VERSION "created by canmatrix"

NS_ :

BS_:

BU_: DiagTool_OBD1 DiwaNXT EBS IRCS MulticII NBM VCM ETS NODE_45 FCCU DICO SGW2 HV_BOX ADCU AEBS DTCO MBMS SGW TPMS ACU CAID2 ELC5_Fr ELC5_Rr PredictiveVirtualNode2 BPU_3 Servo_dir_Turolla PCM NODE_90 NODE_91 NODE_92 RSRRM FCU DSE_VirtualNode2 DSE_VirtualNode40 DSE_VirtualNode38 DSE_VirtualNode49 DSE_VirtualNode48 DSE_VirtualNode39 DSE_VirtualNode37 DSE_VirtualNode36 BSM_B8 BPU_2 DSE_VirtualNode35 DSE_VirtualNode34 RADAR_ACC DSE_VirtualNode33 DSE_VirtualNode41 NODE_BE DSE_VirtualNode32 DSE_VirtualNode4 BSM_C0 BPU_1 DSE_VirtualNode31 DSE_VirtualNode29 DSE_VirtualNode28 MCDS DSE_VirtualNode44 DSE_VirtualNode27 DSE_VirtualNode26 BSM_C8 ALM DSE_VirtualNode25 DSE_VirtualNode50 DSE_VirtualNode47 DSE_VirtualNode46 DSE_VirtualNode23 DSE_VirtualNode51 ScanTool DSE_VirtualNode22 DSE_VirtualNode21 AePTO DC_VirtualNode1 DSE_VirtualNode43 MCSL DSE_VirtualNode1 DSE_VirtualNode42 PredictiveVirtualNode3 DSE_VirtualNode20 DSE_VirtualNode19 DSE_VirtualNode18 DSE_VirtualNode17 DSE_VirtualNode16 DSE_VirtualNode15 NODE_F9 DiagTool DSE_VirtualNode14 DSE_VirtualNode13 DSE_VirtualNode12 DSE_VirtualNode11 DSE_VirtualNode10 DSE_VirtualNode9 DSE_VirtualNode8 DSE_VirtualNode7 DSE_VirtualNode6 Mirror DSE_VirtualNode5 SAS DC_VirtualNode2 PredictiveVirtualNode1 DSE_VirtualNode45 ELFA3 EM_PTO RM CANAIR SWI

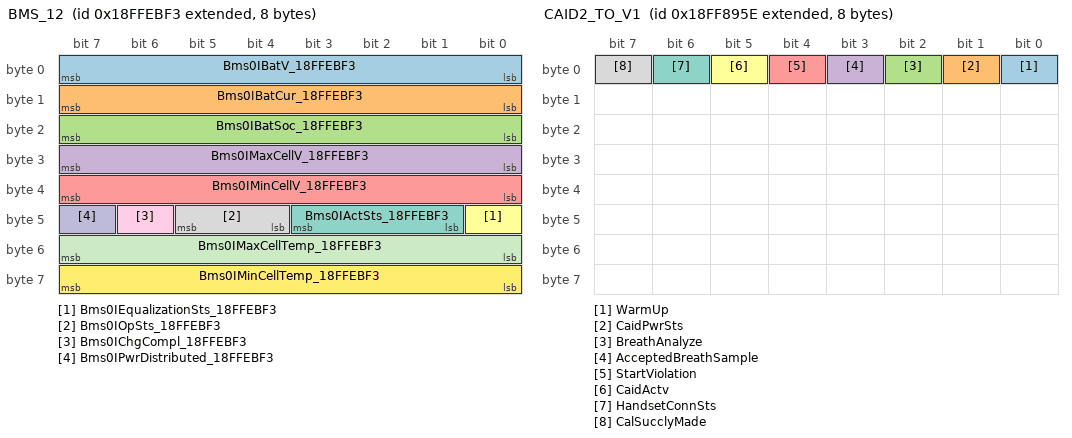
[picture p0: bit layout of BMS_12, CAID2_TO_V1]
BO_ 2566908915 BMS_12: 8 MBMS
 SG_ Bms0IBatV_18FFEBF3 : 0|8@1+ (3.4,0) [0|850] "V"  PCM
 SG_ Bms0IBatCur_18FFEBF3 : 8|8@1+ (4,-500) [-500|500] "A"  PCM
 SG_ Bms0IBatSoc_18FFEBF3 : 16|8@1+ (0.4,0) [0|100] "%"  PCM
 SG_ Bms0IMaxCellV_18FFEBF3 : 24|8@1+ (20,0) [0|5000] "Mv"  PCM
 SG_ Bms0IMinCellV_18FFEBF3 : 32|8@1+ (20,0) [0|5000] "Mv"  PCM
 SG_ Bms0IEqualizationSts_18FFEBF3 : 40|1@1+ (1,0) [0|1] ""  PCM
 SG_ Bms0IActSts_18FFEBF3 : 41|3@1+ (1,0) [0|7] ""  PCM
 SG_ Bms0IOpSts_18FFEBF3 : 44|2@1+ (1,0) [0|3] ""  PCM
 SG_ Bms0IChgCompl_18FFEBF3 : 46|1@1+ (1,0) [0|1] ""  PCM
 SG_ Bms0IPwrDistributed_18FFEBF3 : 47|1@1+ (1,0) [0|1] ""  PCM
 SG_ Bms0IMaxCellTemp_18FFEBF3 : 48|8@1+ (1,-40) [-40|210] " °C"  PCM
 SG_ Bms0IMinCellTemp_18FFEBF3 : 56|8@1+ (1,-40) [-40|210] " °C"  PCM

BO_ 2566883678 CAID2_TO_V1: 8 CAID2
 SG_ WarmUp : 0|1@1+ (1,0) [0|1] ""  PCM
 SG_ CaidPwrSts : 1|1@1+ (1,0) [0|1] ""  PCM
 SG_ BreathAnalyze : 2|1@1+ (1,0) [0|1] ""  PCM
 SG_ AcceptedBreathSample : 3|1@1+ (1,0) [0|1] ""  PCM
 SG_ StartViolation : 4|1@1+ (1,0) [0|1] ""  PCM
 SG_ CaidActv : 5|1@1+ (1,0) [0|1] ""  PCM
 SG_ HandsetConnSts : 6|1@1+ (1,0) [0|1] ""  PCM
 SG_ CalSucclyMade : 7|1@1+ (1,0) [0|1] ""  PCM

BO_ 2566884190 CAID2_TO_V3: 8 CAID2
 SG_ DeferredData : 48|8@1+ (1,0) [0|250] ""  PCM

BO_ 2566843648 CCSS_00: 8 DiagTool_OBD1
 SG_ MaxVsl : 0|8@1+ (1,0) [0|250] "km/h"  PCM
 SG_ DcdcCurSetPnt24VSide : 56|8@1+ (1,0) [0|250] "A"  PCM

BO_ 2566843676 CCSS_1C: 8 PCM
 SG_ MaxVsl_18FEED1C : 0|8@1+ (1,0) [0|250] "km/h" Vector__XXX

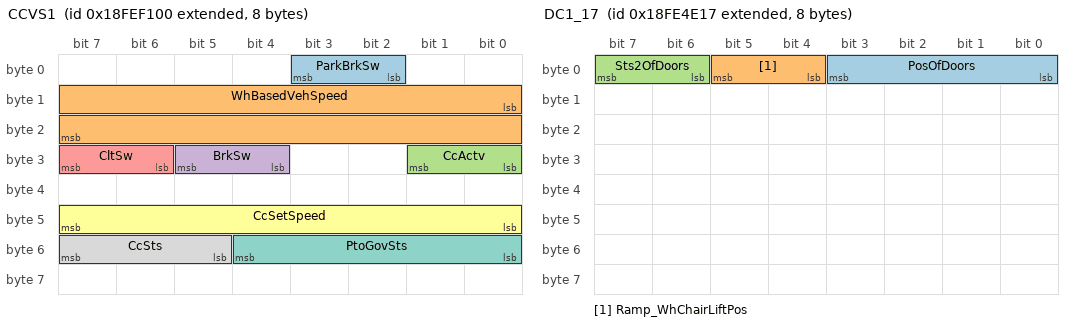
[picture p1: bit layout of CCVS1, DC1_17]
BO_ 2566844672 CCVS1: 8 DiagTool_OBD1
 SG_ ParkBrkSw : 2|2@1+ (1,0) [0|3] ""  PCM
 SG_ WhBasedVehSpeed : 8|16@1+ (0.00390625,0) [0|250] "km/h"  PCM
 SG_ CcActv : 24|2@1+ (1,0) [0|3] ""  PCM
 SG_ BrkSw : 28|2@1+ (1,0) [0|3] ""  PCM
 SG_ CltSw : 30|2@1+ (1,0) [0|3] ""  PCM
 SG_ CcSetSpeed : 40|8@1+ (1,0) [0|250] "km/h"  PCM
 SG_ PtoGovSts : 48|5@1+ (1,0) [0|31] ""  PCM
 SG_ CcSts : 53|3@1+ (1,0) [0|7] ""  PCM

BO_ 2566890313 ChargerFaults: 8 FCCU
 SG_ LastStopCause : 24|8@1+ (1,0) [0|250] ""  PCM
 SG_ BefLastStopCause : 32|8@1+ (1,0) [0|250] ""  PCM

BO_ 2566843164 CI_1C: 609 PCM
 SG_ Make : 0|8@1+ (1,0) [0|255] "ASCII" Vector__XXX
 SG_ Model : 8|8@1+ (1,0) [0|255] "ASCII" Vector__XXX
 SG_ Sn : 16|8@1+ (1,0) [0|255] "ASCII" Vector__XXX
 SG_ UnitNumPwrUnit : 24|8@1+ (1,0) [0|255] "ASCII" Vector__XXX

BO_ 2566843165 CI_1D: 609 SGW
 SG_ Make_18FEEB1D : 0|8@1+ (1,0) [0|255] "ASCII"  PCM
 SG_ Model_18FEEB1D : 8|8@1+ (1,0) [0|255] "ASCII"  PCM
 SG_ Sn_18FEEB1D : 16|8@1+ (1,0) [0|255] "ASCII"  PCM
 SG_ UnitNumPwrUnit_18FEEB1D : 24|8@1+ (1,0) [0|255] "ASCII"  PCM

BO_ 2566843230 CI_5E: 609 CAID2
 SG_ Model_18FEEB5E : 8|8@1+ (1,0) [0|255] "ASCII"  PCM

BO_ 2566865139 Clim_LTO_Sts: 8 MBMS
 SG_ CoolSts : 4|4@1+ (1,0) [0|7] ""  PCM

BO_ 2566811659 CVW_0B: 8 EBS
 SG_ Gcvw : 16|16@1+ (10,0) [0|642550] "kg"  PCM

BO_ 2566811695 CVW_2F: 8 ELC5_Fr
 SG_ Gcvw_18FE702F : 16|16@1+ (10,0) [0|642550] "kg"  PCM

BO_ 2566802967 DC1_17: 8 MulticII
 SG_ PosOfDoors : 0|4@1+ (1,0) [0|15] ""  PCM
 SG_ Ramp_WhChairLiftPos : 4|2@1+ (1,0) [0|3] ""  PCM
 SG_ Sts2OfDoors : 6|2@1+ (1,0) [0|3] ""  PCM

BO_ 2566759703 DC2_17: 8 MulticII
 SG_ LckStsOfDoor1 : 0|2@1+ (1,0) [0|3] ""  PCM
 SG_ OpenStsOfDoor1 : 2|2@1+ (1,0) [0|3] ""  PCM
 SG_ EnaStsOfDoor1 : 4|2@1+ (1,0) [0|3] ""  PCM
 SG_ LckStsOfDoor2 : 6|2@1+ (1,0) [0|3] ""  PCM
 SG_ OpenStsOfDoor2 : 8|2@1+ (1,0) [0|3] ""  PCM
 SG_ EnaStsOfDoor2 : 10|2@1+ (1,0) [0|3] ""  PCM
 SG_ LckStsOfDoor3 : 12|2@1+ (1,0) [0|3] ""  PCM
 SG_ OpenStsOfDoor3 : 14|2@1+ (1,0) [0|3] ""  PCM
 SG_ EnaStsOfDoor3 : 16|2@1+ (1,0) [0|3] ""  PCM
 SG_ LckStsOfDoor4 : 18|2@1+ (1,0) [0|3] ""  PCM
 SG_ OpenStsOfDoor4 : 20|2@1+ (1,0) [0|3] ""  PCM
 SG_ EnaStsOfDoor4 : 22|2@1+ (1,0) [0|3] ""  PCM
 SG_ LckStsOfDoor5 : 24|2@1+ (1,0) [0|3] ""  PCM
 SG_ OpenStsOfDoor5 : 26|2@1+ (1,0) [0|3] ""  PCM
 SG_ EnaStsOfDoor5 : 28|2@1+ (1,0) [0|3] ""  PCM
 SG_ LckStsOfDoor6 : 30|2@1+ (1,0) [0|3] ""  PCM
 SG_ OpenStsOfDoor6 : 32|2@1+ (1,0) [0|3] ""  PCM
 SG_ EnaStsOfDoor6 : 34|2@1+ (1,0) [0|3] ""  PCM
 SG_ LckStsOfDoor7 : 36|2@1+ (1,0) [0|3] ""  PCM
 SG_ OpenStsOfDoor7 : 38|2@1+ (1,0) [0|3] ""  PCM
 SG_ EnaStsOfDoor7 : 40|2@1+ (1,0) [0|3] ""  PCM
 SG_ LckStsOfDoor8 : 42|2@1+ (1,0) [0|3] ""  PCM
 SG_ OpenStsOfDoor8 : 44|2@1+ (1,0) [0|3] ""  PCM
 SG_ EnaStsOfDoor8 : 46|2@1+ (1,0) [0|3] ""  PCM
 SG_ LckStsOfDoor9 : 48|2@1+ (1,0) [0|3] ""  PCM
 SG_ OpenStsOfDoor9 : 50|2@1+ (1,0) [0|3] ""  PCM
 SG_ EnaStsOfDoor9 : 52|2@1+ (1,0) [0|3] ""  PCM
 SG_ LckStsOfDoor10 : 54|2@1+ (1,0) [0|3] ""  PCM
 SG_ OpenStsOfDoor10 : 56|2@1+ (1,0) [0|3] ""  PCM
 SG_ EnaStsOfDoor10 : 58|2@1+ (1,0) [0|3] ""  PCM

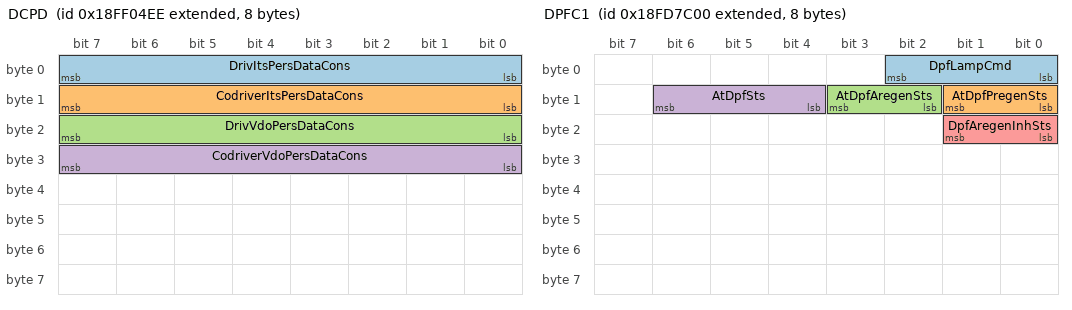
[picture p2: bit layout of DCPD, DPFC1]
BO_ 2566849774 DCPD: 8 DTCO
 SG_ DrivItsPersDataCons : 0|8@1+ (1,0) [0|250] ""  PCM
 SG_ CodriverItsPersDataCons : 8|8@1+ (1,0) [0|250] ""  PCM
 SG_ DrivVdoPersDataCons : 16|8@1+ (1,0) [0|250] ""  PCM
 SG_ CodriverVdoPersDataCons : 24|8@1+ (1,0) [0|250] ""  PCM

BO_ 2566847521 DD1_21: 8 NBM
 SG_ FuelLev1 : 8|8@1+ (0.4,0) [0|100] "%"  PCM

BO_ 2566810606 DI_EE: 40 DTCO
 SG_ Driv1Id : 0|8@1+ (1,0) [0|255] "ASCII"  PCM
 SG_ Driv2Id : 8|8@1+ (1,0) [0|255] "ASCII"  PCM

BO_ 2566834688 DM01_00: 82 DiagTool_OBD1
 SG_ ProtLamp : 0|2@1+ (1,0) [0|3] ""  PCM

BO_ 2566834691 DM01_03: 42 DiwaNXT
 SG_ ProtLamp_18FECA03 : 0|2@1+ (1,0) [0|3] ""  PCM

BO_ 2566834699 DM01_0B: 42 EBS
 SG_ ProtLamp_18FECA0B : 0|2@1+ (1,0) [0|3] ""  PCM

BO_ 2566834704 DM01_10: 66 IRCS
 SG_ ProtLamp_18FECA10 : 0|2@1+ (1,0) [0|3] ""  PCM

BO_ 2566834711 DM01_17: 82 MulticII
 SG_ ProtLamp_18FECA17 : 0|2@1+ (1,0) [0|3] ""  PCM

BO_ 2566834716 DM01_1C: 42 PCM
 SG_ ProtLamp_18FECA1C : 0|2@1+ (1,0) [0|3] "" Vector__XXX

BO_ 2566834717 DM01_1D: 42 SGW
 SG_ ProtLamp_18FECA1D : 0|2@1+ (1,0) [0|3] ""  PCM

BO_ 2566834721 DM01_21: 42 NBM
 SG_ ProtLamp_18FECA21 : 0|2@1+ (1,0) [0|3] ""  PCM

BO_ 2566834727 DM01_27: 42 VCM
 SG_ ProtLamp_18FECA27 : 0|2@1+ (1,0) [0|3] ""  PCM

BO_ 2566834734 DM01_2E: 42 Servo_dir_Turolla
 SG_ ProtLamp_18FECA2E : 0|2@1+ (1,0) [0|3] ""  PCM

BO_ 2566834735 DM01_2F: 42 ELC5_Fr
 SG_ ProtLamp_18FECA2F : 0|2@1+ (1,0) [0|3] ""  PCM

BO_ 2566834739 DM01_33: 42 TPMS
 SG_ ProtLamp_18FECA33 : 0|2@1+ (1,0) [0|3] ""  PCM

BO_ 2566834744 DM01_38: 42 ETS
 SG_ ProtLamp_18FECA38 : 0|2@1+ (1,0) [0|3] ""  PCM

BO_ 2566834752 DM01_40: 42 ELC5_Rr
 SG_ ProtLamp_18FECA40 : 0|2@1+ (1,0) [0|3] ""  PCM

BO_ 2566834761 DM01_49: 42 FCCU
 SG_ ProtLamp_18FECA49 : 0|2@1+ (1,0) [0|3] ""  PCM

BO_ 2566834762 DM01_4A: 42 PCM
 SG_ ProtLamp_18FECA4A : 0|2@1+ (1,0) [0|3] "" Vector__XXX

BO_ 2566834778 DM01_5A: 42 DICO
 SG_ ProtLamp_18FECA5A : 0|2@1+ (1,0) [0|3] ""  PCM

BO_ 2566834782 DM01_5E: 42 CAID2
 SG_ ProtLamp_18FECA5E : 0|2@1+ (1,0) [0|3] ""  PCM

BO_ 2566834814 DM01_7E: 42 SGW2
 SG_ ProtLamp_18FECA7E : 0|2@1+ (1,0) [0|3] ""  PCM

BO_ 2566834832 DM01_90: 42 NODE_90
 SG_ ProtLamp_18FECA90 : 0|2@1+ (1,0) [0|3] ""  PCM

BO_ 2566834833 DM01_91: 42 NODE_91
 SG_ ProtLamp_18FECA91 : 0|2@1+ (1,0) [0|3] ""  PCM

BO_ 2566834834 DM01_92: 42 NODE_92
 SG_ ProtLamp_18FECA92 : 0|2@1+ (1,0) [0|3] ""  PCM

BO_ 2566834844 DM01_9C: 42 RSRRM
 SG_ ProtLamp_18FECA9C : 0|2@1+ (1,0) [0|3] ""  PCM

BO_ 2566834846 DM01_9E: 42 ADCU
 SG_ ProtLamp_18FECA9E : 0|2@1+ (1,0) [0|3] ""  PCM

BO_ 2566834848 DM01_A0: 42 AEBS
 SG_ ProtLamp_18FECAA0 : 0|2@1+ (1,0) [0|3] ""  PCM

BO_ 2566834882 DM01_C2: 18 FCU
 SG_ ProtLamp_18FECAC2 : 0|2@1+ (1,0) [0|3] ""  PCM

BO_ 2566834920 DM01_E8: 42 DSE_VirtualNode2
 SG_ ProtLamp_18FECAE8 : 0|2@1+ (1,0) [0|3] ""  PCM

BO_ 2566834926 DM01_EE: 42 DTCO
 SG_ ProtLamp_18FECAEE : 0|2@1+ (1,0) [0|3] ""  PCM

BO_ 2566834931 DM01_F3: 42 MBMS
 SG_ ProtLamp_18FECAF3 : 0|2@1+ (1,0) [0|3] ""  PCM

BO_ 2566834972 DM02_1C: 42 PCM
 SG_ ProtLamp_18FECB1C : 0|2@1+ (1,0) [0|3] "" Vector__XXX

BO_ 2566834973 DM02_1D: 42 SGW
 SG_ ProtLamp_18FECB1D : 0|2@1+ (1,0) [0|3] ""  PCM

BO_ 2566835102 DM02_9E: 42 ADCU
 SG_ ProtLamp_18FECB9E : 0|2@1+ (1,0) [0|3] ""  PCM

BO_ 2566835485 DM04_1D: 250 SGW
 SG_ FfLen1 : 0|8@1+ (1,0) [0|255] "count"  PCM

BO_ 2566835614 DM04_9E: 250 ADCU
 SG_ FfLen1_18FECD9E : 0|8@1+ (1,0) [0|255] "count"  PCM

BO_ 2633943642 DM1_5A_P7: 42 DICO
 SG_ ProtLamp_1CFECA5A : 0|2@1+ (1,0) [0|3] ""  PCM

BO_ 2633943680 DM1_80_P7: 42 HV_BOX
 SG_ ProtLamp_1CFECA80 : 0|2@1+ (1,0) [0|3] ""  PCM

BO_ 2566856773 DoorsStat: 8 NODE_45
 SG_ DoorId M : 0|8@1+ (1,0) [0|7] ""  PCM
 SG_ DoorCnt0 m0 : 8|24@1+ (1,0) [0|6291455] "Cy"  PCM
 SG_ DoorCnt1 m1 : 8|24@1+ (1,0) [0|6291455] "Cy"  PCM
 SG_ DoorCnt2 m2 : 8|24@1+ (1,0) [0|6291455] "Cy"  PCM
 SG_ DoorCnt3 m3 : 8|24@1+ (1,0) [0|6291455] "Cy"  PCM
 SG_ DoorCnt4 m4 : 8|24@1+ (1,0) [0|6291455] "Cy"  PCM
 SG_ DoorClosTime0 m0 : 32|8@1+ (100,0) [0|20000] "ms"  PCM
 SG_ DoorClosTime1 m1 : 32|8@1+ (100,0) [0|20000] "ms"  PCM
 SG_ DoorClosTime2 m2 : 32|8@1+ (100,0) [0|20000] "ms"  PCM
 SG_ DoorClosTime3 m3 : 32|8@1+ (100,0) [0|20000] "ms"  PCM
 SG_ DoorClosTime4 m4 : 32|8@1+ (100,0) [0|20000] "ms"  PCM

BO_ 2566749184 DPFC1: 8 DiagTool_OBD1
 SG_ DpfLampCmd : 0|3@1+ (1,0) [0|7] ""  PCM
 SG_ AtDpfPregenSts : 8|2@1+ (1,0) [0|3] ""  PCM
 SG_ AtDpfAregenSts : 10|2@1+ (1,0) [0|3] ""  PCM
 SG_ AtDpfSts : 12|3@1+ (1,0) [0|7] ""  PCM
 SG_ DpfAregenInhSts : 16|2@1+ (1,0) [0|3] ""  PCM

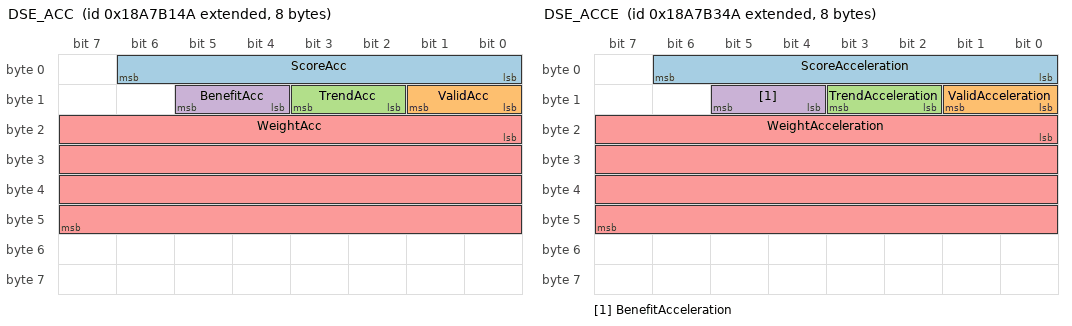
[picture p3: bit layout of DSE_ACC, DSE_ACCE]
BO_ 2561126730 DSE_ACC: 8 PCM
 SG_ ScoreAcc : 0|7@1+ (1,-1) [-1|126] ""  DSE_VirtualNode40
 SG_ ValidAcc : 8|2@1+ (1,0) [0|3] ""  DSE_VirtualNode40
 SG_ TrendAcc : 10|2@1+ (1,-1) [-1|2] ""  DSE_VirtualNode40
 SG_ BenefitAcc : 12|2@1+ (1,0) [0|3] ""  DSE_VirtualNode40
 SG_ WeightAcc : 16|32@1+ (1,-1) [-1|4294967294] ""  DSE_VirtualNode40

BO_ 2561126986 DSE_ACC_DBG: 8 PCM
 SG_ EvaluatedSamplesAcc : 0|16@1+ (1,-1) [-1|65534] ""  DSE_VirtualNode38
 SG_ EventAcc : 16|2@1+ (1,0) [0|3] ""  DSE_VirtualNode38

BO_ 2561127242 DSE_ACCE: 8 PCM
 SG_ ScoreAcceleration : 0|7@1+ (1,-1) [-1|126] ""  DSE_VirtualNode49
 SG_ ValidAcceleration : 8|2@1+ (1,0) [0|3] ""  DSE_VirtualNode49
 SG_ TrendAcceleration : 10|2@1+ (1,-1) [-1|2] ""  DSE_VirtualNode49
 SG_ BenefitAcceleration : 12|2@1+ (1,0) [0|3] ""  DSE_VirtualNode49
 SG_ WeightAcceleration : 16|32@1+ (1,-1) [-1|4294967294] ""  DSE_VirtualNode49

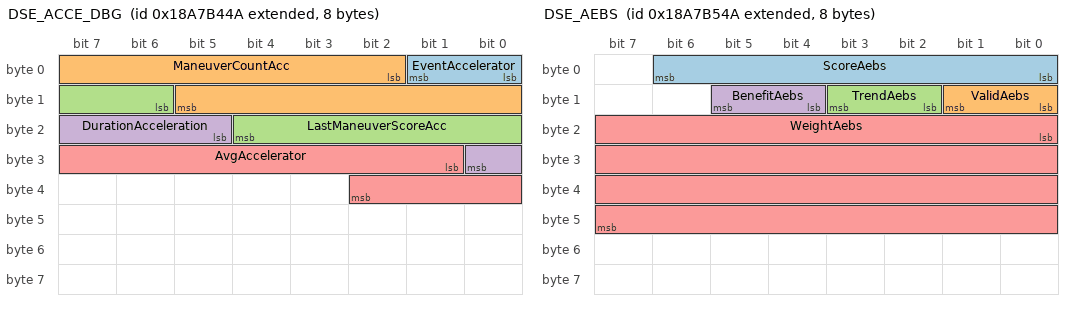
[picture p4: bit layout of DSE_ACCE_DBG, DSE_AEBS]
BO_ 2561127498 DSE_ACCE_DBG: 8 PCM
 SG_ EventAccelerator : 0|2@1+ (1,0) [0|3] ""  DSE_VirtualNode48
 SG_ ManeuverCountAcc : 2|12@1+ (1,-1) [-1|4094] "Count"  DSE_VirtualNode48
 SG_ LastManeuverScoreAcc : 14|7@1+ (1,-1) [-1|126] "Index"  DSE_VirtualNode48
 SG_ DurationAcceleration : 21|4@1+ (1,-1) [-1|14] "s"  DSE_VirtualNode48
 SG_ AvgAccelerator : 25|10@1+ (0.1,-1) [-1|101] "%"  DSE_VirtualNode48

BO_ 2561127754 DSE_AEBS: 8 PCM
 SG_ ScoreAebs : 0|7@1+ (1,-1) [-1|126] ""  DSE_VirtualNode39
 SG_ ValidAebs : 8|2@1+ (1,0) [0|3] ""  DSE_VirtualNode39
 SG_ TrendAebs : 10|2@1+ (1,-1) [-1|2] ""  DSE_VirtualNode39
 SG_ BenefitAebs : 12|2@1+ (1,0) [0|3] ""  DSE_VirtualNode39
 SG_ WeightAebs : 16|32@1+ (1,-1) [-1|4294967294] ""  DSE_VirtualNode39

BO_ 2561128010 DSE_AEBS_DBG: 8 PCM
 SG_ EvaluatedSamplesAebs : 0|16@1+ (1,-1) [-1|65534] ""  DSE_VirtualNode37
 SG_ EventAebs : 16|2@1+ (1,0) [0|3] ""  DSE_VirtualNode37

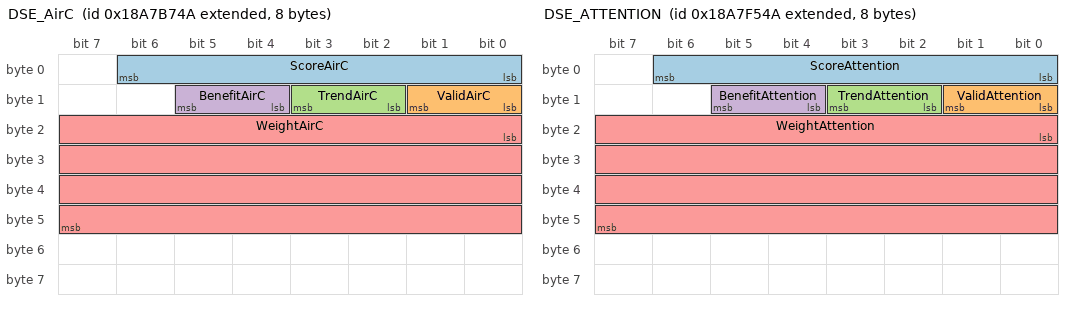
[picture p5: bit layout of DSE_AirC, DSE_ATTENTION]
BO_ 2561128266 DSE_AirC: 8 PCM
 SG_ ScoreAirC : 0|7@1+ (1,-1) [-1|126] ""  DSE_VirtualNode36
 SG_ ValidAirC : 8|2@1+ (1,0) [0|3] ""  DSE_VirtualNode36
 SG_ TrendAirC : 10|2@1+ (1,-1) [-1|2] ""  DSE_VirtualNode36
 SG_ BenefitAirC : 12|2@1+ (1,0) [0|3] ""  DSE_VirtualNode36
 SG_ WeightAirC : 16|32@1+ (1,-1) [-1|4294967294] ""  DSE_VirtualNode36

BO_ 2561128522 DSE_AirC_DBG: 8 PCM
 SG_ EvaluatedSamplesAirC : 0|16@1+ (1,-1) [-1|65534] ""  BSM_B8

BO_ 2561144138 DSE_ATTENTION: 8 PCM
 SG_ ScoreAttention : 0|7@1+ (1,-1) [-1|126] ""  BPU_2
 SG_ ValidAttention : 8|2@1+ (1,0) [0|3] ""  BPU_2
 SG_ TrendAttention : 10|2@1+ (1,-1) [-1|2] ""  BPU_2
 SG_ BenefitAttention : 12|2@1+ (1,0) [0|3] ""  BPU_2
 SG_ WeightAttention : 16|32@1+ (1,-1) [-1|4294967294] ""  BPU_2

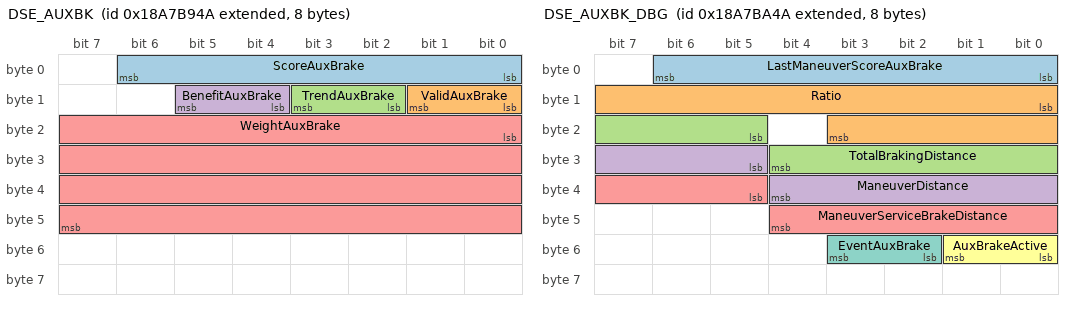
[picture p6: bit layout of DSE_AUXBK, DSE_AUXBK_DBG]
BO_ 2561128778 DSE_AUXBK: 8 PCM
 SG_ ScoreAuxBrake : 0|7@1+ (1,-1) [-1|126] ""  DSE_VirtualNode35
 SG_ ValidAuxBrake : 8|2@1+ (1,0) [0|3] ""  DSE_VirtualNode35
 SG_ TrendAuxBrake : 10|2@1+ (1,-1) [-1|2] ""  DSE_VirtualNode35
 SG_ BenefitAuxBrake : 12|2@1+ (1,0) [0|3] ""  DSE_VirtualNode35
 SG_ WeightAuxBrake : 16|32@1+ (1,-1) [-1|4294967294] ""  DSE_VirtualNode35

BO_ 2561129034 DSE_AUXBK_DBG: 8 PCM
 SG_ LastManeuverScoreAuxBrake : 0|7@1+ (1,-1) [-1|126] "Index"  DSE_VirtualNode34
 SG_ Ratio : 8|12@1+ (0.1,-1) [-1|408] ""  DSE_VirtualNode34
 SG_ TotalBrakingDistance : 21|8@1+ (1,-1) [-1|254] "m"  DSE_VirtualNode34
 SG_ ManeuverDistance : 29|8@1+ (1,-1) [-1|254] "m"  DSE_VirtualNode34
 SG_ ManeuverServiceBrakeDistance : 37|8@1+ (1,0) [0|254] "m"  DSE_VirtualNode34
 SG_ AuxBrakeActive : 48|2@1+ (1,0) [0|3] ""  DSE_VirtualNode34
 SG_ EventAuxBrake : 50|2@1+ (1,0) [0|3] ""  DSE_VirtualNode34

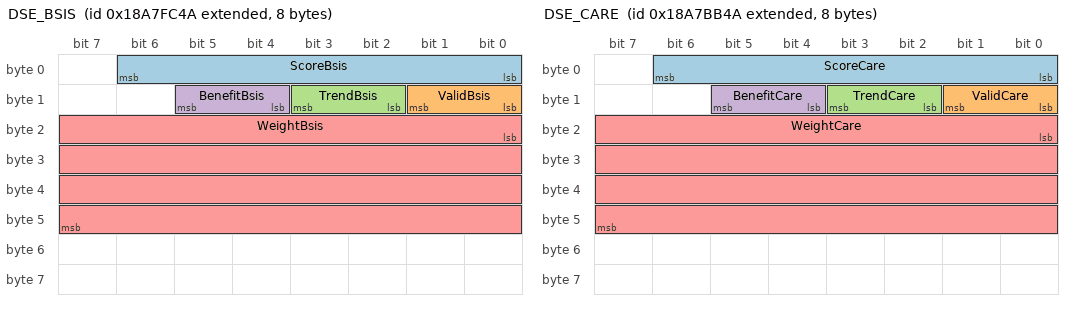
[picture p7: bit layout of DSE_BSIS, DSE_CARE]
BO_ 2561145930 DSE_BSIS: 8 PCM
 SG_ ScoreBsis : 0|7@1+ (1,-1) [-1|126] ""  RADAR_ACC
 SG_ ValidBsis : 8|2@1+ (1,0) [0|3] ""  RADAR_ACC
 SG_ TrendBsis : 10|2@1+ (1,-1) [-1|2] ""  RADAR_ACC
 SG_ BenefitBsis : 12|2@1+ (1,0) [0|3] ""  RADAR_ACC
 SG_ WeightBsis : 16|32@1+ (1,-1) [-1|4294967294] ""  RADAR_ACC

BO_ 2561129290 DSE_CARE: 8 PCM
 SG_ ScoreCare : 0|7@1+ (1,-1) [-1|126] "Index"  DSE_VirtualNode33
 SG_ ValidCare : 8|2@1+ (1,0) [0|3] ""  DSE_VirtualNode33
 SG_ TrendCare : 10|2@1+ (1,-1) [-1|2] ""  DSE_VirtualNode33
 SG_ BenefitCare : 12|2@1+ (1,0) [0|3] ""  DSE_VirtualNode33
 SG_ WeightCare : 16|32@1+ (1,-1) [-1|4294967294] ""  DSE_VirtualNode33

BO_ 2561129546 DSE_CMD: 8 PCM
 SG_ ResetEcoA : 0|2@1+ (1,0) [0|3] ""  DSE_VirtualNode41
 SG_ ResetEcoB : 2|2@1+ (1,0) [0|3] ""  DSE_VirtualNode41

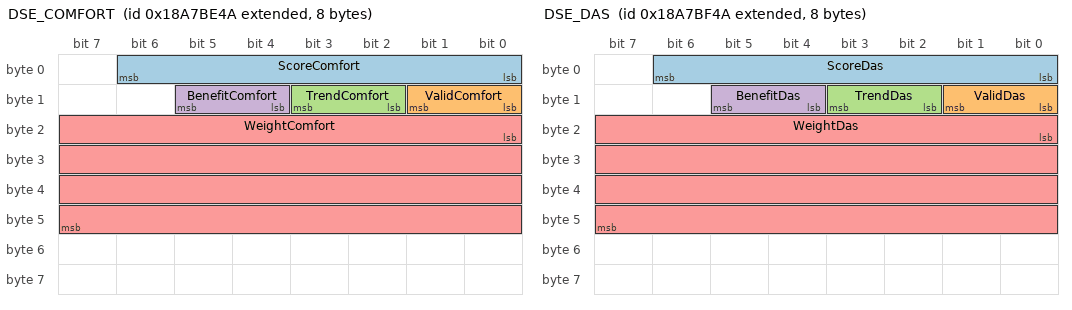
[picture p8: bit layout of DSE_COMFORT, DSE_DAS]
BO_ 2561130058 DSE_COMFORT: 8 PCM
 SG_ ScoreComfort : 0|7@1+ (1,0) [0|100] "%"  NODE_BE
 SG_ ValidComfort : 8|2@1+ (1,0) [0|3] ""  NODE_BE
 SG_ TrendComfort : 10|2@1+ (1,-1) [-1|2] ""  NODE_BE
 SG_ BenefitComfort : 12|2@1+ (1,0) [0|3] ""  NODE_BE
 SG_ WeightComfort : 16|32@1+ (1,-1) [-1|4294967294] ""  NODE_BE

BO_ 2561129802 DSE_CURNT: 8 PCM
 SG_ OdometerTripCurrent : 0|32@1+ (5,-1) [-1|21474836474] "m"  DSE_VirtualNode32
 SG_ TimeStampCurrent : 32|32@1+ (1,946684800) [946684800|5241652095] "Date"  DSE_VirtualNode32

BO_ 2561130314 DSE_DAS: 8 PCM
 SG_ ScoreDas : 0|7@1+ (1,-1) [-1|126] "Index"  DSE_VirtualNode4
 SG_ ValidDas : 8|2@1+ (1,0) [0|3] ""  DSE_VirtualNode4
 SG_ TrendDas : 10|2@1+ (1,-1) [-1|2] ""  DSE_VirtualNode4
 SG_ BenefitDas : 12|2@1+ (1,0) [0|3] ""  DSE_VirtualNode4
 SG_ WeightDas : 16|32@1+ (1,-1) [-1|4294967294] ""  DSE_VirtualNode4

BO_ 2561140554 DSE_DAS_DBG: 8 PCM
 SG_ EvaluatedSamplesDas : 0|16@1+ (1,-1) [-1|65534] ""  ACU
 SG_ EventDas : 16|2@1+ (1,0) [0|3] ""  ACU

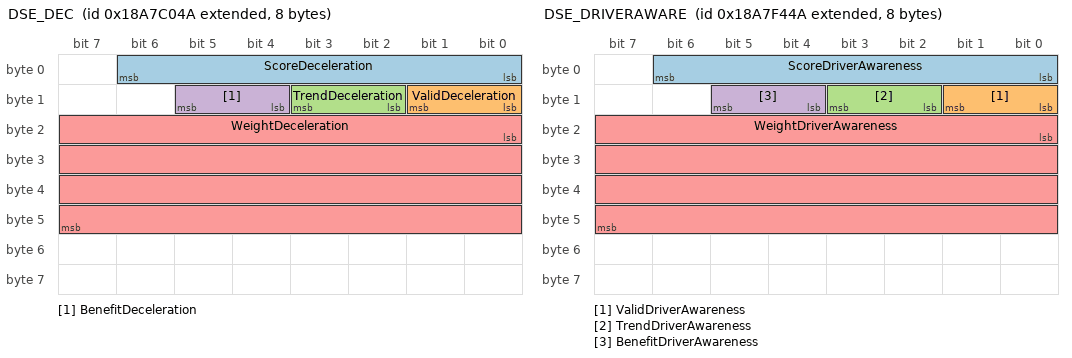
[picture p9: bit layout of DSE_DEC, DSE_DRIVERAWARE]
BO_ 2561130570 DSE_DEC: 8 PCM
 SG_ ScoreDeceleration : 0|7@1+ (1,-1) [-1|126] "Index"  BSM_C0
 SG_ ValidDeceleration : 8|2@1+ (1,0) [0|3] ""  BSM_C0
 SG_ TrendDeceleration : 10|2@1+ (1,-1) [-1|2] ""  BSM_C0
 SG_ BenefitDeceleration : 12|2@1+ (1,0) [0|3] ""  BSM_C0
 SG_ WeightDeceleration : 16|32@1+ (1,-1) [-1|4294967294] ""  BSM_C0

BO_ 2561143882 DSE_DRIVERAWARE: 8 PCM
 SG_ ScoreDriverAwareness : 0|7@1+ (1,-1) [-1|126] "Index"  BPU_1
 SG_ ValidDriverAwareness : 8|2@1+ (1,0) [0|3] ""  BPU_1
 SG_ TrendDriverAwareness : 10|2@1+ (1,-1) [-1|2] ""  BPU_1
 SG_ BenefitDriverAwareness : 12|2@1+ (1,0) [0|3] ""  BPU_1
 SG_ WeightDriverAwareness : 16|32@1+ (1,-1) [-1|4294967294] ""  BPU_1

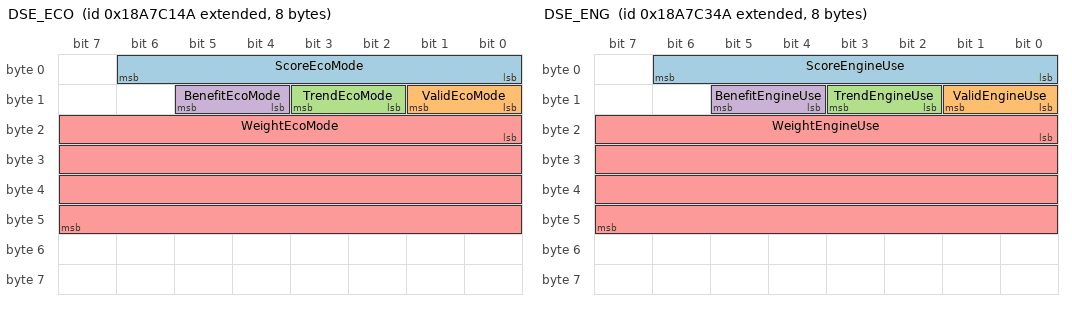
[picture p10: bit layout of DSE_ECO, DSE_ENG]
BO_ 2561130826 DSE_ECO: 8 PCM
 SG_ ScoreEcoMode : 0|7@1+ (1,-1) [-1|126] "Index"  DSE_VirtualNode31
 SG_ ValidEcoMode : 8|2@1+ (1,0) [0|3] ""  DSE_VirtualNode31
 SG_ TrendEcoMode : 10|2@1+ (1,-1) [-1|2] ""  DSE_VirtualNode31
 SG_ BenefitEcoMode : 12|2@1+ (1,0) [0|3] ""  DSE_VirtualNode31
 SG_ WeightEcoMode : 16|32@1+ (1,-1) [-1|4294967294] ""  DSE_VirtualNode31

BO_ 2561131082 DSE_ECO_DBG: 8 PCM
 SG_ EvaluatedSamplesEcoMode : 0|16@1+ (1,-1) [-1|65534] ""  FCU

BO_ 2561131338 DSE_ENG: 8 PCM
 SG_ ScoreEngineUse : 0|7@1+ (1,-1) [-1|126] "Index"  DSE_VirtualNode29
 SG_ ValidEngineUse : 8|2@1+ (1,0) [0|3] ""  DSE_VirtualNode29
 SG_ TrendEngineUse : 10|2@1+ (1,-1) [-1|2] ""  DSE_VirtualNode29
 SG_ BenefitEngineUse : 12|2@1+ (1,0) [0|3] ""  DSE_VirtualNode29
 SG_ WeightEngineUse : 16|32@1+ (1,-1) [-1|4294967294] ""  DSE_VirtualNode29

BO_ 2561140810 DSE_EVAL: 8 PCM
 SG_ EvaluatedMetersTrip : 0|32@1+ (1,-1) [-1|4294967294] "m"  DSE_VirtualNode2
 SG_ EvaluatedSamplesTrip : 32|32@1+ (1,-1) [-1|4294967294] ""  DSE_VirtualNode2

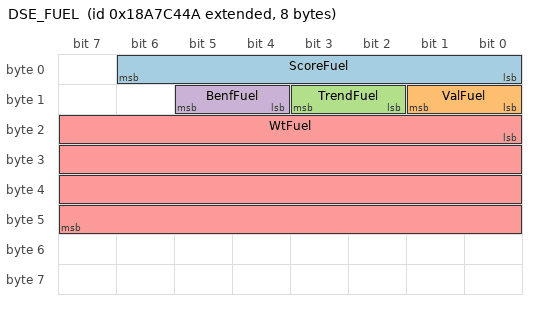
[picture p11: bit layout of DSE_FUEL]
BO_ 2561131594 DSE_FUEL: 8 PCM
 SG_ ScoreFuel : 0|7@1+ (1,-1) [-1|100] "%"  DSE_VirtualNode28
 SG_ ValFuel : 8|2@1+ (1,0) [0|3] ""  DSE_VirtualNode28
 SG_ TrendFuel : 10|2@1+ (1,-1) [-1|2] ""  DSE_VirtualNode28
 SG_ BenfFuel : 12|2@1+ (1,0) [0|3] ""  DSE_VirtualNode28
 SG_ WtFuel : 16|32@1+ (1,-1) [-1|4294967294] ""  DSE_VirtualNode28

CM_ BO_ 2566908915 "- Specific to Siemens Full Elec vehicles";
CM_ BO_ 2566843648 "- Not sent by MD1 for CNG";
CM_ SG_ 2566843648 MaxVsl "- 20 km/h in case of Creep Mode active, otherwise FFh";
CM_ SG_ 2566843648 DcdcCurSetPnt24VSide "- Used for Mild Hybrid function";
CM_ SG_ 2566843676 MaxVsl_18FEED1C "- Road Speed Limit from GPS maps
-  Type of included limits shall be defined";
CM_ BO_ 2566844672 "- ECU Sender (Tx) on VCM4 if Thermal_ VCU on Siemens electric vehicle.
-  Only on ELFA2 250K, ELFA3 250K, ELFA2 500K.
-  Only on ELFA3 500K: copy of the message read with SA=0x21 on CAN vehicle.. SA=0x00 maintained for PCM and IPM.
-  Sent on VDB for bus (TBC with ADCU requirement).
- VS2.B.SGW2..23..VDB: Used in freeze frames parameters.";
CM_ SG_ 2566844672 PtoGovSts "- CUC.C.PCM..3..TELEM: Not Available
- OVG.Mtx.FMS.4.24.Generic.FMSi: Only on Diesel/Gaz";
CM_ BO_ 2566890313 "- Specific to Siemens Full Elec vehicles. Tx by FCCU, or by VCU in case VC-VCCU. 3 bytes if sent by the FCCU, 8 bytes if sent by the supervisor in case VC-VCCU.";
CM_ SG_ 2566890313 LastStopCause "- Diag info end of charge cause (n). (case VC-VCCU only)";
CM_ SG_ 2566890313 BefLastStopCause "- Diag info end of charge cause (n-1). (case VC-VCCU only)";
CM_ BO_ 2566843164 "- Delimiter (“*”) required after each parameter, even if not used
-  Multipacket message handled by SAE Transport Protocol (J1939/21, par 5.10, Multipacket Broadcast with TP.CM/BAM, TP.DT)
-  Transport Protocol with Control Flow  (RTS, CTS, EndOfMsgAck, Conn_Abort) shall be also supported by the receiver if the multipacket message has been solicited by a Destination Specific Request
-  Variable Message Length, maximum value used for dbc generation";
CM_ SG_ 2566843164 Make "- Variable signal length, 8 bits used for dbc generation only";
CM_ SG_ 2566843164 Model "- 15+1 characters maximum_ Manufacturer assigned Component/ECU Model or P/N(CNHI Std. 18-2253)
-  Variable signal length, 8 bits used for dbc generation only";
CM_ SG_ 2566843164 Sn "- 10+1 characters maximum_ Manufacturer assigned (CNHI Std. 18-2253)
-  Optional (CNHI Std. 18-2253), delimiter only if not supported
-  Variable signal length, 8 bits used for dbc generation only";
CM_ SG_ 2566843164 UnitNumPwrUnit "- 15+1 characters maximum
-  Optional, delimiter only if not supported
-  Variable signal length, 8 bits used for dbc generation only";
CM_ BO_ 2566843165 "- Delimiter (“*”) required after each parameter, even if not used
-  Multipacket message handled by SAE Transport Protocol (J1939/21, par 5.10, Multipacket Broadcast with TP.CM/BAM, TP.DT)
-  Transport Protocol with Control Flow  (RTS, CTS, EndOfMsgAck, Conn_Abort) shall be also supported by the receiver if the multipacket message has been solicited by a Destination Specific Request
-  Variable Message Length, maximum value used for dbc generation";
CM_ SG_ 2566843165 Make_18FEEB1D "- Variable signal length, 8 bits used for dbc generation only";
CM_ SG_ 2566843165 Model_18FEEB1D "- 15+1 characters maximum_ Manufacturer assigned Component/ECU Model or P/N(CNHI Std. 18-2253)
-  Variable signal length, 8 bits used for dbc generation only";
CM_ SG_ 2566843165 Sn_18FEEB1D "- 10+1 characters maximum_ Manufacturer assigned (CNHI Std. 18-2253)
-  Optional (CNHI Std. 18-2253), delimiter only if not supported
-  Variable signal length, 8 bits used for dbc generation only";
CM_ SG_ 2566843165 UnitNumPwrUnit_18FEEB1D "- 15+1 characters maximum
-  Optional, delimiter only if not supported
-  Variable signal length, 8 bits used for dbc generation only";
CM_ BO_ 2566865139 "- Sent by the MBMS in case of batteries FORSEE (only PULSE battery).
-  Sent by the supervisor (VCU) in case of batteries Microvast. Sent by VCU if chiller Technotrans present.";
CM_ BO_ 2566811659 "- Message activated only for vehicles with Automatic Gearbox ZF Ecolife 2
-  SAE Trans.Rate=OnRequest";
CM_ SG_ 2566811659 Gcvw "- FF00 to FFFF = not available";
CM_ BO_ 2566811695 "- Message requested for DiagnosticLogger (on PCM3)";
CM_ SG_ 2566811695 Gcvw_18FE702F "- FF00 to FFFF = not available";
CM_ BO_ 2566802967 "- OVG.Mtx.FMS.4.24.Generic.FMSi: FMS Optional. Update: filled in blue (differed in according with CW/UW VDB CAN files).";
CM_ BO_ 2566759703 "- OVG.Mtx.FMS.4.24.Generic.FMSi: FMS Optional. Update: filled in blue (differed in according with CW/UW VDB CAN files).";
CM_ SG_ 2566759703 LckStsOfDoor9 "- CUC.C.PCM..3..TELEM: Not used on bus application.";
CM_ SG_ 2566759703 OpenStsOfDoor9 "- CUC.C.PCM..3..TELEM: Not used on bus application.";
CM_ SG_ 2566759703 EnaStsOfDoor9 "- CUC.C.PCM..3..TELEM: Not used on bus application.";
CM_ SG_ 2566759703 LckStsOfDoor10 "- CUC.C.PCM..3..TELEM: Not used on bus application.";
CM_ SG_ 2566759703 OpenStsOfDoor10 "- CUC.C.PCM..3..TELEM: Not used on bus application.";
CM_ SG_ 2566759703 EnaStsOfDoor10 "- CUC.C.PCM..3..TELEM: Not used on bus application.";
CM_ BO_ 2566849774 "- Update filled in acc with DTCO4.1 (New file). To be confirmed.";
CM_ BO_ 2566810606 "- * Only if the vehicle is equiped with a tachograph.
-  Multipacket message handled by SAE Transport Protocol (J1939/21, par 5.10, Multipacket Broadcast with TP.CM/BAM, TP.DT)
-  Single packet version_ in response of FMS requests every 10s (RQST_25_EE).
-  Variable Message Length, maximum value used for dbc generation";
CM_ SG_ 2566810606 Driv1Id "- Only if no driver card is present, only the two delimiters  *  have to be sent. Then, fill with FF. ASCII Example: DI = 2A 2A FF FF FF FF FF FF, 2A [hex] =  *  [ASCII]";
CM_ BO_ 2566834688 "- Multipacket message handled by SAE Transport Protocol (J1939/21, par 5.10, Multipacket Broadcast with TP.CM/BAM, TP.DT)
-  Variable Message Length, maximum value used for dbc generation";
CM_ BO_ 2566834691 "- Multipacket message handled by SAE Transport Protocol (J1939/21, par 5.10, Multipacket Broadcast with TP.CM/BAM, TP.DT)
-  Variable Message Length, maximum value used for dbc generation";
CM_ SG_ 2566834691 ProtLamp_18FECA03 "- Always 00b";
CM_ BO_ 2566834699 "- Multipacket message handled by SAE Transport Protocol (J1939/21, par 5.10, Multipacket Broadcast with TP.CM/BAM, TP.DT)
-  Variable Message Length, maximum value used for dbc generation";
CM_ BO_ 2566834711 "- Multipacket message handled by SAE Transport Protocol (J1939/21, par 5.10, Multipacket Broadcast with TP.CM/BAM, TP.DT)
-  Variable Message Length, maximum value used for dbc generation";
CM_ SG_ 2566834711 ProtLamp_18FECA17 "- Always 00b";
CM_ BO_ 2566834716 "- Multipacket message handled by SAE Transport Protocol (J1939/21, par 5.10, Multipacket Broadcast with TP.CM/BAM, TP.DT)
-  Transport Protocol Packets (TP.CM, TP.DT) Priority=7
-  Variable Message Length, maximum value used for dbc generation";
CM_ SG_ 2566834716 ProtLamp_18FECA1C "- Always 00b";
CM_ BO_ 2566834717 "- Multipacket message handled by SAE Transport Protocol (J1939/21, par 5.10, Multipacket Broadcast with TP.CM/BAM, TP.DT)
-  Variable Message Length, maximum value used for dbc generation";
CM_ SG_ 2566834717 ProtLamp_18FECA1D "- Always 00b";
CM_ BO_ 2566834721 "- Multipacket message handled by SAE Transport Protocol (J1939/21, par 5.10, Multipacket Broadcast with TP.CM/BAM, TP.DT)
-  Variable Message Length, maximum value used for dbc generation";
CM_ BO_ 2566834727 "- DM1_BMS. Multipacket message handled by SAE Transport Protocol (J1939/21, par 5.10, Multipacket Broadcast with TP.CM/BAM, TP.DT)
-  Variable Message Length, maximum value used for dbc generation.";
CM_ SG_ 2566834727 ProtLamp_18FECA27 "- Always 00b";
CM_ BO_ 2566834734 "- Full elec only.
-  Multipacket message handled by SAE Transport Protocol (J1939/21, par 5.10, Multipacket Broadcast with TP.CM/BAM, TP.DT)
-  Variable Message Length, maximum value used for dbc generation.";
CM_ BO_ 2566834735 "- Multipacket message handled by SAE Transport Protocol (J1939/21, par 5.10, Multipacket Broadcast with TP.CM/BAM, TP.DT)
-  Variable Message Length, maximum value used for dbc generation";
CM_ BO_ 2566834739 "- Multipacket message handled by SAE Transport Protocol (J1939/21, par 5.10, Multipacket Broadcast with TP.CM/BAM, TP.DT)
-  Variable Message Length, maximum value used for dbc generation";
CM_ BO_ 2566834744 "- Multipacket message handled by SAE Transport Protocol (J1939/21, par 5.10, Multipacket Broadcast with TP.CM/BAM, TP.DT)
-  Only CW Diesel.
-  Transmission Rate can be 1000 [ms].
-  Variable Message Length, maximum value used for dbc generation.";
CM_ BO_ 2566834752 "- Multipacket message handled by SAE Transport Protocol (J1939/21, par 5.10, Multipacket Broadcast with TP.CM/BAM, TP.DT)
-  Variable Message Length, maximum value used for dbc generation
- SSC2.KB.ASM..24.Rr.VDB: For Rear ELC.";
CM_ BO_ 2566834761 "- Full elec only.
-  Multipacket message handled by SAE Transport Protocol (J1939/21, par 5.10, Multipacket Broadcast with TP.CM/BAM, TP.DT)
-  Variable Message Length, maximum value used for dbc generation";
CM_ SG_ 2566834762 ProtLamp_18FECA4A "- Always 00b";
CM_ BO_ 2566834778 "- Reading of the DM1 of the DICO, and copying on the VCB (for display of traction chain fault and fleet management system or predictive maintenance).
-  Specific to Siemens Full Elec vehicles.
-  Timeout (ms): 3000 ms";
CM_ BO_ 2566834814 "- Multipacket message handled by SAE Transport Protocol (J1939/21, par 5.10, Multipacket Broadcast with TP.CM/BAM, TP.DT)
-  Variable Message Length, maximum value used for dbc generation";
CM_ BO_ 2566834832 "- SA=0x90_ ECU Sender is SRR Left Master (CAN RADAR)";
CM_ SG_ 2566834832 ProtLamp_18FECA90 "- Always 00b";
CM_ BO_ 2566834833 "- SA=0x91_ ECU Sender is SRR Right Slave (CAN RADAR)";
CM_ SG_ 2566834833 ProtLamp_18FECA91 "- Always 00b";
CM_ BO_ 2566834834 "- SA=0x92_ ECU Sender is SRR Right Master (CAN RADAR)";
CM_ SG_ 2566834834 ProtLamp_18FECA92 "- Always 00b";
CM_ BO_ 2566834844 "- SA=0x9C_ ECU Sender is SRR Front Master (CAN RADAR)";
CM_ SG_ 2566834844 ProtLamp_18FECA9C "- Always 00b";
CM_ SG_ 2566834846 ProtLamp_18FECA9E "- Always 00b";
CM_ BO_ 2566834848 "- Multipacket message handled by SAE Transport Protocol (J1939/21, par 5.10, Multipacket Broadcast with TP.CM/BAM, TP.DT)
-  SA=0xA0_ ECU Sender is MRGen21 (CAN RADAR).
-  Variable Message Length, maximum value used for dbc generation";
CM_ SG_ 2566834848 ProtLamp_18FECAA0 "- Always 00b";
CM_ BO_ 2566834920 "- SA=0xE8_ ECU Sender is SRR Left Slave (CAN RADAR)";
CM_ SG_ 2566834920 ProtLamp_18FECAE8 "- Always 00b";
CM_ BO_ 2566834931 "- Multipacket message
- BPM.Fo.MBMS....VDB: MBMS Transmission rate: 1000ms for DM1.
- BPM.M.MBMS....VDB: MBMS Transmission rate: 1000ms for DM1.";
CM_ BO_ 2566834972 "- Multipacket message handled by SAE Transport Protocol (J1939/21, par 5.10, Multipacket Broadcast with TP.CM/BAM, TP.DT)
-  Transport Protocol Packets (TP.CM, TP.DT) Priority=7
-  Transport Protocol with Control Flow  (RTS, CTS, EndOfMsgAck, Conn_Abort) shall be also supported by the receiver if the multipacket message has been solicited by a Destination Specific Request
-  Variable Message Length, maximum value used for dbc generation";
CM_ BO_ 2566834973 "- Multipacket message handled by SAE Transport Protocol (J1939/21, par 5.10, Multipacket Broadcast with TP.CM/BAM, TP.DT)
-  Transport Protocol with Control Flow  (RTS, CTS, EndOfMsgAck, Conn_Abort) shall be also supported by the receiver if the multipacket message has been solicited by a Destination Specific Request
-  Variable Message Length, maximum value used for dbc generation";
CM_ BO_ 2566835102 "- Multipacket message handled by SAE Transport Protocol (J1939/21, par 5.10, Multipacket Broadcast with TP.CM/BAM, TP.DT)
-  Transport Protocol with Control Flow  (RTS, CTS, EndOfMsgAck, Conn_Abort) shall be also supported by the receiver if the multipacket message has been solicited by a Destination Specific Request
-  Variable Message Length, maximum value used for dbc generation";
CM_ SG_ 2566835102 ProtLamp_18FECB9E "- Always 00b";
CM_ BO_ 2566835485 "- Freeze Parameters taken at last fault occurrence
-  Multipacket message handled by SAE Transport Protocol (J1939/21, par 5.10, Multipacket Broadcast with TP.CM/BAM, TP.DT)
-  Variable Message Length, maximum value used for dbc generation";
CM_ SG_ 2566835485 FfLen1 "- 24 bytes";
CM_ BO_ 2566835614 "- Freeze Parameters taken at last fault occurrence
-  Multipacket message handled by SAE Transport Protocol (J1939/21, par 5.10, Multipacket Broadcast with TP.CM/BAM, TP.DT)
-  Variable Message Length, maximum value used for dbc generation";
CM_ BO_ 2633943642 "- Multipacket message handled by SAE Transport Protocol (J1939/21, par 5.10, Multipacket Broadcast with TP.CM/BAM, TP.DT)
-  Variable Message Length, maximum value used for dbc generation.
- CUC.C.PCM..3..TELEM: Used in according with VCU file (DICO).";
CM_ SG_ 2633943642 ProtLamp_1CFECA5A "- Always 00b";
CM_ BO_ 2633943680 "- Multipacket message handled by SAE Transport Protocol (J1939/21, par 5.10, Multipacket Broadcast with TP.CM/BAM, TP.DT)
-  Siemens Full Elec only.
-  Variable Message Length, maximum value used for dbc generation";
CM_ SG_ 2633943680 ProtLamp_1CFECA80 "- Always 00b";
CM_ BO_ 2566856773 "- DoorsInfo=DoorsStat
-  Predisposal";
CM_ BO_ 2566749184 "- Engine Diesel only.";
CM_ BO_ 2561126730 "- DSE Functionnality. Message sent for debugging on the CAN Telem";
CM_ BO_ 2561126986 "- DSE Functionnality. Message sent for debugging on the CAN Telem";
CM_ BO_ 2561127242 "- DSE Functionnality. Message sent for debugging on the CAN Telem";
CM_ BO_ 2561127498 "- DSE Functionnality. Message sent for debugging on the CAN Telem";
CM_ BO_ 2561127754 "- DSE Functionnality. Message sent for debugging on the CAN Telem";
CM_ BO_ 2561128010 "- DSE Functionnality. Message sent for debugging on the CAN Telem";
CM_ BO_ 2561128266 "- DSE Functionnality. Message sent for debugging on the CAN Telem";
CM_ BO_ 2561128522 "- DSE Functionnality. Message sent for debugging on the CAN Telem";
CM_ BO_ 2561144138 "- DSE Functionnality. Message sent for debugging on the CAN Telem";
CM_ BO_ 2561128778 "- DSE Functionnality. Message sent for debugging on the CAN Telem";
CM_ BO_ 2561129034 "- DSE Functionnality. Message sent for debugging on the CAN Telem";
CM_ BO_ 2561145930 "- DSE Functionnality. Message sent for debugging on the CAN Telem";
CM_ BO_ 2561129290 "- DSE Functionnality. Message sent for debugging on the CAN Telem";
CM_ BO_ 2561129546 "- DSE Functionnality. Message sent for debugging on the CAN Telem";
CM_ BO_ 2561130058 "- DSE Functionnality. Message sent for debugging on the CAN Telem";
CM_ BO_ 2561129802 "- DSE Functionnality. Message sent for debugging on the CAN Telem";
CM_ BO_ 2561130314 "- DSE Functionnality. Message sent for debugging on the CAN Telem";
CM_ BO_ 2561140554 "- DSE Functionnality. Message sent for debugging on the CAN Telem";
CM_ BO_ 2561130570 "- DSE Functionnality. Message sent for debugging on the CAN Telem";
CM_ BO_ 2561143882 "- DSE Functionnality. Message sent for debugging on the CAN Telem";
CM_ BO_ 2561130826 "- DSE Functionnality. Message sent for debugging on the CAN Telem";
CM_ BO_ 2561131082 "- DSE Functionnality. Message sent for debugging on the CAN Telem";
CM_ BO_ 2561131338 "- DSE Functionnality. Message sent for debugging on the CAN Telem";
CM_ BO_ 2561140810 "- DSE Functionnality. Message sent for debugging on the CAN Telem";
CM_ BO_ 2561131594 "- Fuel score is the value interpreated by the cluster's econometer.";
CM_ SG_ 2561131594 ScoreFuel "- Predisposal. Used for Econometer value provided by PCM on IC.
-  Values outside the slot are considered out of range.";
BA_DEF_ BO_  "CI_MsgDefinition" STRING ;
BA_DEF_ BO_  "CI_MsgId" INT 0 2147483647;
BA_DEF_ BO_  "CI_MsgName" STRING ;
BA_DEF_ BO_  "GenMsgCycleTime" INT 0 3600000;
BA_DEF_ BO_  "GenMsgCycleTimeFast" INT 0 3600000;
BA_DEF_ BO_  "GenMsgDelayTime" INT 0 3600000;
BA_DEF_ BO_  "GenMsgILSupport" ENUM  "No","Yes";
BA_DEF_ BO_  "GenMsgNrOfRepetition" INT 0 1000000;
BA_DEF_ BO_  "GenMsgRequestable" INT 0 1;
BA_DEF_ BO_  "GenMsgSendType" ENUM  "cyclic","NotUsed","NotUsed","NotUsed","NotUsed","NotUsed","NotUsed","IfActive","noMsgSendType";
BA_DEF_ BO_  "GenMsgStartDelayTime" INT 0 100000;
BA_DEF_ BO_  "J1939PgAppearanceOnBus" ENUM  "Default","CAN_Extended","CANFD_Extended";
BA_DEF_ BO_  "TpJ1939VarDlc" ENUM  "No","Yes";
BA_DEF_ BO_  "VFrameFormat" ENUM  "StandardCAN","ExtendedCAN","reserved","J1939PG";
BA_DEF_ SG_  "CI_ParId" STRING ;
BA_DEF_ SG_  "CI_SigId" INT 0 2147483647;
BA_DEF_ SG_  "CI_SigName" STRING ;
BA_DEF_ SG_  "GenSigEVName" STRING ;
BA_DEF_ SG_  "GenSigILSupport" ENUM  "No","Yes";
BA_DEF_ SG_  "GenSigInactiveValue" INT 0 2147483647;
BA_DEF_ SG_  "GenSigSendType" ENUM  "Cyclic","OnWrite","OnWriteWithRepetition","OnChange","OnChangeWithRepetition","IfActive","IfActiveWithRepetition","NoSigSendType";
BA_DEF_ SG_  "GenSigStartValue" INT 0 2147483647;
BA_DEF_ SG_  "GenSigTimeoutTime_ACU" INT 0 3600000;
BA_DEF_ SG_  "GenSigTimeoutTime_ADCU" INT 0 3600000;
BA_DEF_ SG_  "GenSigTimeoutTime_CAID" INT 0 3600000;
BA_DEF_ SG_  "GenSigTimeoutTime_CANAIR" INT 0 3600000;
BA_DEF_ SG_  "GenSigTimeoutTime_DICO" INT 0 3600000;
BA_DEF_ SG_  "GenSigTimeoutTime_DTCO" INT 0 3600000;
BA_DEF_ SG_  "GenSigTimeoutTime_DiwaNXT" INT 0 3600000;
BA_DEF_ SG_  "GenSigTimeoutTime_DiwaNXT_MH" INT 0 3600000;
BA_DEF_ SG_  "GenSigTimeoutTime_EBS" INT 0 3600000;
BA_DEF_ SG_  "GenSigTimeoutTime_EBS_" INT 0 3600000;
BA_DEF_ SG_  "GenSigTimeoutTime_EBS__" INT 0 3600000;
BA_DEF_ SG_  "GenSigTimeoutTime_EBS___" INT 0 3600000;
BA_DEF_ SG_  "GenSigTimeoutTime_ELC5_Fr" INT 0 3600000;
BA_DEF_ SG_  "GenSigTimeoutTime_ELFA3" INT 0 3600000;
BA_DEF_ SG_  "GenSigTimeoutTime_ETS" INT 0 3600000;
BA_DEF_ SG_  "GenSigTimeoutTime_Ecolife2" INT 0 3600000;
BA_DEF_ SG_  "GenSigTimeoutTime_FCCU_" INT 0 3600000;
BA_DEF_ SG_  "GenSigTimeoutTime_FMS4" INT 0 3600000;
BA_DEF_ SG_  "GenSigTimeoutTime_HV_BOX" INT 0 3600000;
BA_DEF_ SG_  "GenSigTimeoutTime_INTD" INT 0 3600000;
BA_DEF_ SG_  "GenSigTimeoutTime_IRCS" INT 0 3600000;
BA_DEF_ SG_  "GenSigTimeoutTime_MD1_D" INT 0 3600000;
BA_DEF_ SG_  "GenSigTimeoutTime_MD1_G" INT 0 3600000;
BA_DEF_ SG_  "GenSigTimeoutTime_MTCO" INT 0 3600000;
BA_DEF_ SG_  "GenSigTimeoutTime_MulticII" INT 0 3600000;
BA_DEF_ SG_  "GenSigTimeoutTime_MulticS" INT 0 3600000;
BA_DEF_ SG_  "GenSigTimeoutTime_MulticS_" INT 0 3600000;
BA_DEF_ SG_  "GenSigTimeoutTime_MulticS__" INT 0 3600000;
BA_DEF_ SG_  "GenSigTimeoutTime_NBM" INT 0 3600000;
BA_DEF_ SG_  "GenSigTimeoutTime_NBM_" INT 0 3600000;
BA_DEF_ SG_  "GenSigTimeoutTime_NBM__" INT 0 3600000;
BA_DEF_ SG_  "GenSigTimeoutTime_NBM___" INT 0 3600000;
BA_DEF_ SG_  "GenSigTimeoutTime_PCM" INT 0 3600000;
BA_DEF_ SG_  "GenSigTimeoutTime_SGW" INT 0 3600000;
BA_DEF_ SG_  "GenSigTimeoutTime_SGW2" INT 0 3600000;
BA_DEF_ SG_  "GenSigTimeoutTime_SGW_" INT 0 3600000;
BA_DEF_ SG_  "GenSigTimeoutTime_SGW__" INT 0 3600000;
BA_DEF_ SG_  "GenSigTimeoutTime_SIU" INT 0 3600000;
BA_DEF_ SG_  "GenSigTimeoutTime_SmartRadio" INT 0 3600000;
BA_DEF_ SG_  "GenSigTimeoutTime_TPMS" INT 0 3600000;
BA_DEF_ SG_  "GenSigTimeoutTime_TSU" INT 0 3600000;
BA_DEF_ SG_  "GenSigTimeoutTime_VCM" INT 0 3600000;
BA_DEF_ SG_  "GenSigTimeoutTime_VCM_" INT 0 3600000;
BA_DEF_ SG_  "GenSigTimeoutTime_VCM__" INT 0 3600000;
BA_DEF_ SG_  "GenSigTimeoutTime_VCU" INT 0 3600000;
BA_DEF_ SG_  "GenSigTimeoutTime_VCU_" INT 0 3600000;
BA_DEF_ SG_  "GenSigTimeoutTime_VMU" INT 0 3600000;
BA_DEF_ SG_  "SPN" INT 0 524287;
BA_DEF_ SG_  "SigType" ENUM  "Default","Range","RangeSigned","ASCII","Discrete","Control","ReferencePGN","DTC","StringDelimiter","StringLength","StringLengthControl";
BA_DEF_DEF_  "CI_MsgDefinition" "";
BA_DEF_DEF_  "CI_MsgId" 0;
BA_DEF_DEF_  "CI_MsgName" "";
BA_DEF_DEF_  "GenMsgCycleTime" 0;
BA_DEF_DEF_  "GenMsgCycleTimeFast" 0;
BA_DEF_DEF_  "GenMsgDelayTime" 1;
BA_DEF_DEF_  "GenMsgILSupport" "Yes";
BA_DEF_DEF_  "GenMsgNrOfRepetition" 0;
BA_DEF_DEF_  "GenMsgRequestable" 0;
BA_DEF_DEF_  "GenMsgSendType" "noMsgSendType";
BA_DEF_DEF_  "GenMsgStartDelayTime" 0;
BA_DEF_DEF_  "J1939PgAppearanceOnBus" "Default";
BA_DEF_DEF_  "TpJ1939VarDlc" "No";
BA_DEF_DEF_  "VFrameFormat" "J1939PG";
BA_DEF_DEF_  "CI_ParId" "";
BA_DEF_DEF_  "CI_SigId" 0;
BA_DEF_DEF_  "CI_SigName" "";
BA_DEF_DEF_  "GenSigEVName" "Env@Nodename_@Signame";
BA_DEF_DEF_  "GenSigILSupport" "Yes";
BA_DEF_DEF_  "GenSigInactiveValue" 0;
BA_DEF_DEF_  "GenSigSendType" "NoSigSendType";
BA_DEF_DEF_  "GenSigStartValue" 0;
BA_DEF_DEF_  "GenSigTimeoutTime_ACU" 0;
BA_DEF_DEF_  "GenSigTimeoutTime_ADCU" 0;
BA_DEF_DEF_  "GenSigTimeoutTime_CAID" 0;
BA_DEF_DEF_  "GenSigTimeoutTime_CANAIR" 0;
BA_DEF_DEF_  "GenSigTimeoutTime_DICO" 0;
BA_DEF_DEF_  "GenSigTimeoutTime_DTCO" 0;
BA_DEF_DEF_  "GenSigTimeoutTime_DiwaNXT" 0;
BA_DEF_DEF_  "GenSigTimeoutTime_DiwaNXT_MH" 0;
BA_DEF_DEF_  "GenSigTimeoutTime_EBS" 0;
BA_DEF_DEF_  "GenSigTimeoutTime_EBS_" 0;
BA_DEF_DEF_  "GenSigTimeoutTime_EBS__" 0;
BA_DEF_DEF_  "GenSigTimeoutTime_EBS___" 0;
BA_DEF_DEF_  "GenSigTimeoutTime_ELC5_Fr" 0;
BA_DEF_DEF_  "GenSigTimeoutTime_ELFA3" 0;
BA_DEF_DEF_  "GenSigTimeoutTime_ETS" 0;
BA_DEF_DEF_  "GenSigTimeoutTime_Ecolife2" 0;
BA_DEF_DEF_  "GenSigTimeoutTime_FCCU_" 0;
BA_DEF_DEF_  "GenSigTimeoutTime_FMS4" 0;
BA_DEF_DEF_  "GenSigTimeoutTime_HV_BOX" 0;
BA_DEF_DEF_  "GenSigTimeoutTime_INTD" 0;
BA_DEF_DEF_  "GenSigTimeoutTime_IRCS" 0;
BA_DEF_DEF_  "GenSigTimeoutTime_MD1_D" 0;
BA_DEF_DEF_  "GenSigTimeoutTime_MD1_G" 0;
BA_DEF_DEF_  "GenSigTimeoutTime_MTCO" 0;
BA_DEF_DEF_  "GenSigTimeoutTime_MulticII" 0;
BA_DEF_DEF_  "GenSigTimeoutTime_MulticS" 0;
BA_DEF_DEF_  "GenSigTimeoutTime_MulticS_" 0;
BA_DEF_DEF_  "GenSigTimeoutTime_MulticS__" 0;
BA_DEF_DEF_  "GenSigTimeoutTime_NBM" 0;
BA_DEF_DEF_  "GenSigTimeoutTime_NBM_" 0;
BA_DEF_DEF_  "GenSigTimeoutTime_NBM__" 0;
BA_DEF_DEF_  "GenSigTimeoutTime_NBM___" 0;
BA_DEF_DEF_  "GenSigTimeoutTime_PCM" 0;
BA_DEF_DEF_  "GenSigTimeoutTime_SGW" 0;
BA_DEF_DEF_  "GenSigTimeoutTime_SGW2" 0;
BA_DEF_DEF_  "GenSigTimeoutTime_SGW_" 0;
BA_DEF_DEF_  "GenSigTimeoutTime_SGW__" 0;
BA_DEF_DEF_  "GenSigTimeoutTime_SIU" 0;
BA_DEF_DEF_  "GenSigTimeoutTime_SmartRadio" 0;
BA_DEF_DEF_  "GenSigTimeoutTime_TPMS" 0;
BA_DEF_DEF_  "GenSigTimeoutTime_TSU" 0;
BA_DEF_DEF_  "GenSigTimeoutTime_VCM" 0;
BA_DEF_DEF_  "GenSigTimeoutTime_VCM_" 0;
BA_DEF_DEF_  "GenSigTimeoutTime_VCM__" 0;
BA_DEF_DEF_  "GenSigTimeoutTime_VCU" 0;
BA_DEF_DEF_  "GenSigTimeoutTime_VCU_" 0;
BA_DEF_DEF_  "GenSigTimeoutTime_VMU" 0;
BA_DEF_DEF_  "SPN" 0;
BA_DEF_DEF_  "SigType" "Default";
BA_ "CI_MsgDefinition" BO_ 2566908915 "Iveco Proprietary";
BA_ "CI_MsgId" BO_ 2566908915 10858;
BA_ "CI_MsgName" BO_ 2566908915 "BMS_12 - Proprietary Iveco -  BMS0i Infos Frame";
BA_ "GenMsgCycleTime" BO_ 2566908915 5000;
BA_ "GenMsgCycleTimeFast" BO_ 2566908915 5000;
BA_ "GenMsgDelayTime" BO_ 2566908915 2500;
BA_ "GenMsgSendType" BO_ 2566908915 0;
BA_ "GenMsgStartDelayTime" BO_ 2566908915 76;
BA_ "CI_MsgDefinition" BO_ 2566883678 "Iveco Proprietary";
BA_ "CI_MsgId" BO_ 2566883678 2818;
BA_ "CI_MsgName" BO_ 2566883678 "CAID2_TO_V1 - CAID2_TO_V1";
BA_ "GenMsgCycleTime" BO_ 2566883678 500;
BA_ "GenMsgCycleTimeFast" BO_ 2566883678 500;
BA_ "GenMsgDelayTime" BO_ 2566883678 250;
BA_ "GenMsgSendType" BO_ 2566883678 0;
BA_ "GenMsgStartDelayTime" BO_ 2566883678 2;
BA_ "CI_MsgDefinition" BO_ 2566884190 "Iveco Proprietary";
BA_ "CI_MsgId" BO_ 2566884190 2833;
BA_ "CI_MsgName" BO_ 2566884190 "CAID2_TO_V3 - CAID2_TO_V3";
BA_ "GenMsgCycleTime" BO_ 2566884190 1000;
BA_ "GenMsgCycleTimeFast" BO_ 2566884190 1000;
BA_ "GenMsgDelayTime" BO_ 2566884190 500;
BA_ "GenMsgSendType" BO_ 2566884190 0;
BA_ "GenMsgStartDelayTime" BO_ 2566884190 8;
BA_ "CI_MsgDefinition" BO_ 2566843648 "J1939DA";
BA_ "CI_MsgId" BO_ 2566843648 2164;
BA_ "CI_MsgName" BO_ 2566843648 "CCSS_00 - Cruise Control/Vehicle Speed Setup";
BA_ "GenMsgCycleTime" BO_ 2566843648 250;
BA_ "GenMsgCycleTimeFast" BO_ 2566843648 250;
BA_ "GenMsgDelayTime" BO_ 2566843648 125;
BA_ "GenMsgSendType" BO_ 2566843648 0;
BA_ "GenMsgStartDelayTime" BO_ 2566843648 24;
BA_ "CI_MsgDefinition" BO_ 2566843676 "J1939DA";
BA_ "CI_MsgId" BO_ 2566843676 2170;
BA_ "CI_MsgName" BO_ 2566843676 "CCSS_1C - Cruise Control/Vehicle Speed Setup";
BA_ "GenMsgCycleTime" BO_ 2566843676 1000;
BA_ "GenMsgCycleTimeFast" BO_ 2566843676 1000;
BA_ "GenMsgDelayTime" BO_ 2566843676 100;
BA_ "GenMsgSendType" BO_ 2566843676 0;
BA_ "GenMsgStartDelayTime" BO_ 2566843676 156;
BA_ "CI_MsgDefinition" BO_ 2566844672 "J1939DA";
BA_ "CI_MsgId" BO_ 2566844672 2080;
BA_ "CI_MsgName" BO_ 2566844672 "CCVS1 - Cruise Control/Vehicle Speed 1";
BA_ "GenMsgCycleTime" BO_ 2566844672 100;
BA_ "GenMsgCycleTimeFast" BO_ 2566844672 100;
BA_ "GenMsgDelayTime" BO_ 2566844672 50;
BA_ "GenMsgSendType" BO_ 2566844672 0;
BA_ "GenMsgStartDelayTime" BO_ 2566844672 21;
BA_ "CI_MsgDefinition" BO_ 2566890313 "Iveco Proprietary";
BA_ "CI_MsgId" BO_ 2566890313 1397;
BA_ "CI_MsgName" BO_ 2566890313 "ChargerFaults - Proprietary B - ECCU Faults";
BA_ "GenMsgCycleTime" BO_ 2566890313 5000;
BA_ "GenMsgCycleTimeFast" BO_ 2566890313 5000;
BA_ "GenMsgDelayTime" BO_ 2566890313 2500;
BA_ "GenMsgSendType" BO_ 2566890313 0;
BA_ "GenMsgStartDelayTime" BO_ 2566890313 63;
BA_ "CI_MsgDefinition" BO_ 2566843164 "J1939DA";
BA_ "CI_MsgId" BO_ 2566843164 10377;
BA_ "CI_MsgName" BO_ 2566843164 "CI_1C - Component Identification";
BA_ "TpJ1939VarDlc" BO_ 2566843164 1;
BA_ "CI_MsgDefinition" BO_ 2566843165 "J1939DA";
BA_ "CI_MsgId" BO_ 2566843165 10382;
BA_ "CI_MsgName" BO_ 2566843165 "CI_1D - Component Identification";
BA_ "TpJ1939VarDlc" BO_ 2566843165 1;
BA_ "CI_MsgDefinition" BO_ 2566843230 "J1939DA";
BA_ "CI_MsgId" BO_ 2566843230 10397;
BA_ "CI_MsgName" BO_ 2566843230 "CI_5E - Component Identification";
BA_ "TpJ1939VarDlc" BO_ 2566843230 1;
BA_ "CI_MsgDefinition" BO_ 2566865139 "Iveco SPR2 Proprietary";
BA_ "CI_MsgId" BO_ 2566865139 3881;
BA_ "CI_MsgName" BO_ 2566865139 "Clim_LTO_Sts - Status of the Clim System of the LTO Batteries";
BA_ "GenMsgCycleTime" BO_ 2566865139 5000;
BA_ "GenMsgCycleTimeFast" BO_ 2566865139 5000;
BA_ "GenMsgDelayTime" BO_ 2566865139 2500;
BA_ "GenMsgSendType" BO_ 2566865139 0;
BA_ "GenMsgStartDelayTime" BO_ 2566865139 20;
BA_ "CI_MsgDefinition" BO_ 2566811659 "J1939DA";
BA_ "CI_MsgId" BO_ 2566811659 389;
BA_ "CI_MsgName" BO_ 2566811659 "CVW_0B - Combination Vehicle Weight";
BA_ "GenMsgCycleTime" BO_ 2566811659 1000;
BA_ "GenMsgCycleTimeFast" BO_ 2566811659 1000;
BA_ "GenMsgDelayTime" BO_ 2566811659 500;
BA_ "GenMsgSendType" BO_ 2566811659 0;
BA_ "GenMsgStartDelayTime" BO_ 2566811659 35;
BA_ "CI_MsgDefinition" BO_ 2566811695 "J1939DA";
BA_ "CI_MsgId" BO_ 2566811695 17494;
BA_ "CI_MsgName" BO_ 2566811695 "CVW_2F - Combination Vehicle Weight";
BA_ "GenMsgCycleTime" BO_ 2566811695 1000;
BA_ "GenMsgCycleTimeFast" BO_ 2566811695 1000;
BA_ "GenMsgDelayTime" BO_ 2566811695 500;
BA_ "GenMsgSendType" BO_ 2566811695 0;
BA_ "GenMsgStartDelayTime" BO_ 2566811695 6;
BA_ "CI_MsgDefinition" BO_ 2566802967 "J1939DA";
BA_ "CI_MsgId" BO_ 2566802967 3267;
BA_ "CI_MsgName" BO_ 2566802967 "DC1_17 - Door Control 1";
BA_ "GenMsgCycleTime" BO_ 2566802967 100;
BA_ "GenMsgCycleTimeFast" BO_ 2566802967 100;
BA_ "GenMsgDelayTime" BO_ 2566802967 50;
BA_ "GenMsgSendType" BO_ 2566802967 0;
BA_ "GenMsgStartDelayTime" BO_ 2566802967 36;
BA_ "CI_MsgDefinition" BO_ 2566759703 "J1939DA";
BA_ "CI_MsgId" BO_ 2566759703 3271;
BA_ "CI_MsgName" BO_ 2566759703 "DC2_17 - Door Control 2";
BA_ "GenMsgCycleTime" BO_ 2566759703 100;
BA_ "GenMsgCycleTimeFast" BO_ 2566759703 100;
BA_ "GenMsgDelayTime" BO_ 2566759703 50;
BA_ "GenMsgSendType" BO_ 2566759703 0;
BA_ "GenMsgStartDelayTime" BO_ 2566759703 28;
BA_ "CI_MsgDefinition" BO_ 2566849774 "Continental Proprietary";
BA_ "CI_MsgId" BO_ 2566849774 2581;
BA_ "CI_MsgName" BO_ 2566849774 "DCPD - DriversConsentOnPersonalData (Continental Proprietary)";
BA_ "CI_MsgDefinition" BO_ 2566847521 "J1939DA";
BA_ "CI_MsgId" BO_ 2566847521 2997;
BA_ "CI_MsgName" BO_ 2566847521 "DD1_21 - Dash Display 1";
BA_ "GenMsgCycleTime" BO_ 2566847521 1000;
BA_ "GenMsgCycleTimeFast" BO_ 2566847521 1000;
BA_ "GenMsgDelayTime" BO_ 2566847521 100;
BA_ "GenMsgSendType" BO_ 2566847521 0;
BA_ "GenMsgStartDelayTime" BO_ 2566847521 68;
BA_ "CI_MsgDefinition" BO_ 2566810606 "J1939DA";
BA_ "CI_MsgId" BO_ 2566810606 729;
BA_ "CI_MsgName" BO_ 2566810606 "DI_EE - Driver's Identification";
BA_ "TpJ1939VarDlc" BO_ 2566810606 1;
BA_ "CI_MsgDefinition" BO_ 2566834688 "J1939-73";
BA_ "CI_MsgId" BO_ 2566834688 4456;
BA_ "CI_MsgName" BO_ 2566834688 "DM01_00 - Active Diagnostic Trouble Codes";
BA_ "GenMsgCycleTime" BO_ 2566834688 1000;
BA_ "GenMsgCycleTimeFast" BO_ 2566834688 1000;
BA_ "GenMsgDelayTime" BO_ 2566834688 100;
BA_ "GenMsgSendType" BO_ 2566834688 0;
BA_ "GenMsgStartDelayTime" BO_ 2566834688 39;
BA_ "TpJ1939VarDlc" BO_ 2566834688 1;
BA_ "CI_MsgDefinition" BO_ 2566834691 "J1939-73";
BA_ "CI_MsgId" BO_ 2566834691 4565;
BA_ "CI_MsgName" BO_ 2566834691 "DM01_03 - Active Diagnostic Trouble Codes";
BA_ "GenMsgCycleTime" BO_ 2566834691 1000;
BA_ "GenMsgCycleTimeFast" BO_ 2566834691 1000;
BA_ "GenMsgDelayTime" BO_ 2566834691 100;
BA_ "GenMsgSendType" BO_ 2566834691 0;
BA_ "GenMsgStartDelayTime" BO_ 2566834691 28;
BA_ "TpJ1939VarDlc" BO_ 2566834691 1;
BA_ "CI_MsgDefinition" BO_ 2566834699 "J1939-73";
BA_ "CI_MsgId" BO_ 2566834699 4624;
BA_ "CI_MsgName" BO_ 2566834699 "DM01_0B - Active Diagnostic Trouble Codes";
BA_ "GenMsgCycleTime" BO_ 2566834699 1000;
BA_ "GenMsgCycleTimeFast" BO_ 2566834699 1000;
BA_ "GenMsgDelayTime" BO_ 2566834699 100;
BA_ "GenMsgSendType" BO_ 2566834699 0;
BA_ "GenMsgStartDelayTime" BO_ 2566834699 39;
BA_ "TpJ1939VarDlc" BO_ 2566834699 1;
BA_ "CI_MsgDefinition" BO_ 2566834704 "J1939-73";
BA_ "CI_MsgId" BO_ 2566834704 4679;
BA_ "CI_MsgName" BO_ 2566834704 "DM01_10 - Active Diagnostic Trouble Codes";
BA_ "GenMsgCycleTime" BO_ 2566834704 1000;
BA_ "GenMsgCycleTimeFast" BO_ 2566834704 1000;
BA_ "GenMsgDelayTime" BO_ 2566834704 100;
BA_ "GenMsgSendType" BO_ 2566834704 0;
BA_ "GenMsgStartDelayTime" BO_ 2566834704 6;
BA_ "TpJ1939VarDlc" BO_ 2566834704 1;
BA_ "CI_MsgDefinition" BO_ 2566834711 "J1939-73";
BA_ "CI_MsgId" BO_ 2566834711 4738;
BA_ "CI_MsgName" BO_ 2566834711 "DM01_17 - Active Diagnostic Trouble Codes";
BA_ "GenMsgCycleTime" BO_ 2566834711 1000;
BA_ "GenMsgCycleTimeFast" BO_ 2566834711 1000;
BA_ "GenMsgDelayTime" BO_ 2566834711 100;
BA_ "GenMsgSendType" BO_ 2566834711 0;
BA_ "GenMsgStartDelayTime" BO_ 2566834711 65;
BA_ "TpJ1939VarDlc" BO_ 2566834711 1;
BA_ "CI_MsgDefinition" BO_ 2566834716 "J1939-73";
BA_ "CI_MsgId" BO_ 2566834716 5008;
BA_ "CI_MsgName" BO_ 2566834716 "DM01_1C - Active Diagnostic Trouble Codes";
BA_ "GenMsgCycleTime" BO_ 2566834716 1000;
BA_ "GenMsgCycleTimeFast" BO_ 2566834716 1000;
BA_ "GenMsgDelayTime" BO_ 2566834716 100;
BA_ "GenMsgSendType" BO_ 2566834716 0;
BA_ "GenMsgStartDelayTime" BO_ 2566834716 152;
BA_ "TpJ1939VarDlc" BO_ 2566834716 1;
BA_ "CI_MsgDefinition" BO_ 2566834717 "J1939-73";
BA_ "CI_MsgId" BO_ 2566834717 5063;
BA_ "CI_MsgName" BO_ 2566834717 "DM01_1D - Active Diagnostic Trouble Codes";
BA_ "GenMsgCycleTime" BO_ 2566834717 1000;
BA_ "GenMsgCycleTimeFast" BO_ 2566834717 1000;
BA_ "GenMsgDelayTime" BO_ 2566834717 100;
BA_ "GenMsgSendType" BO_ 2566834717 0;
BA_ "GenMsgStartDelayTime" BO_ 2566834717 2;
BA_ "TpJ1939VarDlc" BO_ 2566834717 1;
BA_ "CI_MsgDefinition" BO_ 2566834721 "J1939-73";
BA_ "CI_MsgId" BO_ 2566834721 5118;
BA_ "CI_MsgName" BO_ 2566834721 "DM01_21 - Active Diagnostic Trouble Codes";
BA_ "GenMsgCycleTime" BO_ 2566834721 1000;
BA_ "GenMsgCycleTimeFast" BO_ 2566834721 1000;
BA_ "GenMsgDelayTime" BO_ 2566834721 100;
BA_ "GenMsgSendType" BO_ 2566834721 0;
BA_ "GenMsgStartDelayTime" BO_ 2566834721 65;
BA_ "TpJ1939VarDlc" BO_ 2566834721 1;
BA_ "CI_MsgDefinition" BO_ 2566834727 "J1939-73";
BA_ "CI_MsgId" BO_ 2566834727 5173;
BA_ "CI_MsgName" BO_ 2566834727 "DM01_27 - Active Diagnostic Trouble Codes";
BA_ "GenMsgCycleTime" BO_ 2566834727 1000;
BA_ "GenMsgCycleTimeFast" BO_ 2566834727 1000;
BA_ "GenMsgDelayTime" BO_ 2566834727 100;
BA_ "GenMsgSendType" BO_ 2566834727 0;
BA_ "GenMsgStartDelayTime" BO_ 2566834727 4;
BA_ "TpJ1939VarDlc" BO_ 2566834727 1;
BA_ "CI_MsgDefinition" BO_ 2566834734 "J1939-73";
BA_ "CI_MsgId" BO_ 2566834734 5283;
BA_ "CI_MsgName" BO_ 2566834734 "DM01_2E - Active Diagnostic Trouble Codes";
BA_ "GenMsgCycleTime" BO_ 2566834734 1000;
BA_ "GenMsgCycleTimeFast" BO_ 2566834734 1000;
BA_ "GenMsgDelayTime" BO_ 2566834734 100;
BA_ "GenMsgSendType" BO_ 2566834734 0;
BA_ "TpJ1939VarDlc" BO_ 2566834734 1;
BA_ "CI_MsgDefinition" BO_ 2566834735 "J1939-73";
BA_ "CI_MsgId" BO_ 2566834735 5338;
BA_ "CI_MsgName" BO_ 2566834735 "DM01_2F - Active Diagnostic Trouble Codes";
BA_ "GenMsgCycleTime" BO_ 2566834735 1000;
BA_ "GenMsgCycleTimeFast" BO_ 2566834735 1000;
BA_ "GenMsgDelayTime" BO_ 2566834735 100;
BA_ "GenMsgSendType" BO_ 2566834735 0;
BA_ "GenMsgStartDelayTime" BO_ 2566834735 8;
BA_ "TpJ1939VarDlc" BO_ 2566834735 1;
BA_ "CI_MsgDefinition" BO_ 2566834739 "J1939-73";
BA_ "CI_MsgId" BO_ 2566834739 5448;
BA_ "CI_MsgName" BO_ 2566834739 "DM01_33 - Active Diagnostic Trouble Codes";
BA_ "GenMsgCycleTime" BO_ 2566834739 1000;
BA_ "GenMsgCycleTimeFast" BO_ 2566834739 1000;
BA_ "GenMsgDelayTime" BO_ 2566834739 100;
BA_ "GenMsgSendType" BO_ 2566834739 0;
BA_ "GenMsgStartDelayTime" BO_ 2566834739 2;
BA_ "TpJ1939VarDlc" BO_ 2566834739 1;
BA_ "CI_MsgDefinition" BO_ 2566834744 "J1939-73";
BA_ "CI_MsgId" BO_ 2566834744 5503;
BA_ "CI_MsgName" BO_ 2566834744 "DM01_38 - Active Diagnostic Trouble Codes";
BA_ "GenMsgCycleTime" BO_ 2566834744 1000;
BA_ "GenMsgCycleTimeFast" BO_ 2566834744 1000;
BA_ "GenMsgDelayTime" BO_ 2566834744 100;
BA_ "GenMsgSendType" BO_ 2566834744 0;
BA_ "TpJ1939VarDlc" BO_ 2566834744 1;
BA_ "CI_MsgDefinition" BO_ 2566834752 "J1939-73";
BA_ "CI_MsgId" BO_ 2566834752 5793;
BA_ "CI_MsgName" BO_ 2566834752 "DM01_40 - Active Diagnostic Trouble Codes";
BA_ "GenMsgCycleTime" BO_ 2566834752 1000;
BA_ "GenMsgCycleTimeFast" BO_ 2566834752 1000;
BA_ "GenMsgDelayTime" BO_ 2566834752 100;
BA_ "GenMsgSendType" BO_ 2566834752 0;
BA_ "GenMsgStartDelayTime" BO_ 2566834752 6;
BA_ "TpJ1939VarDlc" BO_ 2566834752 1;
BA_ "CI_MsgDefinition" BO_ 2566834761 "J1939-73";
BA_ "CI_MsgId" BO_ 2566834761 4953;
BA_ "CI_MsgName" BO_ 2566834761 "DM01_49 - Active Diagnostic Trouble Codes";
BA_ "GenMsgCycleTime" BO_ 2566834761 1000;
BA_ "GenMsgCycleTimeFast" BO_ 2566834761 1000;
BA_ "GenMsgDelayTime" BO_ 2566834761 100;
BA_ "GenMsgSendType" BO_ 2566834761 0;
BA_ "TpJ1939VarDlc" BO_ 2566834761 1;
BA_ "CI_MsgDefinition" BO_ 2566834762 "J1939-73";
BA_ "CI_MsgId" BO_ 2566834762 5558;
BA_ "CI_MsgName" BO_ 2566834762 "DM01_4A - Active Diagnostic Trouble Codes";
BA_ "GenMsgCycleTime" BO_ 2566834762 1000;
BA_ "GenMsgCycleTimeFast" BO_ 2566834762 1000;
BA_ "GenMsgDelayTime" BO_ 2566834762 100;
BA_ "GenMsgSendType" BO_ 2566834762 0;
BA_ "GenMsgStartDelayTime" BO_ 2566834762 154;
BA_ "TpJ1939VarDlc" BO_ 2566834762 1;
BA_ "CI_MsgDefinition" BO_ 2566834778 "J1939-73";
BA_ "CI_MsgId" BO_ 2566834778 5738;
BA_ "CI_MsgName" BO_ 2566834778 "DM01_5A - Active Diagnostic Trouble Codes";
BA_ "GenMsgCycleTime" BO_ 2566834778 1000;
BA_ "GenMsgCycleTimeFast" BO_ 2566834778 1000;
BA_ "GenMsgDelayTime" BO_ 2566834778 100;
BA_ "GenMsgSendType" BO_ 2566834778 0;
BA_ "GenMsgStartDelayTime" BO_ 2566834778 13;
BA_ "TpJ1939VarDlc" BO_ 2566834778 1;
BA_ "CI_MsgDefinition" BO_ 2566834782 "J1939-73";
BA_ "CI_MsgId" BO_ 2566834782 14754;
BA_ "CI_MsgName" BO_ 2566834782 "DM01_5E - Active Diagnostic Trouble Codes";
BA_ "GenMsgCycleTime" BO_ 2566834782 1000;
BA_ "GenMsgCycleTimeFast" BO_ 2566834782 1000;
BA_ "GenMsgDelayTime" BO_ 2566834782 100;
BA_ "GenMsgSendType" BO_ 2566834782 0;
BA_ "GenMsgStartDelayTime" BO_ 2566834782 6;
BA_ "TpJ1939VarDlc" BO_ 2566834782 1;
BA_ "CI_MsgDefinition" BO_ 2566834814 "J1939-73";
BA_ "CI_MsgId" BO_ 2566834814 5903;
BA_ "CI_MsgName" BO_ 2566834814 "DM01_7E - Active Diagnostic Trouble Codes";
BA_ "GenMsgCycleTime" BO_ 2566834814 1000;
BA_ "GenMsgCycleTimeFast" BO_ 2566834814 1000;
BA_ "GenMsgDelayTime" BO_ 2566834814 100;
BA_ "GenMsgSendType" BO_ 2566834814 0;
BA_ "TpJ1939VarDlc" BO_ 2566834814 1;
BA_ "CI_MsgDefinition" BO_ 2566834832 "J1939-73";
BA_ "CI_MsgId" BO_ 2566834832 6068;
BA_ "CI_MsgName" BO_ 2566834832 "DM01_90 - Active Diagnostic Trouble Codes";
BA_ "GenMsgCycleTime" BO_ 2566834832 1000;
BA_ "GenMsgCycleTimeFast" BO_ 2566834832 1000;
BA_ "GenMsgDelayTime" BO_ 2566834832 100;
BA_ "GenMsgSendType" BO_ 2566834832 0;
BA_ "TpJ1939VarDlc" BO_ 2566834832 1;
BA_ "CI_MsgDefinition" BO_ 2566834833 "J1939-73";
BA_ "CI_MsgId" BO_ 2566834833 6123;
BA_ "CI_MsgName" BO_ 2566834833 "DM01_91 - Active Diagnostic Trouble Codes";
BA_ "GenMsgCycleTime" BO_ 2566834833 1000;
BA_ "GenMsgCycleTimeFast" BO_ 2566834833 1000;
BA_ "GenMsgDelayTime" BO_ 2566834833 100;
BA_ "GenMsgSendType" BO_ 2566834833 0;
BA_ "TpJ1939VarDlc" BO_ 2566834833 1;
BA_ "CI_MsgDefinition" BO_ 2566834834 "J1939-73";
BA_ "CI_MsgId" BO_ 2566834834 6178;
BA_ "CI_MsgName" BO_ 2566834834 "DM01_92 - Active Diagnostic Trouble Codes";
BA_ "GenMsgCycleTime" BO_ 2566834834 1000;
BA_ "GenMsgCycleTimeFast" BO_ 2566834834 1000;
BA_ "GenMsgDelayTime" BO_ 2566834834 100;
BA_ "GenMsgSendType" BO_ 2566834834 0;
BA_ "TpJ1939VarDlc" BO_ 2566834834 1;
BA_ "CI_MsgDefinition" BO_ 2566834844 "J1939-73";
BA_ "CI_MsgId" BO_ 2566834844 6233;
BA_ "CI_MsgName" BO_ 2566834844 "DM01_9C - Active Diagnostic Trouble Codes";
BA_ "GenMsgCycleTime" BO_ 2566834844 1000;
BA_ "GenMsgCycleTimeFast" BO_ 2566834844 1000;
BA_ "GenMsgDelayTime" BO_ 2566834844 100;
BA_ "GenMsgSendType" BO_ 2566834844 0;
BA_ "TpJ1939VarDlc" BO_ 2566834844 1;
BA_ "CI_MsgDefinition" BO_ 2566834846 "J1939-73";
BA_ "CI_MsgId" BO_ 2566834846 5958;
BA_ "CI_MsgName" BO_ 2566834846 "DM01_9E - Active Diagnostic Trouble Codes";
BA_ "GenMsgCycleTime" BO_ 2566834846 1000;
BA_ "GenMsgCycleTimeFast" BO_ 2566834846 1000;
BA_ "GenMsgDelayTime" BO_ 2566834846 100;
BA_ "GenMsgSendType" BO_ 2566834846 0;
BA_ "GenMsgStartDelayTime" BO_ 2566834846 10;
BA_ "TpJ1939VarDlc" BO_ 2566834846 1;
BA_ "CI_MsgDefinition" BO_ 2566834848 "J1939-73";
BA_ "CI_MsgId" BO_ 2566834848 6288;
BA_ "CI_MsgName" BO_ 2566834848 "DM01_A0 - Active Diagnostic Trouble Codes";
BA_ "GenMsgCycleTime" BO_ 2566834848 1000;
BA_ "GenMsgCycleTimeFast" BO_ 2566834848 1000;
BA_ "GenMsgDelayTime" BO_ 2566834848 100;
BA_ "GenMsgSendType" BO_ 2566834848 0;
BA_ "TpJ1939VarDlc" BO_ 2566834848 1;
BA_ "CI_MsgDefinition" BO_ 2566834882 "J1939-73";
BA_ "CI_MsgId" BO_ 2566834882 17880;
BA_ "CI_MsgName" BO_ 2566834882 "DM01_C2 - Active Diagnostic Trouble Codes";
BA_ "TpJ1939VarDlc" BO_ 2566834882 1;
BA_ "CI_MsgDefinition" BO_ 2566834920 "J1939-73";
BA_ "CI_MsgId" BO_ 2566834920 6013;
BA_ "CI_MsgName" BO_ 2566834920 "DM01_E8 - Active Diagnostic Trouble Codes";
BA_ "GenMsgCycleTime" BO_ 2566834920 1000;
BA_ "GenMsgCycleTimeFast" BO_ 2566834920 1000;
BA_ "GenMsgDelayTime" BO_ 2566834920 100;
BA_ "GenMsgSendType" BO_ 2566834920 0;
BA_ "TpJ1939VarDlc" BO_ 2566834920 1;
BA_ "CI_MsgDefinition" BO_ 2566834926 "J1939-73";
BA_ "CI_MsgId" BO_ 2566834926 6353;
BA_ "CI_MsgName" BO_ 2566834926 "DM01_EE - Active Diagnostic Trouble Codes";
BA_ "GenMsgCycleTime" BO_ 2566834926 1000;
BA_ "GenMsgCycleTimeFast" BO_ 2566834926 1000;
BA_ "GenMsgDelayTime" BO_ 2566834926 100;
BA_ "GenMsgSendType" BO_ 2566834926 0;
BA_ "GenMsgStartDelayTime" BO_ 2566834926 16;
BA_ "TpJ1939VarDlc" BO_ 2566834926 1;
BA_ "CI_MsgDefinition" BO_ 2566834931 "J1939-73";
BA_ "CI_MsgId" BO_ 2566834931 6408;
BA_ "CI_MsgName" BO_ 2566834931 "DM01_F3 - Active Diagnostic Trouble Codes";
BA_ "GenMsgCycleTime" BO_ 2566834931 1000;
BA_ "GenMsgCycleTimeFast" BO_ 2566834931 1000;
BA_ "GenMsgDelayTime" BO_ 2566834931 100;
BA_ "GenMsgSendType" BO_ 2566834931 0;
BA_ "GenMsgStartDelayTime" BO_ 2566834931 8;
BA_ "TpJ1939VarDlc" BO_ 2566834931 1;
BA_ "CI_MsgDefinition" BO_ 2566834972 "J1939-73";
BA_ "CI_MsgId" BO_ 2566834972 6797;
BA_ "CI_MsgName" BO_ 2566834972 "DM02_1C - Previously Active Diagnostic Trouble Codes";
BA_ "TpJ1939VarDlc" BO_ 2566834972 1;
BA_ "CI_MsgDefinition" BO_ 2566834973 "J1939-73";
BA_ "CI_MsgId" BO_ 2566834973 6966;
BA_ "CI_MsgName" BO_ 2566834973 "DM02_1D - Previously Active Diagnostic Trouble Codes";
BA_ "TpJ1939VarDlc" BO_ 2566834973 1;
BA_ "CI_MsgDefinition" BO_ 2566835102 "J1939-73";
BA_ "CI_MsgId" BO_ 2566835102 7241;
BA_ "CI_MsgName" BO_ 2566835102 "DM02_9E - Previously Active Diagnostic Trouble Codes";
BA_ "TpJ1939VarDlc" BO_ 2566835102 1;
BA_ "CI_MsgDefinition" BO_ 2566835485 "Iveco Proprietary";
BA_ "CI_MsgId" BO_ 2566835485 8594;
BA_ "CI_MsgName" BO_ 2566835485 "DM04_1D - Freeze Frame Parameters";
BA_ "TpJ1939VarDlc" BO_ 2566835485 1;
BA_ "CI_MsgDefinition" BO_ 2566835614 "Iveco Proprietary";
BA_ "CI_MsgId" BO_ 2566835614 9197;
BA_ "CI_MsgName" BO_ 2566835614 "DM04_9E - Freeze Frame Parameters";
BA_ "TpJ1939VarDlc" BO_ 2566835614 1;
BA_ "CI_MsgDefinition" BO_ 2633943642 "J1939-73";
BA_ "CI_MsgId" BO_ 2633943642 5613;
BA_ "CI_MsgName" BO_ 2633943642 "DM1_5A_P7 - Active Diagnostic Trouble Codes";
BA_ "GenMsgCycleTime" BO_ 2633943642 1000;
BA_ "GenMsgCycleTimeFast" BO_ 2633943642 1000;
BA_ "GenMsgDelayTime" BO_ 2633943642 100;
BA_ "GenMsgSendType" BO_ 2633943642 0;
BA_ "GenMsgStartDelayTime" BO_ 2633943642 52;
BA_ "TpJ1939VarDlc" BO_ 2633943642 1;
BA_ "CI_MsgDefinition" BO_ 2633943680 "J1939-73";
BA_ "CI_MsgId" BO_ 2633943680 5668;
BA_ "CI_MsgName" BO_ 2633943680 "DM1_80_P7 - Active Diagnostic Trouble Codes";
BA_ "GenMsgCycleTime" BO_ 2633943680 1000;
BA_ "GenMsgCycleTimeFast" BO_ 2633943680 1000;
BA_ "GenMsgDelayTime" BO_ 2633943680 100;
BA_ "GenMsgSendType" BO_ 2633943680 0;
BA_ "GenMsgStartDelayTime" BO_ 2633943680 54;
BA_ "TpJ1939VarDlc" BO_ 2633943680 1;
BA_ "CI_MsgDefinition" BO_ 2566856773 "Iveco Proprietary";
BA_ "CI_MsgId" BO_ 2566856773 3364;
BA_ "CI_MsgName" BO_ 2566856773 "DoorStat - Doors status for PCM";
BA_ "GenMsgCycleTime" BO_ 2566856773 1000;
BA_ "GenMsgCycleTimeFast" BO_ 2566856773 1000;
BA_ "GenMsgDelayTime" BO_ 2566856773 500;
BA_ "GenMsgSendType" BO_ 2566856773 0;
BA_ "GenMsgStartDelayTime" BO_ 2566856773 77;
BA_ "CI_MsgDefinition" BO_ 2566749184 "J1939DA";
BA_ "CI_MsgId" BO_ 2566749184 1215;
BA_ "CI_MsgName" BO_ 2566749184 "DPFC1 - Diesel Particulate Filter Control 1";
BA_ "GenMsgCycleTime" BO_ 2566749184 1000;
BA_ "GenMsgCycleTimeFast" BO_ 2566749184 1000;
BA_ "GenMsgDelayTime" BO_ 2566749184 100;
BA_ "GenMsgSendType" BO_ 2566749184 0;
BA_ "GenMsgStartDelayTime" BO_ 2566749184 37;
BA_ "CI_MsgDefinition" BO_ 2561126730 "Iveco Bus Proprietary";
BA_ "CI_MsgId" BO_ 2561126730 14224;
BA_ "CI_MsgName" BO_ 2561126730 "DSE_ACC - DSE Acc";
BA_ "GenMsgCycleTime" BO_ 2561126730 1000;
BA_ "GenMsgCycleTimeFast" BO_ 2561126730 1000;
BA_ "GenMsgDelayTime" BO_ 2561126730 500;
BA_ "GenMsgSendType" BO_ 2561126730 0;
BA_ "GenMsgStartDelayTime" BO_ 2561126730 4;
BA_ "CI_MsgDefinition" BO_ 2561126986 "Iveco Bus Proprietary";
BA_ "CI_MsgId" BO_ 2561126986 14230;
BA_ "CI_MsgName" BO_ 2561126986 "DSE_ACC_DBG - DSE Acc DBG";
BA_ "GenMsgCycleTime" BO_ 2561126986 1000;
BA_ "GenMsgCycleTimeFast" BO_ 2561126986 1000;
BA_ "GenMsgDelayTime" BO_ 2561126986 500;
BA_ "GenMsgSendType" BO_ 2561126986 0;
BA_ "GenMsgStartDelayTime" BO_ 2561126986 6;
BA_ "CI_MsgDefinition" BO_ 2561127242 "Iveco Bus Proprietary";
BA_ "CI_MsgId" BO_ 2561127242 14233;
BA_ "CI_MsgName" BO_ 2561127242 "DSE_ACCE - DSE Acceleration";
BA_ "GenMsgCycleTime" BO_ 2561127242 1000;
BA_ "GenMsgCycleTimeFast" BO_ 2561127242 1000;
BA_ "GenMsgDelayTime" BO_ 2561127242 500;
BA_ "GenMsgSendType" BO_ 2561127242 0;
BA_ "GenMsgStartDelayTime" BO_ 2561127242 8;
BA_ "CI_MsgDefinition" BO_ 2561127498 "Iveco Bus Proprietary";
BA_ "CI_MsgId" BO_ 2561127498 14239;
BA_ "CI_MsgName" BO_ 2561127498 "DSE_ACCE_DBG - DSE Acceleration DBG";
BA_ "GenMsgCycleTime" BO_ 2561127498 1000;
BA_ "GenMsgCycleTimeFast" BO_ 2561127498 1000;
BA_ "GenMsgDelayTime" BO_ 2561127498 500;
BA_ "GenMsgSendType" BO_ 2561127498 0;
BA_ "GenMsgStartDelayTime" BO_ 2561127498 10;
BA_ "CI_MsgDefinition" BO_ 2561127754 "Iveco Bus Proprietary";
BA_ "CI_MsgId" BO_ 2561127754 14245;
BA_ "CI_MsgName" BO_ 2561127754 "DSE_AEBS - DSE Aebs";
BA_ "GenMsgCycleTime" BO_ 2561127754 1000;
BA_ "GenMsgCycleTimeFast" BO_ 2561127754 1000;
BA_ "GenMsgDelayTime" BO_ 2561127754 500;
BA_ "GenMsgSendType" BO_ 2561127754 0;
BA_ "GenMsgStartDelayTime" BO_ 2561127754 12;
BA_ "CI_MsgDefinition" BO_ 2561128010 "Iveco Bus Proprietary";
BA_ "CI_MsgId" BO_ 2561128010 14251;
BA_ "CI_MsgName" BO_ 2561128010 "DSE_AEBS_DBG - DSE Aebs DBG";
BA_ "GenMsgCycleTime" BO_ 2561128010 1000;
BA_ "GenMsgCycleTimeFast" BO_ 2561128010 1000;
BA_ "GenMsgDelayTime" BO_ 2561128010 500;
BA_ "GenMsgSendType" BO_ 2561128010 0;
BA_ "GenMsgStartDelayTime" BO_ 2561128010 14;
BA_ "CI_MsgDefinition" BO_ 2561128266 "Iveco Bus Proprietary";
BA_ "CI_MsgId" BO_ 2561128266 14254;
BA_ "CI_MsgName" BO_ 2561128266 "DSE_AirC - DSE AirC";
BA_ "GenMsgCycleTime" BO_ 2561128266 1000;
BA_ "GenMsgCycleTimeFast" BO_ 2561128266 1000;
BA_ "GenMsgDelayTime" BO_ 2561128266 500;
BA_ "GenMsgSendType" BO_ 2561128266 0;
BA_ "GenMsgStartDelayTime" BO_ 2561128266 16;
BA_ "CI_MsgDefinition" BO_ 2561128522 "Iveco Bus Proprietary";
BA_ "CI_MsgId" BO_ 2561128522 14260;
BA_ "CI_MsgName" BO_ 2561128522 "DSE_AirC_DBG - DSE AirC DBG";
BA_ "GenMsgCycleTime" BO_ 2561128522 1000;
BA_ "GenMsgCycleTimeFast" BO_ 2561128522 1000;
BA_ "GenMsgDelayTime" BO_ 2561128522 500;
BA_ "GenMsgSendType" BO_ 2561128522 0;
BA_ "GenMsgStartDelayTime" BO_ 2561128522 18;
BA_ "CI_MsgDefinition" BO_ 2561144138 "Iveco Bus Proprietary";
BA_ "CI_MsgId" BO_ 2561144138 14262;
BA_ "CI_MsgName" BO_ 2561144138 "DSE_ATTENTION - DSE Attention";
BA_ "GenMsgCycleTime" BO_ 2561144138 1000;
BA_ "GenMsgCycleTimeFast" BO_ 2561144138 1000;
BA_ "GenMsgDelayTime" BO_ 2561144138 500;
BA_ "GenMsgSendType" BO_ 2561144138 0;
BA_ "GenMsgStartDelayTime" BO_ 2561144138 134;
BA_ "CI_MsgDefinition" BO_ 2561128778 "Iveco Bus Proprietary";
BA_ "CI_MsgId" BO_ 2561128778 14268;
BA_ "CI_MsgName" BO_ 2561128778 "DSE_AUXBK - DSE AuxBrake";
BA_ "GenMsgCycleTime" BO_ 2561128778 1000;
BA_ "GenMsgCycleTimeFast" BO_ 2561128778 1000;
BA_ "GenMsgDelayTime" BO_ 2561128778 500;
BA_ "GenMsgSendType" BO_ 2561128778 0;
BA_ "GenMsgStartDelayTime" BO_ 2561128778 20;
BA_ "CI_MsgDefinition" BO_ 2561129034 "Iveco Bus Proprietary";
BA_ "CI_MsgId" BO_ 2561129034 14274;
BA_ "CI_MsgName" BO_ 2561129034 "DSE_AUXBK_DBG - DSE AuxBrake DBG";
BA_ "GenMsgCycleTime" BO_ 2561129034 1000;
BA_ "GenMsgCycleTimeFast" BO_ 2561129034 1000;
BA_ "GenMsgDelayTime" BO_ 2561129034 500;
BA_ "GenMsgSendType" BO_ 2561129034 0;
BA_ "GenMsgStartDelayTime" BO_ 2561129034 22;
BA_ "CI_MsgDefinition" BO_ 2561145930 "Iveco Bus Proprietary";
BA_ "CI_MsgId" BO_ 2561145930 14282;
BA_ "CI_MsgName" BO_ 2561145930 "DSE_BSIS - DSE Bsis";
BA_ "GenMsgCycleTime" BO_ 2561145930 1000;
BA_ "GenMsgCycleTimeFast" BO_ 2561145930 1000;
BA_ "GenMsgDelayTime" BO_ 2561145930 500;
BA_ "GenMsgSendType" BO_ 2561145930 0;
BA_ "GenMsgStartDelayTime" BO_ 2561145930 148;
BA_ "CI_MsgDefinition" BO_ 2561129290 "Iveco Bus Proprietary";
BA_ "CI_MsgId" BO_ 2561129290 14288;
BA_ "CI_MsgName" BO_ 2561129290 "DSE_CARE - DSE Care";
BA_ "GenMsgCycleTime" BO_ 2561129290 1000;
BA_ "GenMsgCycleTimeFast" BO_ 2561129290 1000;
BA_ "GenMsgDelayTime" BO_ 2561129290 500;
BA_ "GenMsgSendType" BO_ 2561129290 0;
BA_ "GenMsgStartDelayTime" BO_ 2561129290 24;
BA_ "CI_MsgDefinition" BO_ 2561129546 "Iveco Bus Proprietary";
BA_ "CI_MsgId" BO_ 2561129546 14294;
BA_ "CI_MsgName" BO_ 2561129546 "DSE_CMD - DSE CMD";
BA_ "GenMsgCycleTime" BO_ 2561129546 1000;
BA_ "GenMsgCycleTimeFast" BO_ 2561129546 1000;
BA_ "GenMsgDelayTime" BO_ 2561129546 500;
BA_ "GenMsgSendType" BO_ 2561129546 0;
BA_ "GenMsgStartDelayTime" BO_ 2561129546 26;
BA_ "CI_MsgDefinition" BO_ 2561130058 "Iveco Bus Proprietary";
BA_ "CI_MsgId" BO_ 2561130058 14297;
BA_ "CI_MsgName" BO_ 2561130058 "DSE_COMFORT - DSE Comfort";
BA_ "GenMsgCycleTime" BO_ 2561130058 1000;
BA_ "GenMsgCycleTimeFast" BO_ 2561130058 1000;
BA_ "GenMsgDelayTime" BO_ 2561130058 500;
BA_ "GenMsgSendType" BO_ 2561130058 0;
BA_ "GenMsgStartDelayTime" BO_ 2561130058 30;
BA_ "CI_MsgDefinition" BO_ 2561129802 "Iveco Bus Proprietary";
BA_ "CI_MsgId" BO_ 2561129802 14303;
BA_ "CI_MsgName" BO_ 2561129802 "DSE_CURNT - DSE Curent";
BA_ "GenMsgCycleTime" BO_ 2561129802 1000;
BA_ "GenMsgCycleTimeFast" BO_ 2561129802 1000;
BA_ "GenMsgDelayTime" BO_ 2561129802 500;
BA_ "GenMsgSendType" BO_ 2561129802 0;
BA_ "GenMsgStartDelayTime" BO_ 2561129802 28;
BA_ "CI_MsgDefinition" BO_ 2561130314 "Iveco Bus Proprietary";
BA_ "CI_MsgId" BO_ 2561130314 14306;
BA_ "CI_MsgName" BO_ 2561130314 "DSE_DAS - DSE Das";
BA_ "GenMsgCycleTime" BO_ 2561130314 1000;
BA_ "GenMsgCycleTimeFast" BO_ 2561130314 1000;
BA_ "GenMsgDelayTime" BO_ 2561130314 500;
BA_ "GenMsgSendType" BO_ 2561130314 0;
BA_ "GenMsgStartDelayTime" BO_ 2561130314 32;
BA_ "CI_MsgDefinition" BO_ 2561140554 "Iveco Bus Proprietary";
BA_ "CI_MsgId" BO_ 2561140554 14312;
BA_ "CI_MsgName" BO_ 2561140554 "DSE_DAS_DBG - DSE DAS DBG";
BA_ "GenMsgCycleTime" BO_ 2561140554 1000;
BA_ "GenMsgCycleTimeFast" BO_ 2561140554 1000;
BA_ "GenMsgDelayTime" BO_ 2561140554 500;
BA_ "GenMsgSendType" BO_ 2561140554 0;
BA_ "GenMsgStartDelayTime" BO_ 2561140554 106;
BA_ "CI_MsgDefinition" BO_ 2561130570 "Iveco Bus Proprietary";
BA_ "CI_MsgId" BO_ 2561130570 14315;
BA_ "CI_MsgName" BO_ 2561130570 "DSE_DEC - DSE Deceleration";
BA_ "GenMsgCycleTime" BO_ 2561130570 1000;
BA_ "GenMsgCycleTimeFast" BO_ 2561130570 1000;
BA_ "GenMsgDelayTime" BO_ 2561130570 500;
BA_ "GenMsgSendType" BO_ 2561130570 0;
BA_ "GenMsgStartDelayTime" BO_ 2561130570 34;
BA_ "CI_MsgDefinition" BO_ 2561143882 "Iveco Bus Proprietary";
BA_ "CI_MsgId" BO_ 2561143882 14321;
BA_ "CI_MsgName" BO_ 2561143882 "DSE_DRIVERAWARE - DSE Driver Awareness";
BA_ "GenMsgCycleTime" BO_ 2561143882 1000;
BA_ "GenMsgCycleTimeFast" BO_ 2561143882 1000;
BA_ "GenMsgDelayTime" BO_ 2561143882 500;
BA_ "GenMsgSendType" BO_ 2561143882 0;
BA_ "GenMsgStartDelayTime" BO_ 2561143882 132;
BA_ "CI_MsgDefinition" BO_ 2561130826 "Iveco Bus Proprietary";
BA_ "CI_MsgId" BO_ 2561130826 14327;
BA_ "CI_MsgName" BO_ 2561130826 "DSE_ECO - DSE EcoMode";
BA_ "GenMsgCycleTime" BO_ 2561130826 1000;
BA_ "GenMsgCycleTimeFast" BO_ 2561130826 1000;
BA_ "GenMsgDelayTime" BO_ 2561130826 500;
BA_ "GenMsgSendType" BO_ 2561130826 0;
BA_ "GenMsgStartDelayTime" BO_ 2561130826 36;
BA_ "CI_MsgDefinition" BO_ 2561131082 "Iveco Bus Proprietary";
BA_ "CI_MsgId" BO_ 2561131082 14333;
BA_ "CI_MsgName" BO_ 2561131082 "DSE_ECO_DBG - DSE EcoMode DBG";
BA_ "GenMsgCycleTime" BO_ 2561131082 1000;
BA_ "GenMsgCycleTimeFast" BO_ 2561131082 1000;
BA_ "GenMsgDelayTime" BO_ 2561131082 500;
BA_ "GenMsgSendType" BO_ 2561131082 0;
BA_ "GenMsgStartDelayTime" BO_ 2561131082 38;
BA_ "CI_MsgDefinition" BO_ 2561131338 "Iveco Bus Proprietary";
BA_ "CI_MsgId" BO_ 2561131338 14335;
BA_ "CI_MsgName" BO_ 2561131338 "DSE_ENG - DSE Engine Use";
BA_ "GenMsgCycleTime" BO_ 2561131338 1000;
BA_ "GenMsgCycleTimeFast" BO_ 2561131338 1000;
BA_ "GenMsgDelayTime" BO_ 2561131338 500;
BA_ "GenMsgSendType" BO_ 2561131338 0;
BA_ "GenMsgStartDelayTime" BO_ 2561131338 40;
BA_ "CI_MsgDefinition" BO_ 2561140810 "Iveco Bus Proprietary";
BA_ "CI_MsgId" BO_ 2561140810 14341;
BA_ "CI_MsgName" BO_ 2561140810 "DSE_EVAL - DSE Evaluated Trip";
BA_ "GenMsgCycleTime" BO_ 2561140810 1000;
BA_ "GenMsgCycleTimeFast" BO_ 2561140810 1000;
BA_ "GenMsgDelayTime" BO_ 2561140810 500;
BA_ "GenMsgSendType" BO_ 2561140810 0;
BA_ "GenMsgStartDelayTime" BO_ 2561140810 108;
BA_ "CI_MsgDefinition" BO_ 2561131594 "Iveco Bus Proprietary";
BA_ "CI_MsgId" BO_ 2561131594 1906;
BA_ "CI_MsgName" BO_ 2561131594 "DSE_FUEL - DSE Fuel";
BA_ "GenMsgCycleTime" BO_ 2561131594 500;
BA_ "GenMsgCycleTimeFast" BO_ 2561131594 500;
BA_ "GenMsgDelayTime" BO_ 2561131594 250;
BA_ "GenMsgSendType" BO_ 2561131594 0;
BA_ "CI_ParId" SG_ 2566908915 Bms0IBatV_18FFEBF3 "IB572";
BA_ "CI_SigId" SG_ 2566908915 Bms0IBatV_18FFEBF3 10859;
BA_ "CI_SigName" SG_ 2566908915 Bms0IBatV_18FFEBF3 "BMS0i Battery Voltage";
BA_ "GenSigTimeoutTime_FMS4" SG_ 2566908915 Bms0IBatV_18FFEBF3 25000;
BA_ "GenSigTimeoutTime_MulticII" SG_ 2566908915 Bms0IBatV_18FFEBF3 25000;
BA_ "GenSigTimeoutTime_PCM" SG_ 2566908915 Bms0IBatV_18FFEBF3 25000;
BA_ "GenSigTimeoutTime_SGW__" SG_ 2566908915 Bms0IBatV_18FFEBF3 25000;
BA_ "SigType" SG_ 2566908915 Bms0IBatV_18FFEBF3 1;
BA_ "CI_ParId" SG_ 2566908915 Bms0IBatCur_18FFEBF3 "IB573";
BA_ "CI_SigId" SG_ 2566908915 Bms0IBatCur_18FFEBF3 10860;
BA_ "CI_SigName" SG_ 2566908915 Bms0IBatCur_18FFEBF3 "BMS0i Battery Current";
BA_ "GenSigTimeoutTime_FMS4" SG_ 2566908915 Bms0IBatCur_18FFEBF3 25000;
BA_ "GenSigTimeoutTime_MulticII" SG_ 2566908915 Bms0IBatCur_18FFEBF3 25000;
BA_ "GenSigTimeoutTime_PCM" SG_ 2566908915 Bms0IBatCur_18FFEBF3 25000;
BA_ "GenSigTimeoutTime_SGW__" SG_ 2566908915 Bms0IBatCur_18FFEBF3 25000;
BA_ "SigType" SG_ 2566908915 Bms0IBatCur_18FFEBF3 1;
BA_ "CI_ParId" SG_ 2566908915 Bms0IBatSoc_18FFEBF3 "IB574";
BA_ "CI_SigId" SG_ 2566908915 Bms0IBatSoc_18FFEBF3 10861;
BA_ "CI_SigName" SG_ 2566908915 Bms0IBatSoc_18FFEBF3 "BMS0i Battery SOC";
BA_ "GenSigTimeoutTime_FMS4" SG_ 2566908915 Bms0IBatSoc_18FFEBF3 25000;
BA_ "GenSigTimeoutTime_MulticII" SG_ 2566908915 Bms0IBatSoc_18FFEBF3 25000;
BA_ "GenSigTimeoutTime_PCM" SG_ 2566908915 Bms0IBatSoc_18FFEBF3 25000;
BA_ "GenSigTimeoutTime_SGW__" SG_ 2566908915 Bms0IBatSoc_18FFEBF3 25000;
BA_ "SigType" SG_ 2566908915 Bms0IBatSoc_18FFEBF3 1;
BA_ "CI_ParId" SG_ 2566908915 Bms0IMaxCellV_18FFEBF3 "IB575";
BA_ "CI_SigId" SG_ 2566908915 Bms0IMaxCellV_18FFEBF3 10862;
BA_ "CI_SigName" SG_ 2566908915 Bms0IMaxCellV_18FFEBF3 "BMS0i Max Cell Voltage";
BA_ "GenSigTimeoutTime_FMS4" SG_ 2566908915 Bms0IMaxCellV_18FFEBF3 25000;
BA_ "GenSigTimeoutTime_MulticII" SG_ 2566908915 Bms0IMaxCellV_18FFEBF3 25000;
BA_ "GenSigTimeoutTime_PCM" SG_ 2566908915 Bms0IMaxCellV_18FFEBF3 25000;
BA_ "GenSigTimeoutTime_SGW__" SG_ 2566908915 Bms0IMaxCellV_18FFEBF3 25000;
BA_ "SigType" SG_ 2566908915 Bms0IMaxCellV_18FFEBF3 1;
BA_ "CI_ParId" SG_ 2566908915 Bms0IMinCellV_18FFEBF3 "IB576";
BA_ "CI_SigId" SG_ 2566908915 Bms0IMinCellV_18FFEBF3 10863;
BA_ "CI_SigName" SG_ 2566908915 Bms0IMinCellV_18FFEBF3 "BMS0i Min Cell Voltage";
BA_ "GenSigTimeoutTime_FMS4" SG_ 2566908915 Bms0IMinCellV_18FFEBF3 25000;
BA_ "GenSigTimeoutTime_MulticII" SG_ 2566908915 Bms0IMinCellV_18FFEBF3 25000;
BA_ "GenSigTimeoutTime_PCM" SG_ 2566908915 Bms0IMinCellV_18FFEBF3 25000;
BA_ "GenSigTimeoutTime_SGW__" SG_ 2566908915 Bms0IMinCellV_18FFEBF3 25000;
BA_ "SigType" SG_ 2566908915 Bms0IMinCellV_18FFEBF3 1;
BA_ "CI_ParId" SG_ 2566908915 Bms0IEqualizationSts_18FFEBF3 "IB577";
BA_ "CI_SigId" SG_ 2566908915 Bms0IEqualizationSts_18FFEBF3 10864;
BA_ "CI_SigName" SG_ 2566908915 Bms0IEqualizationSts_18FFEBF3 "BMS0i Equalization Status";
BA_ "GenSigTimeoutTime_FMS4" SG_ 2566908915 Bms0IEqualizationSts_18FFEBF3 25000;
BA_ "GenSigTimeoutTime_MulticII" SG_ 2566908915 Bms0IEqualizationSts_18FFEBF3 25000;
BA_ "GenSigTimeoutTime_PCM" SG_ 2566908915 Bms0IEqualizationSts_18FFEBF3 25000;
BA_ "GenSigTimeoutTime_SGW__" SG_ 2566908915 Bms0IEqualizationSts_18FFEBF3 25000;
BA_ "CI_ParId" SG_ 2566908915 Bms0IActSts_18FFEBF3 "IB578";
BA_ "CI_SigId" SG_ 2566908915 Bms0IActSts_18FFEBF3 10865;
BA_ "CI_SigName" SG_ 2566908915 Bms0IActSts_18FFEBF3 "BMS0i Actual State";
BA_ "GenSigTimeoutTime_FMS4" SG_ 2566908915 Bms0IActSts_18FFEBF3 25000;
BA_ "GenSigTimeoutTime_MulticII" SG_ 2566908915 Bms0IActSts_18FFEBF3 25000;
BA_ "GenSigTimeoutTime_PCM" SG_ 2566908915 Bms0IActSts_18FFEBF3 25000;
BA_ "GenSigTimeoutTime_SGW__" SG_ 2566908915 Bms0IActSts_18FFEBF3 25000;
BA_ "CI_ParId" SG_ 2566908915 Bms0IOpSts_18FFEBF3 "IB579";
BA_ "CI_SigId" SG_ 2566908915 Bms0IOpSts_18FFEBF3 10866;
BA_ "CI_SigName" SG_ 2566908915 Bms0IOpSts_18FFEBF3 "BMS0i Operating Status";
BA_ "GenSigTimeoutTime_FMS4" SG_ 2566908915 Bms0IOpSts_18FFEBF3 25000;
BA_ "GenSigTimeoutTime_MulticII" SG_ 2566908915 Bms0IOpSts_18FFEBF3 25000;
BA_ "GenSigTimeoutTime_PCM" SG_ 2566908915 Bms0IOpSts_18FFEBF3 25000;
BA_ "GenSigTimeoutTime_SGW__" SG_ 2566908915 Bms0IOpSts_18FFEBF3 25000;
BA_ "SigType" SG_ 2566908915 Bms0IOpSts_18FFEBF3 4;
BA_ "CI_ParId" SG_ 2566908915 Bms0IChgCompl_18FFEBF3 "IB580";
BA_ "CI_SigId" SG_ 2566908915 Bms0IChgCompl_18FFEBF3 10867;
BA_ "CI_SigName" SG_ 2566908915 Bms0IChgCompl_18FFEBF3 "BMS0i Charge Completed";
BA_ "GenSigTimeoutTime_FMS4" SG_ 2566908915 Bms0IChgCompl_18FFEBF3 25000;
BA_ "GenSigTimeoutTime_MulticII" SG_ 2566908915 Bms0IChgCompl_18FFEBF3 25000;
BA_ "GenSigTimeoutTime_PCM" SG_ 2566908915 Bms0IChgCompl_18FFEBF3 25000;
BA_ "GenSigTimeoutTime_SGW__" SG_ 2566908915 Bms0IChgCompl_18FFEBF3 25000;
BA_ "CI_ParId" SG_ 2566908915 Bms0IPwrDistributed_18FFEBF3 "IB581";
BA_ "CI_SigId" SG_ 2566908915 Bms0IPwrDistributed_18FFEBF3 10868;
BA_ "CI_SigName" SG_ 2566908915 Bms0IPwrDistributed_18FFEBF3 "BMS0i Power Distributed";
BA_ "GenSigTimeoutTime_FMS4" SG_ 2566908915 Bms0IPwrDistributed_18FFEBF3 25000;
BA_ "GenSigTimeoutTime_MulticII" SG_ 2566908915 Bms0IPwrDistributed_18FFEBF3 25000;
BA_ "GenSigTimeoutTime_PCM" SG_ 2566908915 Bms0IPwrDistributed_18FFEBF3 25000;
BA_ "GenSigTimeoutTime_SGW__" SG_ 2566908915 Bms0IPwrDistributed_18FFEBF3 25000;
BA_ "CI_ParId" SG_ 2566908915 Bms0IMaxCellTemp_18FFEBF3 "IB582";
BA_ "CI_SigId" SG_ 2566908915 Bms0IMaxCellTemp_18FFEBF3 10869;
BA_ "CI_SigName" SG_ 2566908915 Bms0IMaxCellTemp_18FFEBF3 "BMS0i Max Cell Temperature";
BA_ "GenSigTimeoutTime_FMS4" SG_ 2566908915 Bms0IMaxCellTemp_18FFEBF3 25000;
BA_ "GenSigTimeoutTime_MulticII" SG_ 2566908915 Bms0IMaxCellTemp_18FFEBF3 25000;
BA_ "GenSigTimeoutTime_PCM" SG_ 2566908915 Bms0IMaxCellTemp_18FFEBF3 25000;
BA_ "GenSigTimeoutTime_SGW__" SG_ 2566908915 Bms0IMaxCellTemp_18FFEBF3 25000;
BA_ "SigType" SG_ 2566908915 Bms0IMaxCellTemp_18FFEBF3 1;
BA_ "CI_ParId" SG_ 2566908915 Bms0IMinCellTemp_18FFEBF3 "IB583";
BA_ "CI_SigId" SG_ 2566908915 Bms0IMinCellTemp_18FFEBF3 10870;
BA_ "CI_SigName" SG_ 2566908915 Bms0IMinCellTemp_18FFEBF3 "BMS0i Min Cell Temperature";
BA_ "GenSigTimeoutTime_FMS4" SG_ 2566908915 Bms0IMinCellTemp_18FFEBF3 25000;
BA_ "GenSigTimeoutTime_MulticII" SG_ 2566908915 Bms0IMinCellTemp_18FFEBF3 25000;
BA_ "GenSigTimeoutTime_PCM" SG_ 2566908915 Bms0IMinCellTemp_18FFEBF3 25000;
BA_ "GenSigTimeoutTime_SGW__" SG_ 2566908915 Bms0IMinCellTemp_18FFEBF3 25000;
BA_ "SigType" SG_ 2566908915 Bms0IMinCellTemp_18FFEBF3 1;
BA_ "CI_ParId" SG_ 2566883678 WarmUp "IB434";
BA_ "CI_SigId" SG_ 2566883678 WarmUp 2819;
BA_ "CI_SigName" SG_ 2566883678 WarmUp "Warm up";
BA_ "GenSigTimeoutTime_PCM" SG_ 2566883678 WarmUp 2500;
BA_ "GenSigTimeoutTime_SGW__" SG_ 2566883678 WarmUp 2500;
BA_ "CI_ParId" SG_ 2566883678 CaidPwrSts "IB435";
BA_ "CI_SigId" SG_ 2566883678 CaidPwrSts 2820;
BA_ "CI_SigName" SG_ 2566883678 CaidPwrSts "CAID power state";
BA_ "GenSigTimeoutTime_PCM" SG_ 2566883678 CaidPwrSts 2500;
BA_ "GenSigTimeoutTime_SGW__" SG_ 2566883678 CaidPwrSts 2500;
BA_ "CI_ParId" SG_ 2566883678 BreathAnalyze "IB436";
BA_ "CI_SigId" SG_ 2566883678 BreathAnalyze 2821;
BA_ "CI_SigName" SG_ 2566883678 BreathAnalyze "Breath Analyze";
BA_ "GenSigTimeoutTime_PCM" SG_ 2566883678 BreathAnalyze 2500;
BA_ "GenSigTimeoutTime_SGW__" SG_ 2566883678 BreathAnalyze 2500;
BA_ "CI_ParId" SG_ 2566883678 AcceptedBreathSample "IB437";
BA_ "CI_SigId" SG_ 2566883678 AcceptedBreathSample 2822;
BA_ "CI_SigName" SG_ 2566883678 AcceptedBreathSample "Accepted breath sample";
BA_ "GenSigTimeoutTime_PCM" SG_ 2566883678 AcceptedBreathSample 2500;
BA_ "GenSigTimeoutTime_SGW__" SG_ 2566883678 AcceptedBreathSample 2500;
BA_ "CI_ParId" SG_ 2566883678 StartViolation "IB438";
BA_ "CI_SigId" SG_ 2566883678 StartViolation 2823;
BA_ "CI_SigName" SG_ 2566883678 StartViolation "Start violation";
BA_ "GenSigTimeoutTime_PCM" SG_ 2566883678 StartViolation 2500;
BA_ "GenSigTimeoutTime_SGW__" SG_ 2566883678 StartViolation 2500;
BA_ "CI_ParId" SG_ 2566883678 CaidActv "IB439";
BA_ "CI_SigId" SG_ 2566883678 CaidActv 2824;
BA_ "CI_SigName" SG_ 2566883678 CaidActv "CAID Activation";
BA_ "GenSigTimeoutTime_PCM" SG_ 2566883678 CaidActv 2500;
BA_ "GenSigTimeoutTime_SGW__" SG_ 2566883678 CaidActv 2500;
BA_ "CI_ParId" SG_ 2566883678 HandsetConnSts "IB440";
BA_ "CI_SigId" SG_ 2566883678 HandsetConnSts 2825;
BA_ "CI_SigName" SG_ 2566883678 HandsetConnSts "Handset connection state";
BA_ "GenSigTimeoutTime_PCM" SG_ 2566883678 HandsetConnSts 2500;
BA_ "GenSigTimeoutTime_SGW__" SG_ 2566883678 HandsetConnSts 2500;
BA_ "CI_ParId" SG_ 2566883678 CalSucclyMade "IB441";
BA_ "CI_SigId" SG_ 2566883678 CalSucclyMade 2826;
BA_ "CI_SigName" SG_ 2566883678 CalSucclyMade "Calibration successfully made";
BA_ "GenSigTimeoutTime_PCM" SG_ 2566883678 CalSucclyMade 2500;
BA_ "GenSigTimeoutTime_SGW__" SG_ 2566883678 CalSucclyMade 2500;
BA_ "CI_ParId" SG_ 2566884190 DeferredData "IB442";
BA_ "CI_SigId" SG_ 2566884190 DeferredData 2834;
BA_ "CI_SigName" SG_ 2566884190 DeferredData "Deferred data";
BA_ "GenSigTimeoutTime_PCM" SG_ 2566884190 DeferredData 5000;
BA_ "GenSigTimeoutTime_SGW__" SG_ 2566884190 DeferredData 5000;
BA_ "CI_ParId" SG_ 2566843648 MaxVsl "74";
BA_ "CI_SigId" SG_ 2566843648 MaxVsl 2165;
BA_ "CI_SigName" SG_ 2566843648 MaxVsl "Maximum Vehicle Speed Limit";
BA_ "GenSigTimeoutTime_PCM" SG_ 2566843648 MaxVsl 1250;
BA_ "GenSigTimeoutTime_SGW__" SG_ 2566843648 MaxVsl 1250;
BA_ "GenSigTimeoutTime_VCM_" SG_ 2566843648 MaxVsl 1250;
BA_ "SPN" SG_ 2566843648 MaxVsl 74;
BA_ "SigType" SG_ 2566843648 MaxVsl 1;
BA_ "CI_ParId" SG_ 2566843648 DcdcCurSetPnt24VSide "IB271";
BA_ "CI_SigId" SG_ 2566843648 DcdcCurSetPnt24VSide 2169;
BA_ "CI_SigName" SG_ 2566843648 DcdcCurSetPnt24VSide "DCDC current set-point for the 24V side";
BA_ "GenSigTimeoutTime_DiwaNXT_MH" SG_ 2566843648 DcdcCurSetPnt24VSide 1250;
BA_ "GenSigTimeoutTime_PCM" SG_ 2566843648 DcdcCurSetPnt24VSide 1250;
BA_ "GenSigTimeoutTime_SGW__" SG_ 2566843648 DcdcCurSetPnt24VSide 1250;
BA_ "GenSigTimeoutTime_VCM_" SG_ 2566843648 DcdcCurSetPnt24VSide 1250;
BA_ "SigType" SG_ 2566843648 DcdcCurSetPnt24VSide 1;
BA_ "CI_ParId" SG_ 2566843676 MaxVsl_18FEED1C "74";
BA_ "CI_SigId" SG_ 2566843676 MaxVsl_18FEED1C 2171;
BA_ "CI_SigName" SG_ 2566843676 MaxVsl_18FEED1C "Maximum Vehicle Speed Limit";
BA_ "GenSigSendType" SG_ 2566843676 MaxVsl_18FEED1C 3;
BA_ "GenSigTimeoutTime_ADCU" SG_ 2566843676 MaxVsl_18FEED1C 5000;
BA_ "GenSigTimeoutTime_SGW_" SG_ 2566843676 MaxVsl_18FEED1C 5000;
BA_ "SPN" SG_ 2566843676 MaxVsl_18FEED1C 74;
BA_ "SigType" SG_ 2566843676 MaxVsl_18FEED1C 1;
BA_ "CI_ParId" SG_ 2566844672 ParkBrkSw "70";
BA_ "CI_SigId" SG_ 2566844672 ParkBrkSw 2082;
BA_ "CI_SigName" SG_ 2566844672 ParkBrkSw "Parking Brake Switch";
BA_ "GenSigTimeoutTime_ADCU" SG_ 2566844672 ParkBrkSw 500;
BA_ "GenSigTimeoutTime_CANAIR" SG_ 2566844672 ParkBrkSw 500;
BA_ "GenSigTimeoutTime_EBS" SG_ 2566844672 ParkBrkSw 500;
BA_ "GenSigTimeoutTime_EBS_" SG_ 2566844672 ParkBrkSw 500;
BA_ "GenSigTimeoutTime_EBS__" SG_ 2566844672 ParkBrkSw 500;
BA_ "GenSigTimeoutTime_EBS___" SG_ 2566844672 ParkBrkSw 500;
BA_ "GenSigTimeoutTime_Ecolife2" SG_ 2566844672 ParkBrkSw 500;
BA_ "GenSigTimeoutTime_FMS4" SG_ 2566844672 ParkBrkSw 500;
BA_ "GenSigTimeoutTime_MulticS" SG_ 2566844672 ParkBrkSw 500;
BA_ "GenSigTimeoutTime_NBM" SG_ 2566844672 ParkBrkSw 500;
BA_ "GenSigTimeoutTime_PCM" SG_ 2566844672 ParkBrkSw 500;
BA_ "GenSigTimeoutTime_SGW2" SG_ 2566844672 ParkBrkSw 500;
BA_ "GenSigTimeoutTime_SGW__" SG_ 2566844672 ParkBrkSw 500;
BA_ "GenSigTimeoutTime_SmartRadio" SG_ 2566844672 ParkBrkSw 500;
BA_ "SPN" SG_ 2566844672 ParkBrkSw 70;
BA_ "SigType" SG_ 2566844672 ParkBrkSw 4;
BA_ "CI_ParId" SG_ 2566844672 WhBasedVehSpeed "84";
BA_ "CI_SigId" SG_ 2566844672 WhBasedVehSpeed 2084;
BA_ "CI_SigName" SG_ 2566844672 WhBasedVehSpeed "Wheel-Based Vehicle Speed";
BA_ "GenSigTimeoutTime_ADCU" SG_ 2566844672 WhBasedVehSpeed 500;
BA_ "GenSigTimeoutTime_CANAIR" SG_ 2566844672 WhBasedVehSpeed 500;
BA_ "GenSigTimeoutTime_EBS" SG_ 2566844672 WhBasedVehSpeed 500;
BA_ "GenSigTimeoutTime_EBS_" SG_ 2566844672 WhBasedVehSpeed 500;
BA_ "GenSigTimeoutTime_EBS__" SG_ 2566844672 WhBasedVehSpeed 500;
BA_ "GenSigTimeoutTime_EBS___" SG_ 2566844672 WhBasedVehSpeed 500;
BA_ "GenSigTimeoutTime_ELC5_Fr" SG_ 2566844672 WhBasedVehSpeed 500;
BA_ "GenSigTimeoutTime_Ecolife2" SG_ 2566844672 WhBasedVehSpeed 500;
BA_ "GenSigTimeoutTime_FMS4" SG_ 2566844672 WhBasedVehSpeed 500;
BA_ "GenSigTimeoutTime_IRCS" SG_ 2566844672 WhBasedVehSpeed 500;
BA_ "GenSigTimeoutTime_PCM" SG_ 2566844672 WhBasedVehSpeed 500;
BA_ "GenSigTimeoutTime_SGW2" SG_ 2566844672 WhBasedVehSpeed 500;
BA_ "GenSigTimeoutTime_SGW__" SG_ 2566844672 WhBasedVehSpeed 500;
BA_ "GenSigTimeoutTime_SIU" SG_ 2566844672 WhBasedVehSpeed 500;
BA_ "GenSigTimeoutTime_SmartRadio" SG_ 2566844672 WhBasedVehSpeed 500;
BA_ "SPN" SG_ 2566844672 WhBasedVehSpeed 84;
BA_ "SigType" SG_ 2566844672 WhBasedVehSpeed 1;
BA_ "CI_ParId" SG_ 2566844672 CcActv "595";
BA_ "CI_SigId" SG_ 2566844672 CcActv 2085;
BA_ "CI_SigName" SG_ 2566844672 CcActv "Cruise Control Active";
BA_ "GenSigTimeoutTime_ADCU" SG_ 2566844672 CcActv 500;
BA_ "GenSigTimeoutTime_Ecolife2" SG_ 2566844672 CcActv 500;
BA_ "GenSigTimeoutTime_FMS4" SG_ 2566844672 CcActv 500;
BA_ "GenSigTimeoutTime_IRCS" SG_ 2566844672 CcActv 500;
BA_ "GenSigTimeoutTime_MulticS" SG_ 2566844672 CcActv 500;
BA_ "GenSigTimeoutTime_MulticS_" SG_ 2566844672 CcActv 500;
BA_ "GenSigTimeoutTime_NBM" SG_ 2566844672 CcActv 500;
BA_ "GenSigTimeoutTime_PCM" SG_ 2566844672 CcActv 500;
BA_ "GenSigTimeoutTime_SGW2" SG_ 2566844672 CcActv 500;
BA_ "GenSigTimeoutTime_SGW__" SG_ 2566844672 CcActv 500;
BA_ "SPN" SG_ 2566844672 CcActv 595;
BA_ "SigType" SG_ 2566844672 CcActv 4;
BA_ "CI_ParId" SG_ 2566844672 BrkSw "597";
BA_ "CI_SigId" SG_ 2566844672 BrkSw 2087;
BA_ "CI_SigName" SG_ 2566844672 BrkSw "Brake Switch";
BA_ "GenSigTimeoutTime_ADCU" SG_ 2566844672 BrkSw 500;
BA_ "GenSigTimeoutTime_Ecolife2" SG_ 2566844672 BrkSw 500;
BA_ "GenSigTimeoutTime_FMS4" SG_ 2566844672 BrkSw 500;
BA_ "GenSigTimeoutTime_IRCS" SG_ 2566844672 BrkSw 500;
BA_ "GenSigTimeoutTime_NBM" SG_ 2566844672 BrkSw 500;
BA_ "GenSigTimeoutTime_PCM" SG_ 2566844672 BrkSw 500;
BA_ "GenSigTimeoutTime_SGW2" SG_ 2566844672 BrkSw 500;
BA_ "GenSigTimeoutTime_SGW__" SG_ 2566844672 BrkSw 500;
BA_ "SPN" SG_ 2566844672 BrkSw 597;
BA_ "SigType" SG_ 2566844672 BrkSw 4;
BA_ "CI_ParId" SG_ 2566844672 CltSw "598";
BA_ "CI_SigId" SG_ 2566844672 CltSw 2088;
BA_ "CI_SigName" SG_ 2566844672 CltSw "Clutch Switch";
BA_ "GenSigTimeoutTime_ADCU" SG_ 2566844672 CltSw 500;
BA_ "GenSigTimeoutTime_EBS" SG_ 2566844672 CltSw 500;
BA_ "GenSigTimeoutTime_EBS___" SG_ 2566844672 CltSw 500;
BA_ "GenSigTimeoutTime_FMS4" SG_ 2566844672 CltSw 500;
BA_ "GenSigTimeoutTime_NBM" SG_ 2566844672 CltSw 500;
BA_ "GenSigTimeoutTime_PCM" SG_ 2566844672 CltSw 500;
BA_ "GenSigTimeoutTime_SGW2" SG_ 2566844672 CltSw 500;
BA_ "GenSigTimeoutTime_SGW__" SG_ 2566844672 CltSw 500;
BA_ "SPN" SG_ 2566844672 CltSw 598;
BA_ "SigType" SG_ 2566844672 CltSw 4;
BA_ "CI_ParId" SG_ 2566844672 CcSetSpeed "86";
BA_ "CI_SigId" SG_ 2566844672 CcSetSpeed 2093;
BA_ "CI_SigName" SG_ 2566844672 CcSetSpeed "Cruise Control Set Speed";
BA_ "GenSigTimeoutTime_ADCU" SG_ 2566844672 CcSetSpeed 500;
BA_ "GenSigTimeoutTime_MulticS" SG_ 2566844672 CcSetSpeed 500;
BA_ "GenSigTimeoutTime_MulticS_" SG_ 2566844672 CcSetSpeed 500;
BA_ "GenSigTimeoutTime_PCM" SG_ 2566844672 CcSetSpeed 500;
BA_ "GenSigTimeoutTime_SGW2" SG_ 2566844672 CcSetSpeed 500;
BA_ "GenSigTimeoutTime_SGW__" SG_ 2566844672 CcSetSpeed 500;
BA_ "SPN" SG_ 2566844672 CcSetSpeed 86;
BA_ "SigType" SG_ 2566844672 CcSetSpeed 1;
BA_ "CI_ParId" SG_ 2566844672 PtoGovSts "976";
BA_ "CI_SigId" SG_ 2566844672 PtoGovSts 2094;
BA_ "CI_SigName" SG_ 2566844672 PtoGovSts "PTO Governor State";
BA_ "GenSigTimeoutTime_FMS4" SG_ 2566844672 PtoGovSts 500;
BA_ "GenSigTimeoutTime_MulticS" SG_ 2566844672 PtoGovSts 500;
BA_ "GenSigTimeoutTime_PCM" SG_ 2566844672 PtoGovSts 500;
BA_ "GenSigTimeoutTime_SGW2" SG_ 2566844672 PtoGovSts 500;
BA_ "GenSigTimeoutTime_SGW__" SG_ 2566844672 PtoGovSts 500;
BA_ "SPN" SG_ 2566844672 PtoGovSts 976;
BA_ "CI_ParId" SG_ 2566844672 CcSts "527";
BA_ "CI_SigId" SG_ 2566844672 CcSts 2095;
BA_ "CI_SigName" SG_ 2566844672 CcSts "Cruise Control States";
BA_ "GenSigTimeoutTime_ADCU" SG_ 2566844672 CcSts 500;
BA_ "GenSigTimeoutTime_FMS4" SG_ 2566844672 CcSts 500;
BA_ "GenSigTimeoutTime_IRCS" SG_ 2566844672 CcSts 500;
BA_ "GenSigTimeoutTime_MulticS_" SG_ 2566844672 CcSts 500;
BA_ "GenSigTimeoutTime_PCM" SG_ 2566844672 CcSts 500;
BA_ "GenSigTimeoutTime_SGW2" SG_ 2566844672 CcSts 500;
BA_ "GenSigTimeoutTime_SGW__" SG_ 2566844672 CcSts 500;
BA_ "SPN" SG_ 2566844672 CcSts 527;
BA_ "CI_ParId" SG_ 2566890313 LastStopCause "IB126";
BA_ "CI_SigId" SG_ 2566890313 LastStopCause 1404;
BA_ "CI_SigName" SG_ 2566890313 LastStopCause "Last Stop Cause";
BA_ "GenSigTimeoutTime_MulticII" SG_ 2566890313 LastStopCause 25000;
BA_ "GenSigTimeoutTime_MulticS_" SG_ 2566890313 LastStopCause 25000;
BA_ "GenSigTimeoutTime_PCM" SG_ 2566890313 LastStopCause 25000;
BA_ "GenSigTimeoutTime_SGW__" SG_ 2566890313 LastStopCause 25000;
BA_ "CI_ParId" SG_ 2566890313 BefLastStopCause "IB127";
BA_ "CI_SigId" SG_ 2566890313 BefLastStopCause 1405;
BA_ "CI_SigName" SG_ 2566890313 BefLastStopCause "Before Last Stop Cause";
BA_ "GenSigTimeoutTime_MulticII" SG_ 2566890313 BefLastStopCause 25000;
BA_ "GenSigTimeoutTime_MulticS_" SG_ 2566890313 BefLastStopCause 25000;
BA_ "GenSigTimeoutTime_PCM" SG_ 2566890313 BefLastStopCause 25000;
BA_ "GenSigTimeoutTime_SGW__" SG_ 2566890313 BefLastStopCause 25000;
BA_ "CI_ParId" SG_ 2566843164 Make "586";
BA_ "CI_SigId" SG_ 2566843164 Make 10378;
BA_ "CI_SigName" SG_ 2566843164 Make "Make";
BA_ "SPN" SG_ 2566843164 Make 586;
BA_ "SigType" SG_ 2566843164 Make 8;
BA_ "CI_ParId" SG_ 2566843164 Model "587";
BA_ "CI_SigId" SG_ 2566843164 Model 10379;
BA_ "CI_SigName" SG_ 2566843164 Model "Model";
BA_ "SPN" SG_ 2566843164 Model 587;
BA_ "SigType" SG_ 2566843164 Model 8;
BA_ "CI_ParId" SG_ 2566843164 Sn "588";
BA_ "CI_SigId" SG_ 2566843164 Sn 10380;
BA_ "CI_SigName" SG_ 2566843164 Sn "Serial Number";
BA_ "SPN" SG_ 2566843164 Sn 588;
BA_ "SigType" SG_ 2566843164 Sn 8;
BA_ "CI_ParId" SG_ 2566843164 UnitNumPwrUnit "233";
BA_ "CI_SigId" SG_ 2566843164 UnitNumPwrUnit 10381;
BA_ "CI_SigName" SG_ 2566843164 UnitNumPwrUnit "Unit Number (Power Unit)";
BA_ "SPN" SG_ 2566843164 UnitNumPwrUnit 233;
BA_ "SigType" SG_ 2566843164 UnitNumPwrUnit 8;
BA_ "CI_ParId" SG_ 2566843165 Make_18FEEB1D "586";
BA_ "CI_SigId" SG_ 2566843165 Make_18FEEB1D 10383;
BA_ "CI_SigName" SG_ 2566843165 Make_18FEEB1D "Make";
BA_ "SPN" SG_ 2566843165 Make_18FEEB1D 586;
BA_ "SigType" SG_ 2566843165 Make_18FEEB1D 8;
BA_ "CI_ParId" SG_ 2566843165 Model_18FEEB1D "587";
BA_ "CI_SigId" SG_ 2566843165 Model_18FEEB1D 10384;
BA_ "CI_SigName" SG_ 2566843165 Model_18FEEB1D "Model";
BA_ "SPN" SG_ 2566843165 Model_18FEEB1D 587;
BA_ "SigType" SG_ 2566843165 Model_18FEEB1D 8;
BA_ "CI_ParId" SG_ 2566843165 Sn_18FEEB1D "588";
BA_ "CI_SigId" SG_ 2566843165 Sn_18FEEB1D 10385;
BA_ "CI_SigName" SG_ 2566843165 Sn_18FEEB1D "Serial Number";
BA_ "SPN" SG_ 2566843165 Sn_18FEEB1D 588;
BA_ "SigType" SG_ 2566843165 Sn_18FEEB1D 8;
BA_ "CI_ParId" SG_ 2566843165 UnitNumPwrUnit_18FEEB1D "233";
BA_ "CI_SigId" SG_ 2566843165 UnitNumPwrUnit_18FEEB1D 10386;
BA_ "CI_SigName" SG_ 2566843165 UnitNumPwrUnit_18FEEB1D "Unit Number (Power Unit)";
BA_ "SPN" SG_ 2566843165 UnitNumPwrUnit_18FEEB1D 233;
BA_ "SigType" SG_ 2566843165 UnitNumPwrUnit_18FEEB1D 8;
BA_ "CI_ParId" SG_ 2566843230 Model_18FEEB5E "587";
BA_ "CI_SigId" SG_ 2566843230 Model_18FEEB5E 10399;
BA_ "CI_SigName" SG_ 2566843230 Model_18FEEB5E "Model";
BA_ "SPN" SG_ 2566843230 Model_18FEEB5E 587;
BA_ "SigType" SG_ 2566843230 Model_18FEEB5E 8;
BA_ "CI_ParId" SG_ 2566865139 CoolSts "IB530";
BA_ "CI_SigId" SG_ 2566865139 CoolSts 3883;
BA_ "CI_SigName" SG_ 2566865139 CoolSts "Cooling state";
BA_ "GenSigTimeoutTime_MulticII" SG_ 2566865139 CoolSts 25000;
BA_ "GenSigTimeoutTime_MulticS_" SG_ 2566865139 CoolSts 25000;
BA_ "GenSigTimeoutTime_NBM_" SG_ 2566865139 CoolSts 25000;
BA_ "GenSigTimeoutTime_PCM" SG_ 2566865139 CoolSts 25000;
BA_ "GenSigTimeoutTime_SGW__" SG_ 2566865139 CoolSts 25000;
BA_ "CI_ParId" SG_ 2566811659 Gcvw "1760";
BA_ "CI_SigId" SG_ 2566811659 Gcvw 391;
BA_ "CI_SigName" SG_ 2566811659 Gcvw "Gross Combination Vehicle Weight";
BA_ "GenSigTimeoutTime_ADCU" SG_ 2566811659 Gcvw 5000;
BA_ "GenSigTimeoutTime_Ecolife2" SG_ 2566811659 Gcvw 5000;
BA_ "GenSigTimeoutTime_FMS4" SG_ 2566811659 Gcvw 5000;
BA_ "GenSigTimeoutTime_PCM" SG_ 2566811659 Gcvw 5000;
BA_ "GenSigTimeoutTime_SGW__" SG_ 2566811659 Gcvw 5000;
BA_ "SPN" SG_ 2566811659 Gcvw 1760;
BA_ "SigType" SG_ 2566811659 Gcvw 1;
BA_ "CI_ParId" SG_ 2566811695 Gcvw_18FE702F "1760";
BA_ "CI_SigId" SG_ 2566811695 Gcvw_18FE702F 17496;
BA_ "CI_SigName" SG_ 2566811695 Gcvw_18FE702F "Gross Combination Vehicle Weight";
BA_ "GenSigTimeoutTime_PCM" SG_ 2566811695 Gcvw_18FE702F 5000;
BA_ "GenSigTimeoutTime_SGW__" SG_ 2566811695 Gcvw_18FE702F 5000;
BA_ "SPN" SG_ 2566811695 Gcvw_18FE702F 1760;
BA_ "SigType" SG_ 2566811695 Gcvw_18FE702F 1;
BA_ "CI_ParId" SG_ 2566802967 PosOfDoors "1821";
BA_ "CI_SigId" SG_ 2566802967 PosOfDoors 3268;
BA_ "CI_SigName" SG_ 2566802967 PosOfDoors "Position of doors";
BA_ "GenSigTimeoutTime_ADCU" SG_ 2566802967 PosOfDoors 500;
BA_ "GenSigTimeoutTime_FMS4" SG_ 2566802967 PosOfDoors 500;
BA_ "GenSigTimeoutTime_PCM" SG_ 2566802967 PosOfDoors 500;
BA_ "GenSigTimeoutTime_SGW__" SG_ 2566802967 PosOfDoors 500;
BA_ "SPN" SG_ 2566802967 PosOfDoors 1821;
BA_ "CI_ParId" SG_ 2566802967 Ramp_WhChairLiftPos "1820";
BA_ "CI_SigId" SG_ 2566802967 Ramp_WhChairLiftPos 3269;
BA_ "CI_SigName" SG_ 2566802967 Ramp_WhChairLiftPos "Ramp / Wheel Chair Lift Position";
BA_ "GenSigTimeoutTime_FMS4" SG_ 2566802967 Ramp_WhChairLiftPos 500;
BA_ "GenSigTimeoutTime_PCM" SG_ 2566802967 Ramp_WhChairLiftPos 500;
BA_ "GenSigTimeoutTime_SGW__" SG_ 2566802967 Ramp_WhChairLiftPos 500;
BA_ "SPN" SG_ 2566802967 Ramp_WhChairLiftPos 1820;
BA_ "SigType" SG_ 2566802967 Ramp_WhChairLiftPos 4;
BA_ "CI_ParId" SG_ 2566802967 Sts2OfDoors "3411";
BA_ "CI_SigId" SG_ 2566802967 Sts2OfDoors 3270;
BA_ "CI_SigName" SG_ 2566802967 Sts2OfDoors "Status 2 of doors";
BA_ "GenSigTimeoutTime_FMS4" SG_ 2566802967 Sts2OfDoors 500;
BA_ "GenSigTimeoutTime_PCM" SG_ 2566802967 Sts2OfDoors 500;
BA_ "GenSigTimeoutTime_SGW__" SG_ 2566802967 Sts2OfDoors 500;
BA_ "SPN" SG_ 2566802967 Sts2OfDoors 3411;
BA_ "SigType" SG_ 2566802967 Sts2OfDoors 4;
BA_ "CI_ParId" SG_ 2566759703 LckStsOfDoor1 "3412";
BA_ "CI_SigId" SG_ 2566759703 LckStsOfDoor1 3272;
BA_ "CI_SigName" SG_ 2566759703 LckStsOfDoor1 "Lock Status of Door 1";
BA_ "GenSigTimeoutTime_FMS4" SG_ 2566759703 LckStsOfDoor1 500;
BA_ "GenSigTimeoutTime_PCM" SG_ 2566759703 LckStsOfDoor1 500;
BA_ "GenSigTimeoutTime_SGW__" SG_ 2566759703 LckStsOfDoor1 500;
BA_ "SPN" SG_ 2566759703 LckStsOfDoor1 3412;
BA_ "SigType" SG_ 2566759703 LckStsOfDoor1 4;
BA_ "CI_ParId" SG_ 2566759703 OpenStsOfDoor1 "3413";
BA_ "CI_SigId" SG_ 2566759703 OpenStsOfDoor1 3273;
BA_ "CI_SigName" SG_ 2566759703 OpenStsOfDoor1 "Open Status of Door 1";
BA_ "GenSigTimeoutTime_FMS4" SG_ 2566759703 OpenStsOfDoor1 500;
BA_ "GenSigTimeoutTime_PCM" SG_ 2566759703 OpenStsOfDoor1 500;
BA_ "GenSigTimeoutTime_SGW__" SG_ 2566759703 OpenStsOfDoor1 500;
BA_ "SPN" SG_ 2566759703 OpenStsOfDoor1 3413;
BA_ "SigType" SG_ 2566759703 OpenStsOfDoor1 4;
BA_ "CI_ParId" SG_ 2566759703 EnaStsOfDoor1 "3414";
BA_ "CI_SigId" SG_ 2566759703 EnaStsOfDoor1 3274;
BA_ "CI_SigName" SG_ 2566759703 EnaStsOfDoor1 "Enable Status of Door 1";
BA_ "GenSigTimeoutTime_FMS4" SG_ 2566759703 EnaStsOfDoor1 500;
BA_ "GenSigTimeoutTime_PCM" SG_ 2566759703 EnaStsOfDoor1 500;
BA_ "GenSigTimeoutTime_SGW__" SG_ 2566759703 EnaStsOfDoor1 500;
BA_ "SPN" SG_ 2566759703 EnaStsOfDoor1 3414;
BA_ "SigType" SG_ 2566759703 EnaStsOfDoor1 4;
BA_ "CI_ParId" SG_ 2566759703 LckStsOfDoor2 "3415";
BA_ "CI_SigId" SG_ 2566759703 LckStsOfDoor2 3275;
BA_ "CI_SigName" SG_ 2566759703 LckStsOfDoor2 "Lock Status of Door 2";
BA_ "GenSigTimeoutTime_FMS4" SG_ 2566759703 LckStsOfDoor2 500;
BA_ "GenSigTimeoutTime_PCM" SG_ 2566759703 LckStsOfDoor2 500;
BA_ "GenSigTimeoutTime_SGW__" SG_ 2566759703 LckStsOfDoor2 500;
BA_ "SPN" SG_ 2566759703 LckStsOfDoor2 3415;
BA_ "SigType" SG_ 2566759703 LckStsOfDoor2 4;
BA_ "CI_ParId" SG_ 2566759703 OpenStsOfDoor2 "3416";
BA_ "CI_SigId" SG_ 2566759703 OpenStsOfDoor2 3276;
BA_ "CI_SigName" SG_ 2566759703 OpenStsOfDoor2 "Open Status of Door 2";
BA_ "GenSigTimeoutTime_FMS4" SG_ 2566759703 OpenStsOfDoor2 500;
BA_ "GenSigTimeoutTime_PCM" SG_ 2566759703 OpenStsOfDoor2 500;
BA_ "GenSigTimeoutTime_SGW__" SG_ 2566759703 OpenStsOfDoor2 500;
BA_ "SPN" SG_ 2566759703 OpenStsOfDoor2 3416;
BA_ "SigType" SG_ 2566759703 OpenStsOfDoor2 4;
BA_ "CI_ParId" SG_ 2566759703 EnaStsOfDoor2 "3417";
BA_ "CI_SigId" SG_ 2566759703 EnaStsOfDoor2 3277;
BA_ "CI_SigName" SG_ 2566759703 EnaStsOfDoor2 "Enable Status of Door 2";
BA_ "GenSigTimeoutTime_FMS4" SG_ 2566759703 EnaStsOfDoor2 500;
BA_ "GenSigTimeoutTime_PCM" SG_ 2566759703 EnaStsOfDoor2 500;
BA_ "GenSigTimeoutTime_SGW__" SG_ 2566759703 EnaStsOfDoor2 500;
BA_ "SPN" SG_ 2566759703 EnaStsOfDoor2 3417;
BA_ "SigType" SG_ 2566759703 EnaStsOfDoor2 4;
BA_ "CI_ParId" SG_ 2566759703 LckStsOfDoor3 "3418";
BA_ "CI_SigId" SG_ 2566759703 LckStsOfDoor3 3278;
BA_ "CI_SigName" SG_ 2566759703 LckStsOfDoor3 "Lock Status of Door 3";
BA_ "GenSigTimeoutTime_FMS4" SG_ 2566759703 LckStsOfDoor3 500;
BA_ "GenSigTimeoutTime_PCM" SG_ 2566759703 LckStsOfDoor3 500;
BA_ "GenSigTimeoutTime_SGW__" SG_ 2566759703 LckStsOfDoor3 500;
BA_ "SPN" SG_ 2566759703 LckStsOfDoor3 3418;
BA_ "SigType" SG_ 2566759703 LckStsOfDoor3 4;
BA_ "CI_ParId" SG_ 2566759703 OpenStsOfDoor3 "3419";
BA_ "CI_SigId" SG_ 2566759703 OpenStsOfDoor3 3279;
BA_ "CI_SigName" SG_ 2566759703 OpenStsOfDoor3 "Open Status of Door 3";
BA_ "GenSigTimeoutTime_FMS4" SG_ 2566759703 OpenStsOfDoor3 500;
BA_ "GenSigTimeoutTime_PCM" SG_ 2566759703 OpenStsOfDoor3 500;
BA_ "GenSigTimeoutTime_SGW__" SG_ 2566759703 OpenStsOfDoor3 500;
BA_ "SPN" SG_ 2566759703 OpenStsOfDoor3 3419;
BA_ "SigType" SG_ 2566759703 OpenStsOfDoor3 4;
BA_ "CI_ParId" SG_ 2566759703 EnaStsOfDoor3 "3420";
BA_ "CI_SigId" SG_ 2566759703 EnaStsOfDoor3 3280;
BA_ "CI_SigName" SG_ 2566759703 EnaStsOfDoor3 "Enable Status of Door 3";
BA_ "GenSigTimeoutTime_FMS4" SG_ 2566759703 EnaStsOfDoor3 500;
BA_ "GenSigTimeoutTime_PCM" SG_ 2566759703 EnaStsOfDoor3 500;
BA_ "GenSigTimeoutTime_SGW__" SG_ 2566759703 EnaStsOfDoor3 500;
BA_ "SPN" SG_ 2566759703 EnaStsOfDoor3 3420;
BA_ "SigType" SG_ 2566759703 EnaStsOfDoor3 4;
BA_ "CI_ParId" SG_ 2566759703 LckStsOfDoor4 "3421";
BA_ "CI_SigId" SG_ 2566759703 LckStsOfDoor4 3281;
BA_ "CI_SigName" SG_ 2566759703 LckStsOfDoor4 "Lock Status of Door 4";
BA_ "GenSigTimeoutTime_FMS4" SG_ 2566759703 LckStsOfDoor4 500;
BA_ "GenSigTimeoutTime_PCM" SG_ 2566759703 LckStsOfDoor4 500;
BA_ "GenSigTimeoutTime_SGW__" SG_ 2566759703 LckStsOfDoor4 500;
BA_ "SPN" SG_ 2566759703 LckStsOfDoor4 3421;
BA_ "SigType" SG_ 2566759703 LckStsOfDoor4 4;
BA_ "CI_ParId" SG_ 2566759703 OpenStsOfDoor4 "3422";
BA_ "CI_SigId" SG_ 2566759703 OpenStsOfDoor4 3282;
BA_ "CI_SigName" SG_ 2566759703 OpenStsOfDoor4 "Open Status of Door 4";
BA_ "GenSigTimeoutTime_FMS4" SG_ 2566759703 OpenStsOfDoor4 500;
BA_ "GenSigTimeoutTime_PCM" SG_ 2566759703 OpenStsOfDoor4 500;
BA_ "GenSigTimeoutTime_SGW__" SG_ 2566759703 OpenStsOfDoor4 500;
BA_ "SPN" SG_ 2566759703 OpenStsOfDoor4 3422;
BA_ "SigType" SG_ 2566759703 OpenStsOfDoor4 4;
BA_ "CI_ParId" SG_ 2566759703 EnaStsOfDoor4 "3423";
BA_ "CI_SigId" SG_ 2566759703 EnaStsOfDoor4 3283;
BA_ "CI_SigName" SG_ 2566759703 EnaStsOfDoor4 "Enable Status of Door 4";
BA_ "GenSigTimeoutTime_FMS4" SG_ 2566759703 EnaStsOfDoor4 500;
BA_ "GenSigTimeoutTime_PCM" SG_ 2566759703 EnaStsOfDoor4 500;
BA_ "GenSigTimeoutTime_SGW__" SG_ 2566759703 EnaStsOfDoor4 500;
BA_ "SPN" SG_ 2566759703 EnaStsOfDoor4 3423;
BA_ "SigType" SG_ 2566759703 EnaStsOfDoor4 4;
BA_ "CI_ParId" SG_ 2566759703 LckStsOfDoor5 "3424";
BA_ "CI_SigId" SG_ 2566759703 LckStsOfDoor5 3284;
BA_ "CI_SigName" SG_ 2566759703 LckStsOfDoor5 "Lock Status of Door 5";
BA_ "GenSigTimeoutTime_PCM" SG_ 2566759703 LckStsOfDoor5 500;
BA_ "GenSigTimeoutTime_SGW__" SG_ 2566759703 LckStsOfDoor5 500;
BA_ "SPN" SG_ 2566759703 LckStsOfDoor5 3424;
BA_ "SigType" SG_ 2566759703 LckStsOfDoor5 4;
BA_ "CI_ParId" SG_ 2566759703 OpenStsOfDoor5 "3425";
BA_ "CI_SigId" SG_ 2566759703 OpenStsOfDoor5 3285;
BA_ "CI_SigName" SG_ 2566759703 OpenStsOfDoor5 "Open Status of Door 5";
BA_ "GenSigTimeoutTime_PCM" SG_ 2566759703 OpenStsOfDoor5 500;
BA_ "GenSigTimeoutTime_SGW__" SG_ 2566759703 OpenStsOfDoor5 500;
BA_ "SPN" SG_ 2566759703 OpenStsOfDoor5 3425;
BA_ "SigType" SG_ 2566759703 OpenStsOfDoor5 4;
BA_ "CI_ParId" SG_ 2566759703 EnaStsOfDoor5 "3426";
BA_ "CI_SigId" SG_ 2566759703 EnaStsOfDoor5 3286;
BA_ "CI_SigName" SG_ 2566759703 EnaStsOfDoor5 "Enable Status of Door 5";
BA_ "GenSigTimeoutTime_PCM" SG_ 2566759703 EnaStsOfDoor5 500;
BA_ "GenSigTimeoutTime_SGW__" SG_ 2566759703 EnaStsOfDoor5 500;
BA_ "SPN" SG_ 2566759703 EnaStsOfDoor5 3426;
BA_ "SigType" SG_ 2566759703 EnaStsOfDoor5 4;
BA_ "CI_ParId" SG_ 2566759703 LckStsOfDoor6 "3427";
BA_ "CI_SigId" SG_ 2566759703 LckStsOfDoor6 3287;
BA_ "CI_SigName" SG_ 2566759703 LckStsOfDoor6 "Lock Status of Door 6";
BA_ "GenSigTimeoutTime_PCM" SG_ 2566759703 LckStsOfDoor6 500;
BA_ "GenSigTimeoutTime_SGW__" SG_ 2566759703 LckStsOfDoor6 500;
BA_ "SPN" SG_ 2566759703 LckStsOfDoor6 3427;
BA_ "SigType" SG_ 2566759703 LckStsOfDoor6 4;
BA_ "CI_ParId" SG_ 2566759703 OpenStsOfDoor6 "3428";
BA_ "CI_SigId" SG_ 2566759703 OpenStsOfDoor6 3288;
BA_ "CI_SigName" SG_ 2566759703 OpenStsOfDoor6 "Open Status of Door 6";
BA_ "GenSigTimeoutTime_PCM" SG_ 2566759703 OpenStsOfDoor6 500;
BA_ "GenSigTimeoutTime_SGW__" SG_ 2566759703 OpenStsOfDoor6 500;
BA_ "SPN" SG_ 2566759703 OpenStsOfDoor6 3428;
BA_ "SigType" SG_ 2566759703 OpenStsOfDoor6 4;
BA_ "CI_ParId" SG_ 2566759703 EnaStsOfDoor6 "3429";
BA_ "CI_SigId" SG_ 2566759703 EnaStsOfDoor6 3289;
BA_ "CI_SigName" SG_ 2566759703 EnaStsOfDoor6 "Enable Status of Door 6";
BA_ "GenSigTimeoutTime_PCM" SG_ 2566759703 EnaStsOfDoor6 500;
BA_ "GenSigTimeoutTime_SGW__" SG_ 2566759703 EnaStsOfDoor6 500;
BA_ "SPN" SG_ 2566759703 EnaStsOfDoor6 3429;
BA_ "SigType" SG_ 2566759703 EnaStsOfDoor6 4;
BA_ "CI_ParId" SG_ 2566759703 LckStsOfDoor7 "3430";
BA_ "CI_SigId" SG_ 2566759703 LckStsOfDoor7 3290;
BA_ "CI_SigName" SG_ 2566759703 LckStsOfDoor7 "Lock Status of Door 7";
BA_ "GenSigTimeoutTime_PCM" SG_ 2566759703 LckStsOfDoor7 500;
BA_ "GenSigTimeoutTime_SGW__" SG_ 2566759703 LckStsOfDoor7 500;
BA_ "SPN" SG_ 2566759703 LckStsOfDoor7 3430;
BA_ "SigType" SG_ 2566759703 LckStsOfDoor7 4;
BA_ "CI_ParId" SG_ 2566759703 OpenStsOfDoor7 "3431";
BA_ "CI_SigId" SG_ 2566759703 OpenStsOfDoor7 3291;
BA_ "CI_SigName" SG_ 2566759703 OpenStsOfDoor7 "Open Status of Door 7";
BA_ "GenSigTimeoutTime_PCM" SG_ 2566759703 OpenStsOfDoor7 500;
BA_ "GenSigTimeoutTime_SGW__" SG_ 2566759703 OpenStsOfDoor7 500;
BA_ "SPN" SG_ 2566759703 OpenStsOfDoor7 3431;
BA_ "SigType" SG_ 2566759703 OpenStsOfDoor7 4;
BA_ "CI_ParId" SG_ 2566759703 EnaStsOfDoor7 "3432";
BA_ "CI_SigId" SG_ 2566759703 EnaStsOfDoor7 3292;
BA_ "CI_SigName" SG_ 2566759703 EnaStsOfDoor7 "Enable Status of Door 7";
BA_ "GenSigTimeoutTime_PCM" SG_ 2566759703 EnaStsOfDoor7 500;
BA_ "GenSigTimeoutTime_SGW__" SG_ 2566759703 EnaStsOfDoor7 500;
BA_ "SPN" SG_ 2566759703 EnaStsOfDoor7 3432;
BA_ "SigType" SG_ 2566759703 EnaStsOfDoor7 4;
BA_ "CI_ParId" SG_ 2566759703 LckStsOfDoor8 "3433";
BA_ "CI_SigId" SG_ 2566759703 LckStsOfDoor8 3293;
BA_ "CI_SigName" SG_ 2566759703 LckStsOfDoor8 "Lock Status of Door 8";
BA_ "GenSigTimeoutTime_PCM" SG_ 2566759703 LckStsOfDoor8 500;
BA_ "GenSigTimeoutTime_SGW__" SG_ 2566759703 LckStsOfDoor8 500;
BA_ "SPN" SG_ 2566759703 LckStsOfDoor8 3433;
BA_ "SigType" SG_ 2566759703 LckStsOfDoor8 4;
BA_ "CI_ParId" SG_ 2566759703 OpenStsOfDoor8 "3434";
BA_ "CI_SigId" SG_ 2566759703 OpenStsOfDoor8 3294;
BA_ "CI_SigName" SG_ 2566759703 OpenStsOfDoor8 "Open Status of Door 8";
BA_ "GenSigTimeoutTime_PCM" SG_ 2566759703 OpenStsOfDoor8 500;
BA_ "GenSigTimeoutTime_SGW__" SG_ 2566759703 OpenStsOfDoor8 500;
BA_ "SPN" SG_ 2566759703 OpenStsOfDoor8 3434;
BA_ "SigType" SG_ 2566759703 OpenStsOfDoor8 4;
BA_ "CI_ParId" SG_ 2566759703 EnaStsOfDoor8 "3435";
BA_ "CI_SigId" SG_ 2566759703 EnaStsOfDoor8 3295;
BA_ "CI_SigName" SG_ 2566759703 EnaStsOfDoor8 "Enable Status of Door 8";
BA_ "GenSigTimeoutTime_PCM" SG_ 2566759703 EnaStsOfDoor8 500;
BA_ "GenSigTimeoutTime_SGW__" SG_ 2566759703 EnaStsOfDoor8 500;
BA_ "SPN" SG_ 2566759703 EnaStsOfDoor8 3435;
BA_ "SigType" SG_ 2566759703 EnaStsOfDoor8 4;
BA_ "CI_ParId" SG_ 2566759703 LckStsOfDoor9 "3436";
BA_ "CI_SigId" SG_ 2566759703 LckStsOfDoor9 3296;
BA_ "CI_SigName" SG_ 2566759703 LckStsOfDoor9 "Lock Status of Door 9";
BA_ "GenSigTimeoutTime_PCM" SG_ 2566759703 LckStsOfDoor9 500;
BA_ "GenSigTimeoutTime_SGW__" SG_ 2566759703 LckStsOfDoor9 500;
BA_ "SPN" SG_ 2566759703 LckStsOfDoor9 3436;
BA_ "SigType" SG_ 2566759703 LckStsOfDoor9 4;
BA_ "CI_ParId" SG_ 2566759703 OpenStsOfDoor9 "3437";
BA_ "CI_SigId" SG_ 2566759703 OpenStsOfDoor9 3297;
BA_ "CI_SigName" SG_ 2566759703 OpenStsOfDoor9 "Open Status of Door 9";
BA_ "GenSigTimeoutTime_PCM" SG_ 2566759703 OpenStsOfDoor9 500;
BA_ "GenSigTimeoutTime_SGW__" SG_ 2566759703 OpenStsOfDoor9 500;
BA_ "SPN" SG_ 2566759703 OpenStsOfDoor9 3437;
BA_ "SigType" SG_ 2566759703 OpenStsOfDoor9 4;
BA_ "CI_ParId" SG_ 2566759703 EnaStsOfDoor9 "3438";
BA_ "CI_SigId" SG_ 2566759703 EnaStsOfDoor9 3298;
BA_ "CI_SigName" SG_ 2566759703 EnaStsOfDoor9 "Enable Status of Door 9";
BA_ "GenSigTimeoutTime_PCM" SG_ 2566759703 EnaStsOfDoor9 500;
BA_ "GenSigTimeoutTime_SGW__" SG_ 2566759703 EnaStsOfDoor9 500;
BA_ "SPN" SG_ 2566759703 EnaStsOfDoor9 3438;
BA_ "SigType" SG_ 2566759703 EnaStsOfDoor9 4;
BA_ "CI_ParId" SG_ 2566759703 LckStsOfDoor10 "3439";
BA_ "CI_SigId" SG_ 2566759703 LckStsOfDoor10 3299;
BA_ "CI_SigName" SG_ 2566759703 LckStsOfDoor10 "Lock Status of Door 10";
BA_ "GenSigTimeoutTime_PCM" SG_ 2566759703 LckStsOfDoor10 500;
BA_ "GenSigTimeoutTime_SGW__" SG_ 2566759703 LckStsOfDoor10 500;
BA_ "SPN" SG_ 2566759703 LckStsOfDoor10 3439;
BA_ "SigType" SG_ 2566759703 LckStsOfDoor10 4;
BA_ "CI_ParId" SG_ 2566759703 OpenStsOfDoor10 "3440";
BA_ "CI_SigId" SG_ 2566759703 OpenStsOfDoor10 3300;
BA_ "CI_SigName" SG_ 2566759703 OpenStsOfDoor10 "Open Status of Door 10";
BA_ "GenSigTimeoutTime_PCM" SG_ 2566759703 OpenStsOfDoor10 500;
BA_ "GenSigTimeoutTime_SGW__" SG_ 2566759703 OpenStsOfDoor10 500;
BA_ "SPN" SG_ 2566759703 OpenStsOfDoor10 3440;
BA_ "SigType" SG_ 2566759703 OpenStsOfDoor10 4;
BA_ "CI_ParId" SG_ 2566759703 EnaStsOfDoor10 "3441";
BA_ "CI_SigId" SG_ 2566759703 EnaStsOfDoor10 3301;
BA_ "CI_SigName" SG_ 2566759703 EnaStsOfDoor10 "Enable Status of Door 10";
BA_ "GenSigTimeoutTime_PCM" SG_ 2566759703 EnaStsOfDoor10 500;
BA_ "GenSigTimeoutTime_SGW__" SG_ 2566759703 EnaStsOfDoor10 500;
BA_ "SPN" SG_ 2566759703 EnaStsOfDoor10 3441;
BA_ "SigType" SG_ 2566759703 EnaStsOfDoor10 4;
BA_ "CI_ParId" SG_ 2566849774 DrivItsPersDataCons "V095";
BA_ "CI_SigId" SG_ 2566849774 DrivItsPersDataCons 2582;
BA_ "CI_SigName" SG_ 2566849774 DrivItsPersDataCons "Driver ITS Personal Data Consent";
BA_ "CI_ParId" SG_ 2566849774 CodriverItsPersDataCons "V096";
BA_ "CI_SigId" SG_ 2566849774 CodriverItsPersDataCons 2583;
BA_ "CI_SigName" SG_ 2566849774 CodriverItsPersDataCons "Codriver ITS Personal Data Consent";
BA_ "CI_ParId" SG_ 2566849774 DrivVdoPersDataCons "V097";
BA_ "CI_SigId" SG_ 2566849774 DrivVdoPersDataCons 2584;
BA_ "CI_SigName" SG_ 2566849774 DrivVdoPersDataCons "Driver VDO Personal Data Consent";
BA_ "CI_ParId" SG_ 2566849774 CodriverVdoPersDataCons "V098";
BA_ "CI_SigId" SG_ 2566849774 CodriverVdoPersDataCons 2585;
BA_ "CI_SigName" SG_ 2566849774 CodriverVdoPersDataCons "Codriver VDO Personal Data Consent";
BA_ "CI_ParId" SG_ 2566847521 FuelLev1 "96";
BA_ "CI_SigId" SG_ 2566847521 FuelLev1 3000;
BA_ "CI_SigName" SG_ 2566847521 FuelLev1 "Fuel Level 1";
BA_ "GenSigTimeoutTime_FMS4" SG_ 2566847521 FuelLev1 5000;
BA_ "GenSigTimeoutTime_MulticS" SG_ 2566847521 FuelLev1 5000;
BA_ "GenSigTimeoutTime_MulticS__" SG_ 2566847521 FuelLev1 5000;
BA_ "GenSigTimeoutTime_PCM" SG_ 2566847521 FuelLev1 5000;
BA_ "GenSigTimeoutTime_SGW__" SG_ 2566847521 FuelLev1 5000;
BA_ "GenSigTimeoutTime_VCM" SG_ 2566847521 FuelLev1 5000;
BA_ "SPN" SG_ 2566847521 FuelLev1 96;
BA_ "SigType" SG_ 2566847521 FuelLev1 1;
BA_ "CI_ParId" SG_ 2566810606 Driv1Id "1625";
BA_ "CI_SigId" SG_ 2566810606 Driv1Id 730;
BA_ "CI_SigName" SG_ 2566810606 Driv1Id "Driver 1 identification";
BA_ "SPN" SG_ 2566810606 Driv1Id 1625;
BA_ "SigType" SG_ 2566810606 Driv1Id 8;
BA_ "CI_ParId" SG_ 2566810606 Driv2Id "1626";
BA_ "CI_SigId" SG_ 2566810606 Driv2Id 731;
BA_ "CI_SigName" SG_ 2566810606 Driv2Id "Driver 2 identification";
BA_ "SPN" SG_ 2566810606 Driv2Id 1626;
BA_ "SigType" SG_ 2566810606 Driv2Id 8;
BA_ "CI_ParId" SG_ 2566834688 ProtLamp "987";
BA_ "CI_SigId" SG_ 2566834688 ProtLamp 4457;
BA_ "CI_SigName" SG_ 2566834688 ProtLamp "Protect Lamp";
BA_ "GenSigSendType" SG_ 2566834688 ProtLamp 3;
BA_ "GenSigTimeoutTime_FMS4" SG_ 2566834688 ProtLamp 5000;
BA_ "GenSigTimeoutTime_MulticS" SG_ 2566834688 ProtLamp 5000;
BA_ "GenSigTimeoutTime_MulticS__" SG_ 2566834688 ProtLamp 5000;
BA_ "GenSigTimeoutTime_NBM" SG_ 2566834688 ProtLamp 5000;
BA_ "GenSigTimeoutTime_PCM" SG_ 2566834688 ProtLamp 5000;
BA_ "GenSigTimeoutTime_SGW__" SG_ 2566834688 ProtLamp 5000;
BA_ "GenSigTimeoutTime_VCM_" SG_ 2566834688 ProtLamp 5000;
BA_ "GenSigTimeoutTime_VCM__" SG_ 2566834688 ProtLamp 5000;
BA_ "SPN" SG_ 2566834688 ProtLamp 987;
BA_ "SigType" SG_ 2566834688 ProtLamp 4;
BA_ "CI_ParId" SG_ 2566834691 ProtLamp_18FECA03 "987";
BA_ "CI_SigId" SG_ 2566834691 ProtLamp_18FECA03 4566;
BA_ "CI_SigName" SG_ 2566834691 ProtLamp_18FECA03 "Protect Lamp";
BA_ "GenSigSendType" SG_ 2566834691 ProtLamp_18FECA03 3;
BA_ "GenSigTimeoutTime_FMS4" SG_ 2566834691 ProtLamp_18FECA03 5000;
BA_ "GenSigTimeoutTime_MulticS" SG_ 2566834691 ProtLamp_18FECA03 5000;
BA_ "GenSigTimeoutTime_MulticS__" SG_ 2566834691 ProtLamp_18FECA03 5000;
BA_ "GenSigTimeoutTime_PCM" SG_ 2566834691 ProtLamp_18FECA03 5000;
BA_ "GenSigTimeoutTime_SGW__" SG_ 2566834691 ProtLamp_18FECA03 5000;
BA_ "SPN" SG_ 2566834691 ProtLamp_18FECA03 987;
BA_ "SigType" SG_ 2566834691 ProtLamp_18FECA03 4;
BA_ "CI_ParId" SG_ 2566834699 ProtLamp_18FECA0B "987";
BA_ "CI_SigId" SG_ 2566834699 ProtLamp_18FECA0B 4625;
BA_ "CI_SigName" SG_ 2566834699 ProtLamp_18FECA0B "Protect Lamp";
BA_ "GenSigSendType" SG_ 2566834699 ProtLamp_18FECA0B 3;
BA_ "GenSigTimeoutTime_FMS4" SG_ 2566834699 ProtLamp_18FECA0B 5000;
BA_ "GenSigTimeoutTime_MulticS" SG_ 2566834699 ProtLamp_18FECA0B 5000;
BA_ "GenSigTimeoutTime_MulticS_" SG_ 2566834699 ProtLamp_18FECA0B 5000;
BA_ "GenSigTimeoutTime_PCM" SG_ 2566834699 ProtLamp_18FECA0B 5000;
BA_ "GenSigTimeoutTime_SGW__" SG_ 2566834699 ProtLamp_18FECA0B 5000;
BA_ "SPN" SG_ 2566834699 ProtLamp_18FECA0B 987;
BA_ "SigType" SG_ 2566834699 ProtLamp_18FECA0B 4;
BA_ "CI_ParId" SG_ 2566834704 ProtLamp_18FECA10 "987";
BA_ "CI_SigId" SG_ 2566834704 ProtLamp_18FECA10 4680;
BA_ "CI_SigName" SG_ 2566834704 ProtLamp_18FECA10 "Protect Lamp";
BA_ "GenSigSendType" SG_ 2566834704 ProtLamp_18FECA10 3;
BA_ "GenSigTimeoutTime_FMS4" SG_ 2566834704 ProtLamp_18FECA10 5000;
BA_ "GenSigTimeoutTime_MulticS" SG_ 2566834704 ProtLamp_18FECA10 5000;
BA_ "GenSigTimeoutTime_PCM" SG_ 2566834704 ProtLamp_18FECA10 5000;
BA_ "GenSigTimeoutTime_SGW__" SG_ 2566834704 ProtLamp_18FECA10 5000;
BA_ "SPN" SG_ 2566834704 ProtLamp_18FECA10 987;
BA_ "SigType" SG_ 2566834704 ProtLamp_18FECA10 4;
BA_ "CI_ParId" SG_ 2566834711 ProtLamp_18FECA17 "987";
BA_ "CI_SigId" SG_ 2566834711 ProtLamp_18FECA17 4739;
BA_ "CI_SigName" SG_ 2566834711 ProtLamp_18FECA17 "Protect Lamp";
BA_ "GenSigSendType" SG_ 2566834711 ProtLamp_18FECA17 3;
BA_ "GenSigTimeoutTime_FMS4" SG_ 2566834711 ProtLamp_18FECA17 5000;
BA_ "GenSigTimeoutTime_PCM" SG_ 2566834711 ProtLamp_18FECA17 5000;
BA_ "GenSigTimeoutTime_SGW__" SG_ 2566834711 ProtLamp_18FECA17 5000;
BA_ "SPN" SG_ 2566834711 ProtLamp_18FECA17 987;
BA_ "SigType" SG_ 2566834711 ProtLamp_18FECA17 4;
BA_ "CI_ParId" SG_ 2566834716 ProtLamp_18FECA1C "987";
BA_ "CI_SigId" SG_ 2566834716 ProtLamp_18FECA1C 5009;
BA_ "CI_SigName" SG_ 2566834716 ProtLamp_18FECA1C "Protect Lamp";
BA_ "GenSigSendType" SG_ 2566834716 ProtLamp_18FECA1C 3;
BA_ "GenSigTimeoutTime_MulticS" SG_ 2566834716 ProtLamp_18FECA1C 5000;
BA_ "GenSigTimeoutTime_MulticS_" SG_ 2566834716 ProtLamp_18FECA1C 5000;
BA_ "GenSigTimeoutTime_PCM" SG_ 2566834716 ProtLamp_18FECA1C 5000;
BA_ "GenSigTimeoutTime_SGW_" SG_ 2566834716 ProtLamp_18FECA1C 5000;
BA_ "SPN" SG_ 2566834716 ProtLamp_18FECA1C 987;
BA_ "SigType" SG_ 2566834716 ProtLamp_18FECA1C 4;
BA_ "CI_ParId" SG_ 2566834717 ProtLamp_18FECA1D "987";
BA_ "CI_SigId" SG_ 2566834717 ProtLamp_18FECA1D 5064;
BA_ "CI_SigName" SG_ 2566834717 ProtLamp_18FECA1D "Protect Lamp";
BA_ "GenSigSendType" SG_ 2566834717 ProtLamp_18FECA1D 3;
BA_ "GenSigTimeoutTime_FMS4" SG_ 2566834717 ProtLamp_18FECA1D 5000;
BA_ "GenSigTimeoutTime_MulticS" SG_ 2566834717 ProtLamp_18FECA1D 5000;
BA_ "GenSigTimeoutTime_MulticS_" SG_ 2566834717 ProtLamp_18FECA1D 5000;
BA_ "GenSigTimeoutTime_MulticS__" SG_ 2566834717 ProtLamp_18FECA1D 5000;
BA_ "GenSigTimeoutTime_PCM" SG_ 2566834717 ProtLamp_18FECA1D 5000;
BA_ "SPN" SG_ 2566834717 ProtLamp_18FECA1D 987;
BA_ "SigType" SG_ 2566834717 ProtLamp_18FECA1D 4;
BA_ "CI_ParId" SG_ 2566834721 ProtLamp_18FECA21 "987";
BA_ "CI_SigId" SG_ 2566834721 ProtLamp_18FECA21 5119;
BA_ "CI_SigName" SG_ 2566834721 ProtLamp_18FECA21 "Protect Lamp";
BA_ "GenSigSendType" SG_ 2566834721 ProtLamp_18FECA21 3;
BA_ "GenSigTimeoutTime_FMS4" SG_ 2566834721 ProtLamp_18FECA21 5000;
BA_ "GenSigTimeoutTime_MulticS_" SG_ 2566834721 ProtLamp_18FECA21 5000;
BA_ "GenSigTimeoutTime_PCM" SG_ 2566834721 ProtLamp_18FECA21 5000;
BA_ "GenSigTimeoutTime_SGW__" SG_ 2566834721 ProtLamp_18FECA21 5000;
BA_ "SPN" SG_ 2566834721 ProtLamp_18FECA21 987;
BA_ "SigType" SG_ 2566834721 ProtLamp_18FECA21 4;
BA_ "CI_ParId" SG_ 2566834727 ProtLamp_18FECA27 "987";
BA_ "CI_SigId" SG_ 2566834727 ProtLamp_18FECA27 5174;
BA_ "CI_SigName" SG_ 2566834727 ProtLamp_18FECA27 "Protect Lamp";
BA_ "GenSigTimeoutTime_FMS4" SG_ 2566834727 ProtLamp_18FECA27 5000;
BA_ "GenSigTimeoutTime_MulticS" SG_ 2566834727 ProtLamp_18FECA27 5000;
BA_ "GenSigTimeoutTime_PCM" SG_ 2566834727 ProtLamp_18FECA27 5000;
BA_ "GenSigTimeoutTime_SGW__" SG_ 2566834727 ProtLamp_18FECA27 5000;
BA_ "SPN" SG_ 2566834727 ProtLamp_18FECA27 987;
BA_ "SigType" SG_ 2566834727 ProtLamp_18FECA27 4;
BA_ "CI_ParId" SG_ 2566834734 ProtLamp_18FECA2E "987";
BA_ "CI_SigId" SG_ 2566834734 ProtLamp_18FECA2E 5284;
BA_ "CI_SigName" SG_ 2566834734 ProtLamp_18FECA2E "Protect Lamp";
BA_ "GenSigSendType" SG_ 2566834734 ProtLamp_18FECA2E 3;
BA_ "GenSigTimeoutTime_FMS4" SG_ 2566834734 ProtLamp_18FECA2E 5000;
BA_ "GenSigTimeoutTime_MulticS_" SG_ 2566834734 ProtLamp_18FECA2E 5000;
BA_ "GenSigTimeoutTime_PCM" SG_ 2566834734 ProtLamp_18FECA2E 5000;
BA_ "GenSigTimeoutTime_SGW__" SG_ 2566834734 ProtLamp_18FECA2E 5000;
BA_ "SPN" SG_ 2566834734 ProtLamp_18FECA2E 987;
BA_ "SigType" SG_ 2566834734 ProtLamp_18FECA2E 4;
BA_ "CI_ParId" SG_ 2566834735 ProtLamp_18FECA2F "987";
BA_ "CI_SigId" SG_ 2566834735 ProtLamp_18FECA2F 5339;
BA_ "CI_SigName" SG_ 2566834735 ProtLamp_18FECA2F "Protect Lamp";
BA_ "GenSigSendType" SG_ 2566834735 ProtLamp_18FECA2F 3;
BA_ "GenSigTimeoutTime_FMS4" SG_ 2566834735 ProtLamp_18FECA2F 5000;
BA_ "GenSigTimeoutTime_MulticS" SG_ 2566834735 ProtLamp_18FECA2F 5000;
BA_ "GenSigTimeoutTime_MulticS_" SG_ 2566834735 ProtLamp_18FECA2F 5000;
BA_ "GenSigTimeoutTime_PCM" SG_ 2566834735 ProtLamp_18FECA2F 5000;
BA_ "GenSigTimeoutTime_SGW__" SG_ 2566834735 ProtLamp_18FECA2F 5000;
BA_ "SPN" SG_ 2566834735 ProtLamp_18FECA2F 987;
BA_ "SigType" SG_ 2566834735 ProtLamp_18FECA2F 4;
BA_ "CI_ParId" SG_ 2566834739 ProtLamp_18FECA33 "987";
BA_ "CI_SigId" SG_ 2566834739 ProtLamp_18FECA33 5449;
BA_ "CI_SigName" SG_ 2566834739 ProtLamp_18FECA33 "Protect Lamp";
BA_ "GenSigSendType" SG_ 2566834739 ProtLamp_18FECA33 3;
BA_ "GenSigTimeoutTime_FMS4" SG_ 2566834739 ProtLamp_18FECA33 5000;
BA_ "GenSigTimeoutTime_MulticS" SG_ 2566834739 ProtLamp_18FECA33 5000;
BA_ "GenSigTimeoutTime_MulticS_" SG_ 2566834739 ProtLamp_18FECA33 5000;
BA_ "GenSigTimeoutTime_MulticS__" SG_ 2566834739 ProtLamp_18FECA33 5000;
BA_ "GenSigTimeoutTime_PCM" SG_ 2566834739 ProtLamp_18FECA33 5000;
BA_ "GenSigTimeoutTime_SGW__" SG_ 2566834739 ProtLamp_18FECA33 5000;
BA_ "SPN" SG_ 2566834739 ProtLamp_18FECA33 987;
BA_ "SigType" SG_ 2566834739 ProtLamp_18FECA33 4;
BA_ "CI_ParId" SG_ 2566834744 ProtLamp_18FECA38 "987";
BA_ "CI_SigId" SG_ 2566834744 ProtLamp_18FECA38 5504;
BA_ "CI_SigName" SG_ 2566834744 ProtLamp_18FECA38 "Protect Lamp";
BA_ "GenSigSendType" SG_ 2566834744 ProtLamp_18FECA38 3;
BA_ "GenSigTimeoutTime_FMS4" SG_ 2566834744 ProtLamp_18FECA38 5000;
BA_ "GenSigTimeoutTime_MulticS" SG_ 2566834744 ProtLamp_18FECA38 5000;
BA_ "GenSigTimeoutTime_PCM" SG_ 2566834744 ProtLamp_18FECA38 5000;
BA_ "GenSigTimeoutTime_SGW__" SG_ 2566834744 ProtLamp_18FECA38 5000;
BA_ "SPN" SG_ 2566834744 ProtLamp_18FECA38 987;
BA_ "SigType" SG_ 2566834744 ProtLamp_18FECA38 4;
BA_ "CI_ParId" SG_ 2566834752 ProtLamp_18FECA40 "987";
BA_ "CI_SigId" SG_ 2566834752 ProtLamp_18FECA40 5794;
BA_ "CI_SigName" SG_ 2566834752 ProtLamp_18FECA40 "Protect Lamp";
BA_ "GenSigSendType" SG_ 2566834752 ProtLamp_18FECA40 3;
BA_ "GenSigTimeoutTime_FMS4" SG_ 2566834752 ProtLamp_18FECA40 5000;
BA_ "GenSigTimeoutTime_PCM" SG_ 2566834752 ProtLamp_18FECA40 5000;
BA_ "GenSigTimeoutTime_SGW__" SG_ 2566834752 ProtLamp_18FECA40 5000;
BA_ "SPN" SG_ 2566834752 ProtLamp_18FECA40 987;
BA_ "SigType" SG_ 2566834752 ProtLamp_18FECA40 4;
BA_ "CI_ParId" SG_ 2566834761 ProtLamp_18FECA49 "987";
BA_ "CI_SigId" SG_ 2566834761 ProtLamp_18FECA49 4954;
BA_ "CI_SigName" SG_ 2566834761 ProtLamp_18FECA49 "Protect Lamp";
BA_ "GenSigSendType" SG_ 2566834761 ProtLamp_18FECA49 3;
BA_ "GenSigTimeoutTime_FMS4" SG_ 2566834761 ProtLamp_18FECA49 5000;
BA_ "GenSigTimeoutTime_MulticS_" SG_ 2566834761 ProtLamp_18FECA49 5000;
BA_ "GenSigTimeoutTime_PCM" SG_ 2566834761 ProtLamp_18FECA49 5000;
BA_ "GenSigTimeoutTime_SGW__" SG_ 2566834761 ProtLamp_18FECA49 5000;
BA_ "SPN" SG_ 2566834761 ProtLamp_18FECA49 987;
BA_ "SigType" SG_ 2566834761 ProtLamp_18FECA49 4;
BA_ "CI_ParId" SG_ 2566834762 ProtLamp_18FECA4A "987";
BA_ "CI_SigId" SG_ 2566834762 ProtLamp_18FECA4A 5559;
BA_ "CI_SigName" SG_ 2566834762 ProtLamp_18FECA4A "Protect Lamp";
BA_ "GenSigSendType" SG_ 2566834762 ProtLamp_18FECA4A 3;
BA_ "GenSigTimeoutTime_FMS4" SG_ 2566834762 ProtLamp_18FECA4A 5000;
BA_ "GenSigTimeoutTime_MulticII" SG_ 2566834762 ProtLamp_18FECA4A 5000;
BA_ "GenSigTimeoutTime_MulticS" SG_ 2566834762 ProtLamp_18FECA4A 5000;
BA_ "GenSigTimeoutTime_MulticS_" SG_ 2566834762 ProtLamp_18FECA4A 5000;
BA_ "GenSigTimeoutTime_MulticS__" SG_ 2566834762 ProtLamp_18FECA4A 5000;
BA_ "GenSigTimeoutTime_SGW_" SG_ 2566834762 ProtLamp_18FECA4A 5000;
BA_ "SPN" SG_ 2566834762 ProtLamp_18FECA4A 987;
BA_ "SigType" SG_ 2566834762 ProtLamp_18FECA4A 4;
BA_ "CI_ParId" SG_ 2566834778 ProtLamp_18FECA5A "987";
BA_ "CI_SigId" SG_ 2566834778 ProtLamp_18FECA5A 5739;
BA_ "CI_SigName" SG_ 2566834778 ProtLamp_18FECA5A "Protect Lamp";
BA_ "GenSigSendType" SG_ 2566834778 ProtLamp_18FECA5A 3;
BA_ "GenSigTimeoutTime_FMS4" SG_ 2566834778 ProtLamp_18FECA5A 5000;
BA_ "GenSigTimeoutTime_MulticS_" SG_ 2566834778 ProtLamp_18FECA5A 5000;
BA_ "GenSigTimeoutTime_PCM" SG_ 2566834778 ProtLamp_18FECA5A 5000;
BA_ "GenSigTimeoutTime_SGW__" SG_ 2566834778 ProtLamp_18FECA5A 5000;
BA_ "GenSigTimeoutTime_VCU" SG_ 2566834778 ProtLamp_18FECA5A 5000;
BA_ "SPN" SG_ 2566834778 ProtLamp_18FECA5A 987;
BA_ "SigType" SG_ 2566834778 ProtLamp_18FECA5A 4;
BA_ "CI_ParId" SG_ 2566834782 ProtLamp_18FECA5E "987";
BA_ "CI_SigId" SG_ 2566834782 ProtLamp_18FECA5E 14755;
BA_ "CI_SigName" SG_ 2566834782 ProtLamp_18FECA5E "Protect Lamp";
BA_ "GenSigSendType" SG_ 2566834782 ProtLamp_18FECA5E 3;
BA_ "GenSigTimeoutTime_PCM" SG_ 2566834782 ProtLamp_18FECA5E 5000;
BA_ "GenSigTimeoutTime_SGW__" SG_ 2566834782 ProtLamp_18FECA5E 5000;
BA_ "SPN" SG_ 2566834782 ProtLamp_18FECA5E 987;
BA_ "SigType" SG_ 2566834782 ProtLamp_18FECA5E 4;
BA_ "CI_ParId" SG_ 2566834814 ProtLamp_18FECA7E "987";
BA_ "CI_SigId" SG_ 2566834814 ProtLamp_18FECA7E 5904;
BA_ "CI_SigName" SG_ 2566834814 ProtLamp_18FECA7E "Protect Lamp";
BA_ "GenSigSendType" SG_ 2566834814 ProtLamp_18FECA7E 3;
BA_ "GenSigTimeoutTime_PCM" SG_ 2566834814 ProtLamp_18FECA7E 5000;
BA_ "GenSigTimeoutTime_SGW__" SG_ 2566834814 ProtLamp_18FECA7E 5000;
BA_ "SPN" SG_ 2566834814 ProtLamp_18FECA7E 987;
BA_ "SigType" SG_ 2566834814 ProtLamp_18FECA7E 4;
BA_ "CI_ParId" SG_ 2566834832 ProtLamp_18FECA90 "987";
BA_ "CI_SigId" SG_ 2566834832 ProtLamp_18FECA90 6069;
BA_ "CI_SigName" SG_ 2566834832 ProtLamp_18FECA90 "Protect Lamp";
BA_ "GenSigSendType" SG_ 2566834832 ProtLamp_18FECA90 3;
BA_ "GenSigTimeoutTime_MulticS" SG_ 2566834832 ProtLamp_18FECA90 5000;
BA_ "GenSigTimeoutTime_MulticS_" SG_ 2566834832 ProtLamp_18FECA90 5000;
BA_ "GenSigTimeoutTime_MulticS__" SG_ 2566834832 ProtLamp_18FECA90 5000;
BA_ "GenSigTimeoutTime_PCM" SG_ 2566834832 ProtLamp_18FECA90 5000;
BA_ "GenSigTimeoutTime_SGW__" SG_ 2566834832 ProtLamp_18FECA90 5000;
BA_ "SPN" SG_ 2566834832 ProtLamp_18FECA90 987;
BA_ "SigType" SG_ 2566834832 ProtLamp_18FECA90 4;
BA_ "CI_ParId" SG_ 2566834833 ProtLamp_18FECA91 "987";
BA_ "CI_SigId" SG_ 2566834833 ProtLamp_18FECA91 6124;
BA_ "CI_SigName" SG_ 2566834833 ProtLamp_18FECA91 "Protect Lamp";
BA_ "GenSigSendType" SG_ 2566834833 ProtLamp_18FECA91 3;
BA_ "GenSigTimeoutTime_MulticS" SG_ 2566834833 ProtLamp_18FECA91 5000;
BA_ "GenSigTimeoutTime_MulticS_" SG_ 2566834833 ProtLamp_18FECA91 5000;
BA_ "GenSigTimeoutTime_MulticS__" SG_ 2566834833 ProtLamp_18FECA91 5000;
BA_ "GenSigTimeoutTime_PCM" SG_ 2566834833 ProtLamp_18FECA91 5000;
BA_ "GenSigTimeoutTime_SGW__" SG_ 2566834833 ProtLamp_18FECA91 5000;
BA_ "SPN" SG_ 2566834833 ProtLamp_18FECA91 987;
BA_ "SigType" SG_ 2566834833 ProtLamp_18FECA91 4;
BA_ "CI_ParId" SG_ 2566834834 ProtLamp_18FECA92 "987";
BA_ "CI_SigId" SG_ 2566834834 ProtLamp_18FECA92 6179;
BA_ "CI_SigName" SG_ 2566834834 ProtLamp_18FECA92 "Protect Lamp";
BA_ "GenSigSendType" SG_ 2566834834 ProtLamp_18FECA92 3;
BA_ "GenSigTimeoutTime_MulticS" SG_ 2566834834 ProtLamp_18FECA92 5000;
BA_ "GenSigTimeoutTime_MulticS_" SG_ 2566834834 ProtLamp_18FECA92 5000;
BA_ "GenSigTimeoutTime_MulticS__" SG_ 2566834834 ProtLamp_18FECA92 5000;
BA_ "GenSigTimeoutTime_PCM" SG_ 2566834834 ProtLamp_18FECA92 5000;
BA_ "GenSigTimeoutTime_SGW__" SG_ 2566834834 ProtLamp_18FECA92 5000;
BA_ "SPN" SG_ 2566834834 ProtLamp_18FECA92 987;
BA_ "SigType" SG_ 2566834834 ProtLamp_18FECA92 4;
BA_ "CI_ParId" SG_ 2566834844 ProtLamp_18FECA9C "987";
BA_ "CI_SigId" SG_ 2566834844 ProtLamp_18FECA9C 6234;
BA_ "CI_SigName" SG_ 2566834844 ProtLamp_18FECA9C "Protect Lamp";
BA_ "GenSigSendType" SG_ 2566834844 ProtLamp_18FECA9C 3;
BA_ "GenSigTimeoutTime_MulticS" SG_ 2566834844 ProtLamp_18FECA9C 5000;
BA_ "GenSigTimeoutTime_MulticS_" SG_ 2566834844 ProtLamp_18FECA9C 5000;
BA_ "GenSigTimeoutTime_MulticS__" SG_ 2566834844 ProtLamp_18FECA9C 5000;
BA_ "GenSigTimeoutTime_PCM" SG_ 2566834844 ProtLamp_18FECA9C 5000;
BA_ "GenSigTimeoutTime_SGW__" SG_ 2566834844 ProtLamp_18FECA9C 5000;
BA_ "SPN" SG_ 2566834844 ProtLamp_18FECA9C 987;
BA_ "SigType" SG_ 2566834844 ProtLamp_18FECA9C 4;
BA_ "CI_ParId" SG_ 2566834846 ProtLamp_18FECA9E "987";
BA_ "CI_SigId" SG_ 2566834846 ProtLamp_18FECA9E 5959;
BA_ "CI_SigName" SG_ 2566834846 ProtLamp_18FECA9E "Protect Lamp";
BA_ "GenSigSendType" SG_ 2566834846 ProtLamp_18FECA9E 3;
BA_ "GenSigTimeoutTime_MulticS" SG_ 2566834846 ProtLamp_18FECA9E 5000;
BA_ "GenSigTimeoutTime_MulticS_" SG_ 2566834846 ProtLamp_18FECA9E 5000;
BA_ "GenSigTimeoutTime_MulticS__" SG_ 2566834846 ProtLamp_18FECA9E 5000;
BA_ "GenSigTimeoutTime_PCM" SG_ 2566834846 ProtLamp_18FECA9E 5000;
BA_ "GenSigTimeoutTime_SGW__" SG_ 2566834846 ProtLamp_18FECA9E 5000;
BA_ "SPN" SG_ 2566834846 ProtLamp_18FECA9E 987;
BA_ "SigType" SG_ 2566834846 ProtLamp_18FECA9E 4;
BA_ "CI_ParId" SG_ 2566834848 ProtLamp_18FECAA0 "987";
BA_ "CI_SigId" SG_ 2566834848 ProtLamp_18FECAA0 6289;
BA_ "CI_SigName" SG_ 2566834848 ProtLamp_18FECAA0 "Protect Lamp";
BA_ "GenSigSendType" SG_ 2566834848 ProtLamp_18FECAA0 3;
BA_ "GenSigTimeoutTime_FMS4" SG_ 2566834848 ProtLamp_18FECAA0 5000;
BA_ "GenSigTimeoutTime_MulticS" SG_ 2566834848 ProtLamp_18FECAA0 5000;
BA_ "GenSigTimeoutTime_MulticS_" SG_ 2566834848 ProtLamp_18FECAA0 5000;
BA_ "GenSigTimeoutTime_MulticS__" SG_ 2566834848 ProtLamp_18FECAA0 5000;
BA_ "GenSigTimeoutTime_PCM" SG_ 2566834848 ProtLamp_18FECAA0 5000;
BA_ "GenSigTimeoutTime_SGW__" SG_ 2566834848 ProtLamp_18FECAA0 5000;
BA_ "SPN" SG_ 2566834848 ProtLamp_18FECAA0 987;
BA_ "SigType" SG_ 2566834848 ProtLamp_18FECAA0 4;
BA_ "CI_ParId" SG_ 2566834882 ProtLamp_18FECAC2 "987";
BA_ "CI_SigId" SG_ 2566834882 ProtLamp_18FECAC2 17881;
BA_ "CI_SigName" SG_ 2566834882 ProtLamp_18FECAC2 "Protect Lamp";
BA_ "SPN" SG_ 2566834882 ProtLamp_18FECAC2 987;
BA_ "SigType" SG_ 2566834882 ProtLamp_18FECAC2 4;
BA_ "CI_ParId" SG_ 2566834920 ProtLamp_18FECAE8 "987";
BA_ "CI_SigId" SG_ 2566834920 ProtLamp_18FECAE8 6014;
BA_ "CI_SigName" SG_ 2566834920 ProtLamp_18FECAE8 "Protect Lamp";
BA_ "GenSigSendType" SG_ 2566834920 ProtLamp_18FECAE8 3;
BA_ "GenSigTimeoutTime_MulticS" SG_ 2566834920 ProtLamp_18FECAE8 5000;
BA_ "GenSigTimeoutTime_MulticS_" SG_ 2566834920 ProtLamp_18FECAE8 5000;
BA_ "GenSigTimeoutTime_MulticS__" SG_ 2566834920 ProtLamp_18FECAE8 5000;
BA_ "GenSigTimeoutTime_PCM" SG_ 2566834920 ProtLamp_18FECAE8 5000;
BA_ "GenSigTimeoutTime_SGW__" SG_ 2566834920 ProtLamp_18FECAE8 5000;
BA_ "SPN" SG_ 2566834920 ProtLamp_18FECAE8 987;
BA_ "SigType" SG_ 2566834920 ProtLamp_18FECAE8 4;
BA_ "CI_ParId" SG_ 2566834926 ProtLamp_18FECAEE "987";
BA_ "CI_SigId" SG_ 2566834926 ProtLamp_18FECAEE 6354;
BA_ "CI_SigName" SG_ 2566834926 ProtLamp_18FECAEE "Protect Lamp";
BA_ "GenSigSendType" SG_ 2566834926 ProtLamp_18FECAEE 3;
BA_ "GenSigTimeoutTime_FMS4" SG_ 2566834926 ProtLamp_18FECAEE 5000;
BA_ "GenSigTimeoutTime_MulticS" SG_ 2566834926 ProtLamp_18FECAEE 5000;
BA_ "GenSigTimeoutTime_MulticS_" SG_ 2566834926 ProtLamp_18FECAEE 5000;
BA_ "GenSigTimeoutTime_PCM" SG_ 2566834926 ProtLamp_18FECAEE 5000;
BA_ "SPN" SG_ 2566834926 ProtLamp_18FECAEE 987;
BA_ "SigType" SG_ 2566834926 ProtLamp_18FECAEE 4;
BA_ "CI_ParId" SG_ 2566834931 ProtLamp_18FECAF3 "987";
BA_ "CI_SigId" SG_ 2566834931 ProtLamp_18FECAF3 6409;
BA_ "CI_SigName" SG_ 2566834931 ProtLamp_18FECAF3 "Protect Lamp";
BA_ "GenSigSendType" SG_ 2566834931 ProtLamp_18FECAF3 3;
BA_ "GenSigTimeoutTime_FMS4" SG_ 2566834931 ProtLamp_18FECAF3 5000;
BA_ "GenSigTimeoutTime_MulticII" SG_ 2566834931 ProtLamp_18FECAF3 5000;
BA_ "GenSigTimeoutTime_MulticS_" SG_ 2566834931 ProtLamp_18FECAF3 5000;
BA_ "GenSigTimeoutTime_PCM" SG_ 2566834931 ProtLamp_18FECAF3 5000;
BA_ "GenSigTimeoutTime_SGW__" SG_ 2566834931 ProtLamp_18FECAF3 5000;
BA_ "SPN" SG_ 2566834931 ProtLamp_18FECAF3 987;
BA_ "SigType" SG_ 2566834931 ProtLamp_18FECAF3 4;
BA_ "CI_ParId" SG_ 2566834972 ProtLamp_18FECB1C "987";
BA_ "CI_SigId" SG_ 2566834972 ProtLamp_18FECB1C 6798;
BA_ "CI_SigName" SG_ 2566834972 ProtLamp_18FECB1C "Protect Lamp";
BA_ "SPN" SG_ 2566834972 ProtLamp_18FECB1C 987;
BA_ "SigType" SG_ 2566834972 ProtLamp_18FECB1C 4;
BA_ "CI_ParId" SG_ 2566834973 ProtLamp_18FECB1D "987";
BA_ "CI_SigId" SG_ 2566834973 ProtLamp_18FECB1D 6967;
BA_ "CI_SigName" SG_ 2566834973 ProtLamp_18FECB1D "Protect Lamp";
BA_ "SPN" SG_ 2566834973 ProtLamp_18FECB1D 987;
BA_ "SigType" SG_ 2566834973 ProtLamp_18FECB1D 4;
BA_ "CI_ParId" SG_ 2566835102 ProtLamp_18FECB9E "987";
BA_ "CI_SigId" SG_ 2566835102 ProtLamp_18FECB9E 7242;
BA_ "CI_SigName" SG_ 2566835102 ProtLamp_18FECB9E "Protect Lamp";
BA_ "SPN" SG_ 2566835102 ProtLamp_18FECB9E 987;
BA_ "SigType" SG_ 2566835102 ProtLamp_18FECB9E 4;
BA_ "CI_ParId" SG_ 2566835485 FfLen1 "1217";
BA_ "CI_SigId" SG_ 2566835485 FfLen1 8595;
BA_ "CI_SigName" SG_ 2566835485 FfLen1 "Freeze Frame Length 1";
BA_ "SPN" SG_ 2566835485 FfLen1 1217;
BA_ "SigType" SG_ 2566835485 FfLen1 1;
BA_ "CI_ParId" SG_ 2566835614 FfLen1_18FECD9E "1217";
BA_ "CI_SigId" SG_ 2566835614 FfLen1_18FECD9E 9198;
BA_ "CI_SigName" SG_ 2566835614 FfLen1_18FECD9E "Freeze Frame Length 1";
BA_ "SPN" SG_ 2566835614 FfLen1_18FECD9E 1217;
BA_ "SigType" SG_ 2566835614 FfLen1_18FECD9E 1;
BA_ "CI_ParId" SG_ 2633943642 ProtLamp_1CFECA5A "987";
BA_ "CI_SigId" SG_ 2633943642 ProtLamp_1CFECA5A 5614;
BA_ "CI_SigName" SG_ 2633943642 ProtLamp_1CFECA5A "Protect Lamp";
BA_ "GenSigSendType" SG_ 2633943642 ProtLamp_1CFECA5A 3;
BA_ "GenSigTimeoutTime_MulticII" SG_ 2633943642 ProtLamp_1CFECA5A 5000;
BA_ "GenSigTimeoutTime_MulticS_" SG_ 2633943642 ProtLamp_1CFECA5A 5000;
BA_ "GenSigTimeoutTime_PCM" SG_ 2633943642 ProtLamp_1CFECA5A 5000;
BA_ "GenSigTimeoutTime_SGW__" SG_ 2633943642 ProtLamp_1CFECA5A 5000;
BA_ "SPN" SG_ 2633943642 ProtLamp_1CFECA5A 987;
BA_ "SigType" SG_ 2633943642 ProtLamp_1CFECA5A 4;
BA_ "CI_ParId" SG_ 2633943680 ProtLamp_1CFECA80 "987";
BA_ "CI_SigId" SG_ 2633943680 ProtLamp_1CFECA80 5669;
BA_ "CI_SigName" SG_ 2633943680 ProtLamp_1CFECA80 "Protect Lamp";
BA_ "GenSigSendType" SG_ 2633943680 ProtLamp_1CFECA80 3;
BA_ "GenSigTimeoutTime_FMS4" SG_ 2633943680 ProtLamp_1CFECA80 5000;
BA_ "GenSigTimeoutTime_MulticS_" SG_ 2633943680 ProtLamp_1CFECA80 5000;
BA_ "GenSigTimeoutTime_PCM" SG_ 2633943680 ProtLamp_1CFECA80 5000;
BA_ "GenSigTimeoutTime_SGW__" SG_ 2633943680 ProtLamp_1CFECA80 5000;
BA_ "SPN" SG_ 2633943680 ProtLamp_1CFECA80 987;
BA_ "SigType" SG_ 2633943680 ProtLamp_1CFECA80 4;
BA_ "CI_ParId" SG_ 2566856773 DoorId "IB488";
BA_ "CI_SigId" SG_ 2566856773 DoorId 3365;
BA_ "CI_SigName" SG_ 2566856773 DoorId "Door ID";
BA_ "GenSigTimeoutTime_PCM" SG_ 2566856773 DoorId 5000;
BA_ "GenSigTimeoutTime_SGW__" SG_ 2566856773 DoorId 5000;
BA_ "CI_ParId" SG_ 2566856773 DoorCnt0 "IB489";
BA_ "CI_SigId" SG_ 2566856773 DoorCnt0 3366;
BA_ "CI_SigName" SG_ 2566856773 DoorCnt0 "Door Counter 0";
BA_ "GenSigTimeoutTime_PCM" SG_ 2566856773 DoorCnt0 5000;
BA_ "GenSigTimeoutTime_SGW__" SG_ 2566856773 DoorCnt0 5000;
BA_ "CI_ParId" SG_ 2566856773 DoorCnt1 "IB490";
BA_ "CI_SigId" SG_ 2566856773 DoorCnt1 3367;
BA_ "CI_SigName" SG_ 2566856773 DoorCnt1 "Door Counter 1";
BA_ "GenSigTimeoutTime_PCM" SG_ 2566856773 DoorCnt1 5000;
BA_ "GenSigTimeoutTime_SGW__" SG_ 2566856773 DoorCnt1 5000;
BA_ "CI_ParId" SG_ 2566856773 DoorCnt2 "IB491";
BA_ "CI_SigId" SG_ 2566856773 DoorCnt2 3368;
BA_ "CI_SigName" SG_ 2566856773 DoorCnt2 "Door Counter 2";
BA_ "GenSigTimeoutTime_PCM" SG_ 2566856773 DoorCnt2 5000;
BA_ "GenSigTimeoutTime_SGW__" SG_ 2566856773 DoorCnt2 5000;
BA_ "CI_ParId" SG_ 2566856773 DoorCnt3 "IB492";
BA_ "CI_SigId" SG_ 2566856773 DoorCnt3 3369;
BA_ "CI_SigName" SG_ 2566856773 DoorCnt3 "Door Counter 3";
BA_ "GenSigTimeoutTime_PCM" SG_ 2566856773 DoorCnt3 5000;
BA_ "GenSigTimeoutTime_SGW__" SG_ 2566856773 DoorCnt3 5000;
BA_ "CI_ParId" SG_ 2566856773 DoorCnt4 "IB493";
BA_ "CI_SigId" SG_ 2566856773 DoorCnt4 3370;
BA_ "CI_SigName" SG_ 2566856773 DoorCnt4 "Door Counter 4";
BA_ "GenSigTimeoutTime_PCM" SG_ 2566856773 DoorCnt4 5000;
BA_ "GenSigTimeoutTime_SGW__" SG_ 2566856773 DoorCnt4 5000;
BA_ "CI_ParId" SG_ 2566856773 DoorClosTime0 "IB494";
BA_ "CI_SigId" SG_ 2566856773 DoorClosTime0 3371;
BA_ "CI_SigName" SG_ 2566856773 DoorClosTime0 "Door Closing Time 0";
BA_ "GenSigTimeoutTime_PCM" SG_ 2566856773 DoorClosTime0 5000;
BA_ "GenSigTimeoutTime_SGW__" SG_ 2566856773 DoorClosTime0 5000;
BA_ "SigType" SG_ 2566856773 DoorClosTime0 1;
BA_ "CI_ParId" SG_ 2566856773 DoorClosTime1 "IB495";
BA_ "CI_SigId" SG_ 2566856773 DoorClosTime1 3372;
BA_ "CI_SigName" SG_ 2566856773 DoorClosTime1 "Door Closing Time 1";
BA_ "GenSigTimeoutTime_PCM" SG_ 2566856773 DoorClosTime1 5000;
BA_ "GenSigTimeoutTime_SGW__" SG_ 2566856773 DoorClosTime1 5000;
BA_ "SigType" SG_ 2566856773 DoorClosTime1 1;
BA_ "CI_ParId" SG_ 2566856773 DoorClosTime2 "IB496";
BA_ "CI_SigId" SG_ 2566856773 DoorClosTime2 3373;
BA_ "CI_SigName" SG_ 2566856773 DoorClosTime2 "Door Closing Time 2";
BA_ "GenSigTimeoutTime_PCM" SG_ 2566856773 DoorClosTime2 5000;
BA_ "GenSigTimeoutTime_SGW__" SG_ 2566856773 DoorClosTime2 5000;
BA_ "SigType" SG_ 2566856773 DoorClosTime2 1;
BA_ "CI_ParId" SG_ 2566856773 DoorClosTime3 "IB497";
BA_ "CI_SigId" SG_ 2566856773 DoorClosTime3 3374;
BA_ "CI_SigName" SG_ 2566856773 DoorClosTime3 "Door Closing Time 3";
BA_ "GenSigTimeoutTime_PCM" SG_ 2566856773 DoorClosTime3 5000;
BA_ "GenSigTimeoutTime_SGW__" SG_ 2566856773 DoorClosTime3 5000;
BA_ "SigType" SG_ 2566856773 DoorClosTime3 1;
BA_ "CI_ParId" SG_ 2566856773 DoorClosTime4 "IB498";
BA_ "CI_SigId" SG_ 2566856773 DoorClosTime4 3375;
BA_ "CI_SigName" SG_ 2566856773 DoorClosTime4 "Door Closing Time 4";
BA_ "GenSigTimeoutTime_PCM" SG_ 2566856773 DoorClosTime4 5000;
BA_ "GenSigTimeoutTime_SGW__" SG_ 2566856773 DoorClosTime4 5000;
BA_ "SigType" SG_ 2566856773 DoorClosTime4 1;
BA_ "CI_ParId" SG_ 2566749184 DpfLampCmd "3697";
BA_ "CI_SigId" SG_ 2566749184 DpfLampCmd 1216;
BA_ "CI_SigName" SG_ 2566749184 DpfLampCmd "Diesel Particulate Filter Lamp Command";
BA_ "GenSigTimeoutTime_MulticS" SG_ 2566749184 DpfLampCmd 5000;
BA_ "GenSigTimeoutTime_NBM" SG_ 2566749184 DpfLampCmd 5000;
BA_ "GenSigTimeoutTime_NBM___" SG_ 2566749184 DpfLampCmd 5000;
BA_ "GenSigTimeoutTime_PCM" SG_ 2566749184 DpfLampCmd 5000;
BA_ "GenSigTimeoutTime_SGW__" SG_ 2566749184 DpfLampCmd 5000;
BA_ "GenSigTimeoutTime_VCM_" SG_ 2566749184 DpfLampCmd 5000;
BA_ "SPN" SG_ 2566749184 DpfLampCmd 3697;
BA_ "CI_ParId" SG_ 2566749184 AtDpfPregenSts "3699";
BA_ "CI_SigId" SG_ 2566749184 AtDpfPregenSts 1217;
BA_ "CI_SigName" SG_ 2566749184 AtDpfPregenSts "Aftertreatment Diesel Particulate Filter Passive Regeneration Status";
BA_ "GenSigTimeoutTime_NBM" SG_ 2566749184 AtDpfPregenSts 5000;
BA_ "GenSigTimeoutTime_NBM___" SG_ 2566749184 AtDpfPregenSts 5000;
BA_ "GenSigTimeoutTime_PCM" SG_ 2566749184 AtDpfPregenSts 5000;
BA_ "GenSigTimeoutTime_SGW__" SG_ 2566749184 AtDpfPregenSts 5000;
BA_ "GenSigTimeoutTime_VCM_" SG_ 2566749184 AtDpfPregenSts 5000;
BA_ "SPN" SG_ 2566749184 AtDpfPregenSts 3699;
BA_ "SigType" SG_ 2566749184 AtDpfPregenSts 4;
BA_ "CI_ParId" SG_ 2566749184 AtDpfAregenSts "3700";
BA_ "CI_SigId" SG_ 2566749184 AtDpfAregenSts 1218;
BA_ "CI_SigName" SG_ 2566749184 AtDpfAregenSts "Aftertreatment Diesel Particulate Filter Active Regeneration Status";
BA_ "GenSigTimeoutTime_NBM" SG_ 2566749184 AtDpfAregenSts 5000;
BA_ "GenSigTimeoutTime_NBM___" SG_ 2566749184 AtDpfAregenSts 5000;
BA_ "GenSigTimeoutTime_PCM" SG_ 2566749184 AtDpfAregenSts 5000;
BA_ "GenSigTimeoutTime_SGW__" SG_ 2566749184 AtDpfAregenSts 5000;
BA_ "GenSigTimeoutTime_VCM_" SG_ 2566749184 AtDpfAregenSts 5000;
BA_ "SPN" SG_ 2566749184 AtDpfAregenSts 3700;
BA_ "SigType" SG_ 2566749184 AtDpfAregenSts 4;
BA_ "CI_ParId" SG_ 2566749184 AtDpfSts "3701";
BA_ "CI_SigId" SG_ 2566749184 AtDpfSts 1219;
BA_ "CI_SigName" SG_ 2566749184 AtDpfSts "Aftertreatment Diesel Particulate Filter Status";
BA_ "GenSigTimeoutTime_PCM" SG_ 2566749184 AtDpfSts 5000;
BA_ "GenSigTimeoutTime_SGW__" SG_ 2566749184 AtDpfSts 5000;
BA_ "GenSigTimeoutTime_VCM_" SG_ 2566749184 AtDpfSts 5000;
BA_ "SPN" SG_ 2566749184 AtDpfSts 3701;
BA_ "CI_ParId" SG_ 2566749184 DpfAregenInhSts "3702";
BA_ "CI_SigId" SG_ 2566749184 DpfAregenInhSts 1220;
BA_ "CI_SigName" SG_ 2566749184 DpfAregenInhSts "Diesel Particulate Filter Active Regeneration Inhibited Status";
BA_ "GenSigTimeoutTime_PCM" SG_ 2566749184 DpfAregenInhSts 5000;
BA_ "GenSigTimeoutTime_SGW__" SG_ 2566749184 DpfAregenInhSts 5000;
BA_ "GenSigTimeoutTime_VCM_" SG_ 2566749184 DpfAregenInhSts 5000;
BA_ "SPN" SG_ 2566749184 DpfAregenInhSts 3702;
BA_ "SigType" SG_ 2566749184 DpfAregenInhSts 4;
BA_ "CI_ParId" SG_ 2561126730 ScoreAcc "IB1613";
BA_ "CI_SigId" SG_ 2561126730 ScoreAcc 14225;
BA_ "CI_SigName" SG_ 2561126730 ScoreAcc "ScoreAcc";
BA_ "GenSigTimeoutTime_SGW_" SG_ 2561126730 ScoreAcc 5000;
BA_ "CI_ParId" SG_ 2561126730 ValidAcc "IB1614";
BA_ "CI_SigId" SG_ 2561126730 ValidAcc 14226;
BA_ "CI_SigName" SG_ 2561126730 ValidAcc "ValidAcc";
BA_ "GenSigTimeoutTime_SGW_" SG_ 2561126730 ValidAcc 5000;
BA_ "SigType" SG_ 2561126730 ValidAcc 4;
BA_ "CI_ParId" SG_ 2561126730 TrendAcc "IB1615";
BA_ "CI_SigId" SG_ 2561126730 TrendAcc 14227;
BA_ "CI_SigName" SG_ 2561126730 TrendAcc "TrendAcc";
BA_ "GenSigTimeoutTime_SGW_" SG_ 2561126730 TrendAcc 5000;
BA_ "CI_ParId" SG_ 2561126730 BenefitAcc "IB1616";
BA_ "CI_SigId" SG_ 2561126730 BenefitAcc 14228;
BA_ "CI_SigName" SG_ 2561126730 BenefitAcc "BenefitAcc";
BA_ "GenSigTimeoutTime_SGW_" SG_ 2561126730 BenefitAcc 5000;
BA_ "SigType" SG_ 2561126730 BenefitAcc 4;
BA_ "CI_ParId" SG_ 2561126730 WeightAcc "IB1617";
BA_ "CI_SigId" SG_ 2561126730 WeightAcc 14229;
BA_ "CI_SigName" SG_ 2561126730 WeightAcc "WeightAcc";
BA_ "GenSigTimeoutTime_SGW_" SG_ 2561126730 WeightAcc 5000;
BA_ "CI_ParId" SG_ 2561126986 EvaluatedSamplesAcc "IB1618";
BA_ "CI_SigId" SG_ 2561126986 EvaluatedSamplesAcc 14231;
BA_ "CI_SigName" SG_ 2561126986 EvaluatedSamplesAcc "EvaluatedSamplesAcc";
BA_ "GenSigTimeoutTime_SGW_" SG_ 2561126986 EvaluatedSamplesAcc 5000;
BA_ "CI_ParId" SG_ 2561126986 EventAcc "IB1619";
BA_ "CI_SigId" SG_ 2561126986 EventAcc 14232;
BA_ "CI_SigName" SG_ 2561126986 EventAcc "EventAcc";
BA_ "GenSigTimeoutTime_SGW_" SG_ 2561126986 EventAcc 5000;
BA_ "SigType" SG_ 2561126986 EventAcc 4;
BA_ "CI_ParId" SG_ 2561127242 ScoreAcceleration "IB1620";
BA_ "CI_SigId" SG_ 2561127242 ScoreAcceleration 14234;
BA_ "CI_SigName" SG_ 2561127242 ScoreAcceleration "ScoreAcceleration";
BA_ "GenSigTimeoutTime_SGW_" SG_ 2561127242 ScoreAcceleration 5000;
BA_ "CI_ParId" SG_ 2561127242 ValidAcceleration "IB1621";
BA_ "CI_SigId" SG_ 2561127242 ValidAcceleration 14235;
BA_ "CI_SigName" SG_ 2561127242 ValidAcceleration "ValidAcceleration";
BA_ "GenSigTimeoutTime_SGW_" SG_ 2561127242 ValidAcceleration 5000;
BA_ "SigType" SG_ 2561127242 ValidAcceleration 4;
BA_ "CI_ParId" SG_ 2561127242 TrendAcceleration "IB1622";
BA_ "CI_SigId" SG_ 2561127242 TrendAcceleration 14236;
BA_ "CI_SigName" SG_ 2561127242 TrendAcceleration "TrendAcceleration";
BA_ "GenSigTimeoutTime_SGW_" SG_ 2561127242 TrendAcceleration 5000;
BA_ "CI_ParId" SG_ 2561127242 BenefitAcceleration "IB1623";
BA_ "CI_SigId" SG_ 2561127242 BenefitAcceleration 14237;
BA_ "CI_SigName" SG_ 2561127242 BenefitAcceleration "BenefitAcceleration";
BA_ "GenSigTimeoutTime_SGW_" SG_ 2561127242 BenefitAcceleration 5000;
BA_ "SigType" SG_ 2561127242 BenefitAcceleration 4;
BA_ "CI_ParId" SG_ 2561127242 WeightAcceleration "IB1624";
BA_ "CI_SigId" SG_ 2561127242 WeightAcceleration 14238;
BA_ "CI_SigName" SG_ 2561127242 WeightAcceleration "WeightAcceleration";
BA_ "GenSigTimeoutTime_SGW_" SG_ 2561127242 WeightAcceleration 5000;
BA_ "CI_ParId" SG_ 2561127498 EventAccelerator "IB1625";
BA_ "CI_SigId" SG_ 2561127498 EventAccelerator 14240;
BA_ "CI_SigName" SG_ 2561127498 EventAccelerator "EventAccelerator";
BA_ "GenSigTimeoutTime_SGW_" SG_ 2561127498 EventAccelerator 5000;
BA_ "SigType" SG_ 2561127498 EventAccelerator 4;
BA_ "CI_ParId" SG_ 2561127498 ManeuverCountAcc "IB1626";
BA_ "CI_SigId" SG_ 2561127498 ManeuverCountAcc 14241;
BA_ "CI_SigName" SG_ 2561127498 ManeuverCountAcc "ManeuverCountAcceleration";
BA_ "GenSigTimeoutTime_SGW_" SG_ 2561127498 ManeuverCountAcc 5000;
BA_ "CI_ParId" SG_ 2561127498 LastManeuverScoreAcc "IB1627";
BA_ "CI_SigId" SG_ 2561127498 LastManeuverScoreAcc 14242;
BA_ "CI_SigName" SG_ 2561127498 LastManeuverScoreAcc "LastManeuverScoreAcceleration";
BA_ "GenSigTimeoutTime_SGW_" SG_ 2561127498 LastManeuverScoreAcc 5000;
BA_ "CI_ParId" SG_ 2561127498 DurationAcceleration "IB1628";
BA_ "CI_SigId" SG_ 2561127498 DurationAcceleration 14243;
BA_ "CI_SigName" SG_ 2561127498 DurationAcceleration "DurationAcceleration";
BA_ "GenSigTimeoutTime_SGW_" SG_ 2561127498 DurationAcceleration 5000;
BA_ "CI_ParId" SG_ 2561127498 AvgAccelerator "IB1629";
BA_ "CI_SigId" SG_ 2561127498 AvgAccelerator 14244;
BA_ "CI_SigName" SG_ 2561127498 AvgAccelerator "AvgAccelerator";
BA_ "GenSigTimeoutTime_SGW_" SG_ 2561127498 AvgAccelerator 5000;
BA_ "CI_ParId" SG_ 2561127754 ScoreAebs "IB1630";
BA_ "CI_SigId" SG_ 2561127754 ScoreAebs 14246;
BA_ "CI_SigName" SG_ 2561127754 ScoreAebs "ScoreAebs";
BA_ "GenSigTimeoutTime_SGW_" SG_ 2561127754 ScoreAebs 5000;
BA_ "CI_ParId" SG_ 2561127754 ValidAebs "IB1631";
BA_ "CI_SigId" SG_ 2561127754 ValidAebs 14247;
BA_ "CI_SigName" SG_ 2561127754 ValidAebs "ValidAebs";
BA_ "GenSigTimeoutTime_SGW_" SG_ 2561127754 ValidAebs 5000;
BA_ "SigType" SG_ 2561127754 ValidAebs 4;
BA_ "CI_ParId" SG_ 2561127754 TrendAebs "IB1632";
BA_ "CI_SigId" SG_ 2561127754 TrendAebs 14248;
BA_ "CI_SigName" SG_ 2561127754 TrendAebs "TrendAebs";
BA_ "GenSigTimeoutTime_SGW_" SG_ 2561127754 TrendAebs 5000;
BA_ "CI_ParId" SG_ 2561127754 BenefitAebs "IB1633";
BA_ "CI_SigId" SG_ 2561127754 BenefitAebs 14249;
BA_ "CI_SigName" SG_ 2561127754 BenefitAebs "BenefitAebs";
BA_ "GenSigTimeoutTime_SGW_" SG_ 2561127754 BenefitAebs 5000;
BA_ "SigType" SG_ 2561127754 BenefitAebs 4;
BA_ "CI_ParId" SG_ 2561127754 WeightAebs "IB1634";
BA_ "CI_SigId" SG_ 2561127754 WeightAebs 14250;
BA_ "CI_SigName" SG_ 2561127754 WeightAebs "WeightAebs";
BA_ "GenSigTimeoutTime_SGW_" SG_ 2561127754 WeightAebs 5000;
BA_ "CI_ParId" SG_ 2561128010 EvaluatedSamplesAebs "IB1635";
BA_ "CI_SigId" SG_ 2561128010 EvaluatedSamplesAebs 14252;
BA_ "CI_SigName" SG_ 2561128010 EvaluatedSamplesAebs "EvaluatedSamplesAebs";
BA_ "GenSigTimeoutTime_SGW_" SG_ 2561128010 EvaluatedSamplesAebs 5000;
BA_ "CI_ParId" SG_ 2561128010 EventAebs "IB1636";
BA_ "CI_SigId" SG_ 2561128010 EventAebs 14253;
BA_ "CI_SigName" SG_ 2561128010 EventAebs "EventAebs";
BA_ "GenSigTimeoutTime_SGW_" SG_ 2561128010 EventAebs 5000;
BA_ "SigType" SG_ 2561128010 EventAebs 4;
BA_ "CI_ParId" SG_ 2561128266 ScoreAirC "IB1637";
BA_ "CI_SigId" SG_ 2561128266 ScoreAirC 14255;
BA_ "CI_SigName" SG_ 2561128266 ScoreAirC "ScoreAirC";
BA_ "GenSigTimeoutTime_SGW_" SG_ 2561128266 ScoreAirC 5000;
BA_ "CI_ParId" SG_ 2561128266 ValidAirC "IB1638";
BA_ "CI_SigId" SG_ 2561128266 ValidAirC 14256;
BA_ "CI_SigName" SG_ 2561128266 ValidAirC "ValidAirC";
BA_ "GenSigTimeoutTime_SGW_" SG_ 2561128266 ValidAirC 5000;
BA_ "SigType" SG_ 2561128266 ValidAirC 4;
BA_ "CI_ParId" SG_ 2561128266 TrendAirC "IB1639";
BA_ "CI_SigId" SG_ 2561128266 TrendAirC 14257;
BA_ "CI_SigName" SG_ 2561128266 TrendAirC "TrendAirC";
BA_ "GenSigTimeoutTime_SGW_" SG_ 2561128266 TrendAirC 5000;
BA_ "CI_ParId" SG_ 2561128266 BenefitAirC "IB1640";
BA_ "CI_SigId" SG_ 2561128266 BenefitAirC 14258;
BA_ "CI_SigName" SG_ 2561128266 BenefitAirC "BenefitAirC";
BA_ "GenSigTimeoutTime_SGW_" SG_ 2561128266 BenefitAirC 5000;
BA_ "SigType" SG_ 2561128266 BenefitAirC 4;
BA_ "CI_ParId" SG_ 2561128266 WeightAirC "IB1641";
BA_ "CI_SigId" SG_ 2561128266 WeightAirC 14259;
BA_ "CI_SigName" SG_ 2561128266 WeightAirC "WeightAirC";
BA_ "GenSigTimeoutTime_SGW_" SG_ 2561128266 WeightAirC 5000;
BA_ "CI_ParId" SG_ 2561128522 EvaluatedSamplesAirC "IB1642";
BA_ "CI_SigId" SG_ 2561128522 EvaluatedSamplesAirC 14261;
BA_ "CI_SigName" SG_ 2561128522 EvaluatedSamplesAirC "EvaluatedSamplesAirC";
BA_ "GenSigTimeoutTime_SGW_" SG_ 2561128522 EvaluatedSamplesAirC 5000;
BA_ "CI_ParId" SG_ 2561144138 ScoreAttention "IB1643";
BA_ "CI_SigId" SG_ 2561144138 ScoreAttention 14263;
BA_ "CI_SigName" SG_ 2561144138 ScoreAttention "ScoreAttention";
BA_ "GenSigTimeoutTime_SGW_" SG_ 2561144138 ScoreAttention 5000;
BA_ "CI_ParId" SG_ 2561144138 ValidAttention "IB1644";
BA_ "CI_SigId" SG_ 2561144138 ValidAttention 14264;
BA_ "CI_SigName" SG_ 2561144138 ValidAttention "ValidAttention";
BA_ "GenSigTimeoutTime_SGW_" SG_ 2561144138 ValidAttention 5000;
BA_ "SigType" SG_ 2561144138 ValidAttention 4;
BA_ "CI_ParId" SG_ 2561144138 TrendAttention "IB1645";
BA_ "CI_SigId" SG_ 2561144138 TrendAttention 14265;
BA_ "CI_SigName" SG_ 2561144138 TrendAttention "TrendAttention";
BA_ "GenSigTimeoutTime_SGW_" SG_ 2561144138 TrendAttention 5000;
BA_ "CI_ParId" SG_ 2561144138 BenefitAttention "IB1646";
BA_ "CI_SigId" SG_ 2561144138 BenefitAttention 14266;
BA_ "CI_SigName" SG_ 2561144138 BenefitAttention "BenefitAttention";
BA_ "GenSigTimeoutTime_SGW_" SG_ 2561144138 BenefitAttention 5000;
BA_ "SigType" SG_ 2561144138 BenefitAttention 4;
BA_ "CI_ParId" SG_ 2561144138 WeightAttention "IB1647";
BA_ "CI_SigId" SG_ 2561144138 WeightAttention 14267;
BA_ "CI_SigName" SG_ 2561144138 WeightAttention "WeightAttention";
BA_ "GenSigTimeoutTime_SGW_" SG_ 2561144138 WeightAttention 5000;
BA_ "CI_ParId" SG_ 2561128778 ScoreAuxBrake "IB1648";
BA_ "CI_SigId" SG_ 2561128778 ScoreAuxBrake 14269;
BA_ "CI_SigName" SG_ 2561128778 ScoreAuxBrake "ScoreAuxBrake";
BA_ "GenSigTimeoutTime_SGW_" SG_ 2561128778 ScoreAuxBrake 5000;
BA_ "CI_ParId" SG_ 2561128778 ValidAuxBrake "IB1649";
BA_ "CI_SigId" SG_ 2561128778 ValidAuxBrake 14270;
BA_ "CI_SigName" SG_ 2561128778 ValidAuxBrake "ValidAuxBrake";
BA_ "GenSigTimeoutTime_SGW_" SG_ 2561128778 ValidAuxBrake 5000;
BA_ "SigType" SG_ 2561128778 ValidAuxBrake 4;
BA_ "CI_ParId" SG_ 2561128778 TrendAuxBrake "IB1650";
BA_ "CI_SigId" SG_ 2561128778 TrendAuxBrake 14271;
BA_ "CI_SigName" SG_ 2561128778 TrendAuxBrake "TrendAuxBrake";
BA_ "GenSigTimeoutTime_SGW_" SG_ 2561128778 TrendAuxBrake 5000;
BA_ "CI_ParId" SG_ 2561128778 BenefitAuxBrake "IB1651";
BA_ "CI_SigId" SG_ 2561128778 BenefitAuxBrake 14272;
BA_ "CI_SigName" SG_ 2561128778 BenefitAuxBrake "BenefitAuxBrake";
BA_ "GenSigTimeoutTime_SGW_" SG_ 2561128778 BenefitAuxBrake 5000;
BA_ "SigType" SG_ 2561128778 BenefitAuxBrake 4;
BA_ "CI_ParId" SG_ 2561128778 WeightAuxBrake "IB1652";
BA_ "CI_SigId" SG_ 2561128778 WeightAuxBrake 14273;
BA_ "CI_SigName" SG_ 2561128778 WeightAuxBrake "WeightAuxBrake";
BA_ "GenSigTimeoutTime_SGW_" SG_ 2561128778 WeightAuxBrake 5000;
BA_ "CI_ParId" SG_ 2561129034 LastManeuverScoreAuxBrake "IB1653";
BA_ "CI_SigId" SG_ 2561129034 LastManeuverScoreAuxBrake 14275;
BA_ "CI_SigName" SG_ 2561129034 LastManeuverScoreAuxBrake "LastManeuverScoreAuxBrake";
BA_ "GenSigTimeoutTime_SGW_" SG_ 2561129034 LastManeuverScoreAuxBrake 5000;
BA_ "CI_ParId" SG_ 2561129034 Ratio "IB1654";
BA_ "CI_SigId" SG_ 2561129034 Ratio 14276;
BA_ "CI_SigName" SG_ 2561129034 Ratio "Ratio";
BA_ "GenSigTimeoutTime_SGW_" SG_ 2561129034 Ratio 5000;
BA_ "CI_ParId" SG_ 2561129034 TotalBrakingDistance "IB1655";
BA_ "CI_SigId" SG_ 2561129034 TotalBrakingDistance 14277;
BA_ "CI_SigName" SG_ 2561129034 TotalBrakingDistance "TotalBrakingDistance";
BA_ "GenSigTimeoutTime_SGW_" SG_ 2561129034 TotalBrakingDistance 5000;
BA_ "SigType" SG_ 2561129034 TotalBrakingDistance 1;
BA_ "CI_ParId" SG_ 2561129034 ManeuverDistance "IB1656";
BA_ "CI_SigId" SG_ 2561129034 ManeuverDistance 14278;
BA_ "CI_SigName" SG_ 2561129034 ManeuverDistance "ManeuverDistance";
BA_ "GenSigTimeoutTime_SGW_" SG_ 2561129034 ManeuverDistance 5000;
BA_ "SigType" SG_ 2561129034 ManeuverDistance 1;
BA_ "CI_ParId" SG_ 2561129034 ManeuverServiceBrakeDistance "IB1657";
BA_ "CI_SigId" SG_ 2561129034 ManeuverServiceBrakeDistance 14279;
BA_ "CI_SigName" SG_ 2561129034 ManeuverServiceBrakeDistance "ManeuverServiceBrakeDistance";
BA_ "GenSigTimeoutTime_SGW_" SG_ 2561129034 ManeuverServiceBrakeDistance 5000;
BA_ "SigType" SG_ 2561129034 ManeuverServiceBrakeDistance 1;
BA_ "CI_ParId" SG_ 2561129034 AuxBrakeActive "IB1658";
BA_ "CI_SigId" SG_ 2561129034 AuxBrakeActive 14280;
BA_ "CI_SigName" SG_ 2561129034 AuxBrakeActive "AuxBrakeActive";
BA_ "GenSigTimeoutTime_SGW_" SG_ 2561129034 AuxBrakeActive 5000;
BA_ "CI_ParId" SG_ 2561129034 EventAuxBrake "IB1659";
BA_ "CI_SigId" SG_ 2561129034 EventAuxBrake 14281;
BA_ "CI_SigName" SG_ 2561129034 EventAuxBrake "EventAuxBrake";
BA_ "GenSigTimeoutTime_SGW_" SG_ 2561129034 EventAuxBrake 5000;
BA_ "SigType" SG_ 2561129034 EventAuxBrake 4;
BA_ "CI_ParId" SG_ 2561145930 ScoreBsis "IB1660";
BA_ "CI_SigId" SG_ 2561145930 ScoreBsis 14283;
BA_ "CI_SigName" SG_ 2561145930 ScoreBsis "ScoreBsis";
BA_ "GenSigTimeoutTime_SGW_" SG_ 2561145930 ScoreBsis 5000;
BA_ "CI_ParId" SG_ 2561145930 ValidBsis "IB1661";
BA_ "CI_SigId" SG_ 2561145930 ValidBsis 14284;
BA_ "CI_SigName" SG_ 2561145930 ValidBsis "ValidBsis";
BA_ "GenSigTimeoutTime_SGW_" SG_ 2561145930 ValidBsis 5000;
BA_ "SigType" SG_ 2561145930 ValidBsis 4;
BA_ "CI_ParId" SG_ 2561145930 TrendBsis "IB1662";
BA_ "CI_SigId" SG_ 2561145930 TrendBsis 14285;
BA_ "CI_SigName" SG_ 2561145930 TrendBsis "TrendBsis";
BA_ "GenSigTimeoutTime_SGW_" SG_ 2561145930 TrendBsis 5000;
BA_ "CI_ParId" SG_ 2561145930 BenefitBsis "IB1663";
BA_ "CI_SigId" SG_ 2561145930 BenefitBsis 14286;
BA_ "CI_SigName" SG_ 2561145930 BenefitBsis "BenefitBsis";
BA_ "GenSigTimeoutTime_SGW_" SG_ 2561145930 BenefitBsis 5000;
BA_ "SigType" SG_ 2561145930 BenefitBsis 4;
BA_ "CI_ParId" SG_ 2561145930 WeightBsis "IB1664";
BA_ "CI_SigId" SG_ 2561145930 WeightBsis 14287;
BA_ "CI_SigName" SG_ 2561145930 WeightBsis "WeightBsis";
BA_ "GenSigTimeoutTime_SGW_" SG_ 2561145930 WeightBsis 5000;
BA_ "CI_ParId" SG_ 2561129290 ScoreCare "IB1665";
BA_ "CI_SigId" SG_ 2561129290 ScoreCare 14289;
BA_ "CI_SigName" SG_ 2561129290 ScoreCare "ScoreCare";
BA_ "GenSigTimeoutTime_SGW_" SG_ 2561129290 ScoreCare 5000;
BA_ "CI_ParId" SG_ 2561129290 ValidCare "IB1666";
BA_ "CI_SigId" SG_ 2561129290 ValidCare 14290;
BA_ "CI_SigName" SG_ 2561129290 ValidCare "ValidCare";
BA_ "GenSigTimeoutTime_SGW_" SG_ 2561129290 ValidCare 5000;
BA_ "SigType" SG_ 2561129290 ValidCare 4;
BA_ "CI_ParId" SG_ 2561129290 TrendCare "IB1667";
BA_ "CI_SigId" SG_ 2561129290 TrendCare 14291;
BA_ "CI_SigName" SG_ 2561129290 TrendCare "TrendCare";
BA_ "GenSigTimeoutTime_SGW_" SG_ 2561129290 TrendCare 5000;
BA_ "CI_ParId" SG_ 2561129290 BenefitCare "IB1668";
BA_ "CI_SigId" SG_ 2561129290 BenefitCare 14292;
BA_ "CI_SigName" SG_ 2561129290 BenefitCare "BenefitCare";
BA_ "GenSigTimeoutTime_SGW_" SG_ 2561129290 BenefitCare 5000;
BA_ "SigType" SG_ 2561129290 BenefitCare 4;
BA_ "CI_ParId" SG_ 2561129290 WeightCare "IB1669";
BA_ "CI_SigId" SG_ 2561129290 WeightCare 14293;
BA_ "CI_SigName" SG_ 2561129290 WeightCare "WeightCare";
BA_ "GenSigTimeoutTime_SGW_" SG_ 2561129290 WeightCare 5000;
BA_ "CI_ParId" SG_ 2561129546 ResetEcoA "IB1670";
BA_ "CI_SigId" SG_ 2561129546 ResetEcoA 14295;
BA_ "CI_SigName" SG_ 2561129546 ResetEcoA "ResetEcoA";
BA_ "GenSigTimeoutTime_SGW_" SG_ 2561129546 ResetEcoA 5000;
BA_ "SigType" SG_ 2561129546 ResetEcoA 4;
BA_ "CI_ParId" SG_ 2561129546 ResetEcoB "IB1671";
BA_ "CI_SigId" SG_ 2561129546 ResetEcoB 14296;
BA_ "CI_SigName" SG_ 2561129546 ResetEcoB "ResetEcoB";
BA_ "GenSigTimeoutTime_SGW_" SG_ 2561129546 ResetEcoB 5000;
BA_ "SigType" SG_ 2561129546 ResetEcoB 4;
BA_ "CI_ParId" SG_ 2561130058 ScoreComfort "IB1672";
BA_ "CI_SigId" SG_ 2561130058 ScoreComfort 14298;
BA_ "CI_SigName" SG_ 2561130058 ScoreComfort "ScoreComfort";
BA_ "GenSigTimeoutTime_SGW_" SG_ 2561130058 ScoreComfort 5000;
BA_ "CI_ParId" SG_ 2561130058 ValidComfort "IB1673";
BA_ "CI_SigId" SG_ 2561130058 ValidComfort 14299;
BA_ "CI_SigName" SG_ 2561130058 ValidComfort "ValidComfort";
BA_ "GenSigTimeoutTime_SGW_" SG_ 2561130058 ValidComfort 5000;
BA_ "SigType" SG_ 2561130058 ValidComfort 4;
BA_ "CI_ParId" SG_ 2561130058 TrendComfort "IB1674";
BA_ "CI_SigId" SG_ 2561130058 TrendComfort 14300;
BA_ "CI_SigName" SG_ 2561130058 TrendComfort "TrendComfort";
BA_ "GenSigTimeoutTime_SGW_" SG_ 2561130058 TrendComfort 5000;
BA_ "CI_ParId" SG_ 2561130058 BenefitComfort "IB1675";
BA_ "CI_SigId" SG_ 2561130058 BenefitComfort 14301;
BA_ "CI_SigName" SG_ 2561130058 BenefitComfort "BenefitComfort";
BA_ "GenSigTimeoutTime_SGW_" SG_ 2561130058 BenefitComfort 5000;
BA_ "SigType" SG_ 2561130058 BenefitComfort 4;
BA_ "CI_ParId" SG_ 2561130058 WeightComfort "IB1676";
BA_ "CI_SigId" SG_ 2561130058 WeightComfort 14302;
BA_ "CI_SigName" SG_ 2561130058 WeightComfort "WeightComfort";
BA_ "GenSigTimeoutTime_SGW_" SG_ 2561130058 WeightComfort 5000;
BA_ "CI_ParId" SG_ 2561129802 OdometerTripCurrent "IB1677";
BA_ "CI_SigId" SG_ 2561129802 OdometerTripCurrent 14304;
BA_ "CI_SigName" SG_ 2561129802 OdometerTripCurrent "OdometerTripCurrent";
BA_ "GenSigTimeoutTime_SGW_" SG_ 2561129802 OdometerTripCurrent 5000;
BA_ "SigType" SG_ 2561129802 OdometerTripCurrent 1;
BA_ "CI_ParId" SG_ 2561129802 TimeStampCurrent "IB1678";
BA_ "CI_SigId" SG_ 2561129802 TimeStampCurrent 14305;
BA_ "CI_SigName" SG_ 2561129802 TimeStampCurrent "TimeStampCurrent";
BA_ "GenSigTimeoutTime_SGW_" SG_ 2561129802 TimeStampCurrent 5000;
BA_ "SigType" SG_ 2561129802 TimeStampCurrent 1;
BA_ "CI_ParId" SG_ 2561130314 ScoreDas "IB1679";
BA_ "CI_SigId" SG_ 2561130314 ScoreDas 14307;
BA_ "CI_SigName" SG_ 2561130314 ScoreDas "ScoreDas";
BA_ "GenSigTimeoutTime_SGW_" SG_ 2561130314 ScoreDas 5000;
BA_ "CI_ParId" SG_ 2561130314 ValidDas "IB1680";
BA_ "CI_SigId" SG_ 2561130314 ValidDas 14308;
BA_ "CI_SigName" SG_ 2561130314 ValidDas "ValidDas";
BA_ "GenSigTimeoutTime_SGW_" SG_ 2561130314 ValidDas 5000;
BA_ "SigType" SG_ 2561130314 ValidDas 4;
BA_ "CI_ParId" SG_ 2561130314 TrendDas "IB1681";
BA_ "CI_SigId" SG_ 2561130314 TrendDas 14309;
BA_ "CI_SigName" SG_ 2561130314 TrendDas "TrendDas";
BA_ "GenSigTimeoutTime_SGW_" SG_ 2561130314 TrendDas 5000;
BA_ "CI_ParId" SG_ 2561130314 BenefitDas "IB1682";
BA_ "CI_SigId" SG_ 2561130314 BenefitDas 14310;
BA_ "CI_SigName" SG_ 2561130314 BenefitDas "BenefitDas";
BA_ "GenSigTimeoutTime_SGW_" SG_ 2561130314 BenefitDas 5000;
BA_ "SigType" SG_ 2561130314 BenefitDas 4;
BA_ "CI_ParId" SG_ 2561130314 WeightDas "IB1683";
BA_ "CI_SigId" SG_ 2561130314 WeightDas 14311;
BA_ "CI_SigName" SG_ 2561130314 WeightDas "WeightDas";
BA_ "GenSigTimeoutTime_SGW_" SG_ 2561130314 WeightDas 5000;
BA_ "CI_ParId" SG_ 2561140554 EvaluatedSamplesDas "IB1684";
BA_ "CI_SigId" SG_ 2561140554 EvaluatedSamplesDas 14313;
BA_ "CI_SigName" SG_ 2561140554 EvaluatedSamplesDas "EvaluatedSamplesDas";
BA_ "GenSigTimeoutTime_SGW_" SG_ 2561140554 EvaluatedSamplesDas 5000;
BA_ "CI_ParId" SG_ 2561140554 EventDas "IB1685";
BA_ "CI_SigId" SG_ 2561140554 EventDas 14314;
BA_ "CI_SigName" SG_ 2561140554 EventDas "EventDas";
BA_ "GenSigTimeoutTime_SGW_" SG_ 2561140554 EventDas 5000;
BA_ "SigType" SG_ 2561140554 EventDas 4;
BA_ "CI_ParId" SG_ 2561130570 ScoreDeceleration "IB1686";
BA_ "CI_SigId" SG_ 2561130570 ScoreDeceleration 14316;
BA_ "CI_SigName" SG_ 2561130570 ScoreDeceleration "ScoreDeceleration";
BA_ "GenSigTimeoutTime_SGW_" SG_ 2561130570 ScoreDeceleration 5000;
BA_ "CI_ParId" SG_ 2561130570 ValidDeceleration "IB1687";
BA_ "CI_SigId" SG_ 2561130570 ValidDeceleration 14317;
BA_ "CI_SigName" SG_ 2561130570 ValidDeceleration "ValidDeceleration";
BA_ "GenSigTimeoutTime_SGW_" SG_ 2561130570 ValidDeceleration 5000;
BA_ "SigType" SG_ 2561130570 ValidDeceleration 4;
BA_ "CI_ParId" SG_ 2561130570 TrendDeceleration "IB1688";
BA_ "CI_SigId" SG_ 2561130570 TrendDeceleration 14318;
BA_ "CI_SigName" SG_ 2561130570 TrendDeceleration "TrendDeceleration";
BA_ "GenSigTimeoutTime_SGW_" SG_ 2561130570 TrendDeceleration 5000;
BA_ "CI_ParId" SG_ 2561130570 BenefitDeceleration "IB1689";
BA_ "CI_SigId" SG_ 2561130570 BenefitDeceleration 14319;
BA_ "CI_SigName" SG_ 2561130570 BenefitDeceleration "BenefitDeceleration";
BA_ "GenSigTimeoutTime_SGW_" SG_ 2561130570 BenefitDeceleration 5000;
BA_ "SigType" SG_ 2561130570 BenefitDeceleration 4;
BA_ "CI_ParId" SG_ 2561130570 WeightDeceleration "IB1690";
BA_ "CI_SigId" SG_ 2561130570 WeightDeceleration 14320;
BA_ "CI_SigName" SG_ 2561130570 WeightDeceleration "WeightDeceleration";
BA_ "GenSigTimeoutTime_SGW_" SG_ 2561130570 WeightDeceleration 5000;
BA_ "CI_ParId" SG_ 2561143882 ScoreDriverAwareness "IB1691";
BA_ "CI_SigId" SG_ 2561143882 ScoreDriverAwareness 14322;
BA_ "CI_SigName" SG_ 2561143882 ScoreDriverAwareness "ScoreDriverAwareness";
BA_ "GenSigTimeoutTime_SGW_" SG_ 2561143882 ScoreDriverAwareness 5000;
BA_ "CI_ParId" SG_ 2561143882 ValidDriverAwareness "IB1692";
BA_ "CI_SigId" SG_ 2561143882 ValidDriverAwareness 14323;
BA_ "CI_SigName" SG_ 2561143882 ValidDriverAwareness "ValidDriverAwareness";
BA_ "GenSigTimeoutTime_SGW_" SG_ 2561143882 ValidDriverAwareness 5000;
BA_ "SigType" SG_ 2561143882 ValidDriverAwareness 4;
BA_ "CI_ParId" SG_ 2561143882 TrendDriverAwareness "IB1693";
BA_ "CI_SigId" SG_ 2561143882 TrendDriverAwareness 14324;
BA_ "CI_SigName" SG_ 2561143882 TrendDriverAwareness "TrendDriverAwareness";
BA_ "GenSigTimeoutTime_SGW_" SG_ 2561143882 TrendDriverAwareness 5000;
BA_ "CI_ParId" SG_ 2561143882 BenefitDriverAwareness "IB1694";
BA_ "CI_SigId" SG_ 2561143882 BenefitDriverAwareness 14325;
BA_ "CI_SigName" SG_ 2561143882 BenefitDriverAwareness "BenefitDriverAwareness";
BA_ "GenSigTimeoutTime_SGW_" SG_ 2561143882 BenefitDriverAwareness 5000;
BA_ "SigType" SG_ 2561143882 BenefitDriverAwareness 4;
BA_ "CI_ParId" SG_ 2561143882 WeightDriverAwareness "IB1695";
BA_ "CI_SigId" SG_ 2561143882 WeightDriverAwareness 14326;
BA_ "CI_SigName" SG_ 2561143882 WeightDriverAwareness "WeightDriverAwareness";
BA_ "GenSigTimeoutTime_SGW_" SG_ 2561143882 WeightDriverAwareness 5000;
BA_ "CI_ParId" SG_ 2561130826 ScoreEcoMode "IB1696";
BA_ "CI_SigId" SG_ 2561130826 ScoreEcoMode 14328;
BA_ "CI_SigName" SG_ 2561130826 ScoreEcoMode "ScoreEcoMode";
BA_ "GenSigTimeoutTime_SGW_" SG_ 2561130826 ScoreEcoMode 5000;
BA_ "CI_ParId" SG_ 2561130826 ValidEcoMode "IB1697";
BA_ "CI_SigId" SG_ 2561130826 ValidEcoMode 14329;
BA_ "CI_SigName" SG_ 2561130826 ValidEcoMode "ValidEcoMode";
BA_ "GenSigTimeoutTime_SGW_" SG_ 2561130826 ValidEcoMode 5000;
BA_ "SigType" SG_ 2561130826 ValidEcoMode 4;
BA_ "CI_ParId" SG_ 2561130826 TrendEcoMode "IB1698";
BA_ "CI_SigId" SG_ 2561130826 TrendEcoMode 14330;
BA_ "CI_SigName" SG_ 2561130826 TrendEcoMode "TrendEcoMode";
BA_ "GenSigTimeoutTime_SGW_" SG_ 2561130826 TrendEcoMode 5000;
BA_ "CI_ParId" SG_ 2561130826 BenefitEcoMode "IB1699";
BA_ "CI_SigId" SG_ 2561130826 BenefitEcoMode 14331;
BA_ "CI_SigName" SG_ 2561130826 BenefitEcoMode "BenefitEcoMode";
BA_ "GenSigTimeoutTime_SGW_" SG_ 2561130826 BenefitEcoMode 5000;
BA_ "SigType" SG_ 2561130826 BenefitEcoMode 4;
BA_ "CI_ParId" SG_ 2561130826 WeightEcoMode "IB1700";
BA_ "CI_SigId" SG_ 2561130826 WeightEcoMode 14332;
BA_ "CI_SigName" SG_ 2561130826 WeightEcoMode "WeightEcoMode";
BA_ "GenSigTimeoutTime_SGW_" SG_ 2561130826 WeightEcoMode 5000;
BA_ "CI_ParId" SG_ 2561131082 EvaluatedSamplesEcoMode "IB1701";
BA_ "CI_SigId" SG_ 2561131082 EvaluatedSamplesEcoMode 14334;
BA_ "CI_SigName" SG_ 2561131082 EvaluatedSamplesEcoMode "EvaluatedSamplesEcoMode";
BA_ "GenSigTimeoutTime_SGW_" SG_ 2561131082 EvaluatedSamplesEcoMode 5000;
BA_ "CI_ParId" SG_ 2561131338 ScoreEngineUse "IB1702";
BA_ "CI_SigId" SG_ 2561131338 ScoreEngineUse 14336;
BA_ "CI_SigName" SG_ 2561131338 ScoreEngineUse "ScoreEngineUse";
BA_ "GenSigTimeoutTime_SGW_" SG_ 2561131338 ScoreEngineUse 5000;
BA_ "CI_ParId" SG_ 2561131338 ValidEngineUse "IB1703";
BA_ "CI_SigId" SG_ 2561131338 ValidEngineUse 14337;
BA_ "CI_SigName" SG_ 2561131338 ValidEngineUse "ValidEngineUse";
BA_ "GenSigTimeoutTime_SGW_" SG_ 2561131338 ValidEngineUse 5000;
BA_ "SigType" SG_ 2561131338 ValidEngineUse 4;
BA_ "CI_ParId" SG_ 2561131338 TrendEngineUse "IB1704";
BA_ "CI_SigId" SG_ 2561131338 TrendEngineUse 14338;
BA_ "CI_SigName" SG_ 2561131338 TrendEngineUse "TrendEngineUse";
BA_ "GenSigTimeoutTime_SGW_" SG_ 2561131338 TrendEngineUse 5000;
BA_ "CI_ParId" SG_ 2561131338 BenefitEngineUse "IB1705";
BA_ "CI_SigId" SG_ 2561131338 BenefitEngineUse 14339;
BA_ "CI_SigName" SG_ 2561131338 BenefitEngineUse "BenefitEngineUse";
BA_ "GenSigTimeoutTime_SGW_" SG_ 2561131338 BenefitEngineUse 5000;
BA_ "SigType" SG_ 2561131338 BenefitEngineUse 4;
BA_ "CI_ParId" SG_ 2561131338 WeightEngineUse "IB1706";
BA_ "CI_SigId" SG_ 2561131338 WeightEngineUse 14340;
BA_ "CI_SigName" SG_ 2561131338 WeightEngineUse "WeightEngineUse";
BA_ "GenSigTimeoutTime_SGW_" SG_ 2561131338 WeightEngineUse 5000;
BA_ "CI_ParId" SG_ 2561140810 EvaluatedMetersTrip "IB1707";
BA_ "CI_SigId" SG_ 2561140810 EvaluatedMetersTrip 14342;
BA_ "CI_SigName" SG_ 2561140810 EvaluatedMetersTrip "EvaluatedMetersTrip";
BA_ "GenSigTimeoutTime_SGW_" SG_ 2561140810 EvaluatedMetersTrip 5000;
BA_ "SigType" SG_ 2561140810 EvaluatedMetersTrip 1;
BA_ "CI_ParId" SG_ 2561140810 EvaluatedSamplesTrip "IB1708";
BA_ "CI_SigId" SG_ 2561140810 EvaluatedSamplesTrip 14343;
BA_ "CI_SigName" SG_ 2561140810 EvaluatedSamplesTrip "EvaluatedSamplesTrip";
BA_ "GenSigTimeoutTime_SGW_" SG_ 2561140810 EvaluatedSamplesTrip 5000;
BA_ "CI_ParId" SG_ 2561131594 ScoreFuel "IB791";
BA_ "CI_SigId" SG_ 2561131594 ScoreFuel 1907;
BA_ "CI_SigName" SG_ 2561131594 ScoreFuel "ScoreFuel";
BA_ "GenSigTimeoutTime_MulticII" SG_ 2561131594 ScoreFuel 2500;
BA_ "GenSigTimeoutTime_MulticS" SG_ 2561131594 ScoreFuel 2500;
BA_ "GenSigTimeoutTime_MulticS_" SG_ 2561131594 ScoreFuel 2500;
BA_ "GenSigTimeoutTime_MulticS__" SG_ 2561131594 ScoreFuel 2500;
BA_ "GenSigTimeoutTime_SGW_" SG_ 2561131594 ScoreFuel 2500;
BA_ "CI_ParId" SG_ 2561131594 ValFuel "IB792";
BA_ "CI_SigId" SG_ 2561131594 ValFuel 1908;
BA_ "CI_SigName" SG_ 2561131594 ValFuel "ValidFuel";
BA_ "GenSigTimeoutTime_MulticS" SG_ 2561131594 ValFuel 2500;
BA_ "GenSigTimeoutTime_MulticS_" SG_ 2561131594 ValFuel 2500;
BA_ "GenSigTimeoutTime_MulticS__" SG_ 2561131594 ValFuel 2500;
BA_ "GenSigTimeoutTime_SGW_" SG_ 2561131594 ValFuel 2500;
BA_ "SigType" SG_ 2561131594 ValFuel 4;
BA_ "CI_ParId" SG_ 2561131594 TrendFuel "IB793";
BA_ "CI_SigId" SG_ 2561131594 TrendFuel 1909;
BA_ "CI_SigName" SG_ 2561131594 TrendFuel "TrendFuel";
BA_ "GenSigTimeoutTime_MulticS" SG_ 2561131594 TrendFuel 2500;
BA_ "GenSigTimeoutTime_MulticS_" SG_ 2561131594 TrendFuel 2500;
BA_ "GenSigTimeoutTime_MulticS__" SG_ 2561131594 TrendFuel 2500;
BA_ "GenSigTimeoutTime_SGW_" SG_ 2561131594 TrendFuel 2500;
BA_ "CI_ParId" SG_ 2561131594 BenfFuel "IB794";
BA_ "CI_SigId" SG_ 2561131594 BenfFuel 1910;
BA_ "CI_SigName" SG_ 2561131594 BenfFuel "BenefitFuel";
BA_ "GenSigTimeoutTime_MulticS" SG_ 2561131594 BenfFuel 2500;
BA_ "GenSigTimeoutTime_MulticS_" SG_ 2561131594 BenfFuel 2500;
BA_ "GenSigTimeoutTime_MulticS__" SG_ 2561131594 BenfFuel 2500;
BA_ "GenSigTimeoutTime_SGW_" SG_ 2561131594 BenfFuel 2500;
BA_ "SigType" SG_ 2561131594 BenfFuel 4;
BA_ "CI_ParId" SG_ 2561131594 WtFuel "IB795";
BA_ "CI_SigId" SG_ 2561131594 WtFuel 1911;
BA_ "CI_SigName" SG_ 2561131594 WtFuel "WeightFuel";
BA_ "GenSigTimeoutTime_MulticS" SG_ 2561131594 WtFuel 2500;
BA_ "GenSigTimeoutTime_MulticS_" SG_ 2561131594 WtFuel 2500;
BA_ "GenSigTimeoutTime_MulticS__" SG_ 2561131594 WtFuel 2500;
BA_ "GenSigTimeoutTime_SGW_" SG_ 2561131594 WtFuel 2500;
VAL_ 2566908915 Bms0IEqualizationSts_18FFEBF3 0 "No Balancing" 1 "Balancing Active" ;
VAL_ 2566908915 Bms0IActSts_18FFEBF3 0 "OFF" 1 "Park" 2 "Operational" 3 "Charge" 7 "Invalid" ;
VAL_ 2566908915 Bms0IOpSts_18FFEBF3 0 "Normal" 1 "Low downgraded" 2 "Failure" 3 "Invalid" ;
VAL_ 2566908915 Bms0IChgCompl_18FFEBF3 0 "Not Completed" 1 "Completed" ;
VAL_ 2566908915 Bms0IPwrDistributed_18FFEBF3 0 "Not Distributed or In Progress" 1 "Distributed" ;
VAL_ 2566844672 ParkBrkSw 0 "Not set" 1 "Set" 2 "Error" 3 "Not Available" ;
VAL_ 2566844672 WhBasedVehSpeed 65024 "Error" 65535 "Not_Available" ;
VAL_ 2566844672 CcActv 0 "Off" 1 "On" 2 "Error" 3 "Not Available" ;
VAL_ 2566844672 BrkSw 0 "Released" 1 "Depressed" 2 "Error" 3 "Not Available" ;
VAL_ 2566844672 CltSw 0 "Released" 1 "Depressed" 2 "Error" 3 "Not Available" ;
VAL_ 2566844672 PtoGovSts 0 "Off/Disabled" 1 "Hold" 2 "Remote Hold" 3 "Standby" 4 "Remote Standby" 5 "Set" 6 "Dec/Coast" 7 "Resume" 8 "Accelerate" 9 "Accelerator Override" 10 "Preprogr. set speed 1" 11 "Preprogr. set speed 2" 12 "Preprogr. set speed 3" 13 "Preprogr. set speed 4" 14 "Preprogr. set speed 5" 15 "Preprogr. set speed 6" 16 "Preprogr. set speed 7" 17 "Preprogr. set speed 8" 18 "Set speed memory 1" 19 "Set speed memory 2" 20 "Set speed memory 3" 30 "Not defined" 31 "Not Available" ;
VAL_ 2566844672 CcSts 0 "Off/Disabled" 1 "Hold" 2 "Accelerate" 3 "Decelerate" 4 "Resume" 5 "Set" 6 "Accelerator Override" 7 "Not Available" ;
VAL_ 2566865139 CoolSts 0 "No_cooling" 1 "Off" 2 "On" 3 "Refuelling" 4 "Warning" 5 "Error" 6 "Chiller_No_Can" 7 "MaintenChillerManualCirculat" ;
VAL_ 2566802967 PosOfDoors 0 "At least 1 door is open" 1 "Closing last door" 2 "All doors closed" 14 "Error" 15 "Not Available" ;
VAL_ 2566802967 Ramp_WhChairLiftPos 0 "Inside bus" 1 "Outside bus" 2 "Error" 3 "Not Available" ;
VAL_ 2566802967 Sts2OfDoors 0 "All bus doors are disabled" 1 "At least 1 bus door enabled" 2 "Error" 3 "Not Available" ;
VAL_ 2566759703 LckStsOfDoor1 0 "Unlocked" 1 "Locked" 2 "Error" 3 "Not Available" ;
VAL_ 2566759703 OpenStsOfDoor1 0 "Door closed" 1 "Door opened" 2 "Error" 3 "Not Available" ;
VAL_ 2566759703 EnaStsOfDoor1 0 "Door disabled" 1 "Door enabled" 2 "Error" 3 "Not Available" ;
VAL_ 2566759703 LckStsOfDoor2 0 "Unlocked" 1 "Locked" 2 "Error" 3 "Not Available" ;
VAL_ 2566759703 OpenStsOfDoor2 0 "Door closed" 1 "Door opened" 2 "Error" 3 "Not Available" ;
VAL_ 2566759703 EnaStsOfDoor2 0 "Door disabled" 1 "Door enabled" 2 "Error" 3 "Not Available" ;
VAL_ 2566759703 LckStsOfDoor3 0 "Unlocked" 1 "Locked" 2 "Error" 3 "Not Available" ;
VAL_ 2566759703 OpenStsOfDoor3 0 "Door closed" 1 "Door opened" 2 "Error" 3 "Not Available" ;
VAL_ 2566759703 EnaStsOfDoor3 0 "Door disabled" 1 "Door enabled" 2 "Error" 3 "Not Available" ;
VAL_ 2566759703 LckStsOfDoor4 0 "Unlocked" 1 "Locked" 2 "Error" 3 "Not Available" ;
VAL_ 2566759703 OpenStsOfDoor4 0 "Door closed" 1 "Door opened" 2 "Error" 3 "Not Available" ;
VAL_ 2566759703 EnaStsOfDoor4 0 "Door disabled" 1 "Door enabled" 2 "Error" 3 "Not Available" ;
VAL_ 2566759703 LckStsOfDoor5 0 "Unlocked" 1 "Locked" 2 "Error" 3 "Not Available" ;
VAL_ 2566759703 OpenStsOfDoor5 0 "Door closed" 1 "Door opened" 2 "Error" 3 "Not Available" ;
VAL_ 2566759703 EnaStsOfDoor5 0 "Door disabled" 1 "Door enabled" 2 "Error" 3 "Not Available" ;
VAL_ 2566759703 LckStsOfDoor6 0 "Unlocked" 1 "Locked" 2 "Error" 3 "Not Available" ;
VAL_ 2566759703 OpenStsOfDoor6 0 "Door closed" 1 "Door opened" 2 "Error" 3 "Not Available" ;
VAL_ 2566759703 EnaStsOfDoor6 0 "Door disabled" 1 "Door enabled" 2 "Error" 3 "Not Available" ;
VAL_ 2566759703 LckStsOfDoor7 0 "Unlocked" 1 "Locked" 2 "Error" 3 "Not Available" ;
VAL_ 2566759703 OpenStsOfDoor7 0 "Door closed" 1 "Door opened" 2 "Error" 3 "Not Available" ;
VAL_ 2566759703 EnaStsOfDoor7 0 "Door disabled" 1 "Door enabled" 2 "Error" 3 "Not Available" ;
VAL_ 2566759703 LckStsOfDoor8 0 "Unlocked" 1 "Locked" 2 "Error" 3 "Not Available" ;
VAL_ 2566759703 OpenStsOfDoor8 0 "Door closed" 1 "Door opened" 2 "Error" 3 "Not Available" ;
VAL_ 2566759703 EnaStsOfDoor8 0 "Door disabled" 1 "Door enabled" 2 "Error" 3 "Not Available" ;
VAL_ 2566759703 LckStsOfDoor9 0 "Unlocked" 1 "Locked" 2 "Error" 3 "Not Available" ;
VAL_ 2566759703 OpenStsOfDoor9 0 "Door closed" 1 "Door opened" 2 "Error" 3 "Not Available" ;
VAL_ 2566759703 EnaStsOfDoor9 0 "Door disabled" 1 "Door enabled" 2 "Error" 3 "Not Available" ;
VAL_ 2566759703 LckStsOfDoor10 0 "Unlocked" 1 "Locked" 2 "Error" 3 "Not Available" ;
VAL_ 2566759703 OpenStsOfDoor10 0 "Door closed" 1 "Door opened" 2 "Error" 3 "Not Available" ;
VAL_ 2566759703 EnaStsOfDoor10 0 "Door disabled" 1 "Door enabled" 2 "Error" 3 "Not Available" ;
VAL_ 2566849774 DrivItsPersDataCons 0 "Refused" 1 "Permitted" ;
VAL_ 2566849774 CodriverItsPersDataCons 0 "Refused" 1 "Permitted" ;
VAL_ 2566849774 DrivVdoPersDataCons 0 "Refused" 1 "Permitted" ;
VAL_ 2566849774 CodriverVdoPersDataCons 0 "Refused" 1 "Permitted" ;
VAL_ 2566834688 ProtLamp 0 "Off" 1 "On" ;
VAL_ 2566834691 ProtLamp_18FECA03 0 "Off" 1 "On" ;
VAL_ 2566834699 ProtLamp_18FECA0B 0 "Off" 1 "On" ;
VAL_ 2566834704 ProtLamp_18FECA10 0 "Off" 1 "On" ;
VAL_ 2566834711 ProtLamp_18FECA17 0 "Off" 1 "On" ;
VAL_ 2566834716 ProtLamp_18FECA1C 0 "Off" 1 "On" ;
VAL_ 2566834717 ProtLamp_18FECA1D 0 "Off" 1 "On" ;
VAL_ 2566834721 ProtLamp_18FECA21 0 "Off" 1 "On" ;
VAL_ 2566834727 ProtLamp_18FECA27 0 "Off" 1 "On" ;
VAL_ 2566834734 ProtLamp_18FECA2E 0 "Off" 1 "On" ;
VAL_ 2566834735 ProtLamp_18FECA2F 0 "Off" 1 "On" ;
VAL_ 2566834739 ProtLamp_18FECA33 0 "Off" 1 "On" ;
VAL_ 2566834744 ProtLamp_18FECA38 0 "Off" 1 "On" ;
VAL_ 2566834752 ProtLamp_18FECA40 0 "Off" 1 "On" ;
VAL_ 2566834761 ProtLamp_18FECA49 0 "Off" 1 "On" ;
VAL_ 2566834762 ProtLamp_18FECA4A 0 "Off" 1 "On" ;
VAL_ 2566834778 ProtLamp_18FECA5A 0 "Off" 1 "On" ;
VAL_ 2566834782 ProtLamp_18FECA5E 0 "Off" 1 "On" ;
VAL_ 2566834814 ProtLamp_18FECA7E 0 "Off" 1 "On" ;
VAL_ 2566834832 ProtLamp_18FECA90 0 "Off" 1 "On" ;
VAL_ 2566834833 ProtLamp_18FECA91 0 "Off" 1 "On" ;
VAL_ 2566834834 ProtLamp_18FECA92 0 "Off" 1 "On" ;
VAL_ 2566834844 ProtLamp_18FECA9C 0 "Off" 1 "On" ;
VAL_ 2566834846 ProtLamp_18FECA9E 0 "Off" 1 "On" ;
VAL_ 2566834848 ProtLamp_18FECAA0 0 "Off" 1 "On" ;
VAL_ 2566834882 ProtLamp_18FECAC2 0 "Off" 1 "On" ;
VAL_ 2566834920 ProtLamp_18FECAE8 0 "Off" 1 "On" ;
VAL_ 2566834926 ProtLamp_18FECAEE 0 "Off" 1 "On" ;
VAL_ 2566834931 ProtLamp_18FECAF3 0 "Off" 1 "On" ;
VAL_ 2566834972 ProtLamp_18FECB1C 0 "Off" 1 "On" ;
VAL_ 2566834973 ProtLamp_18FECB1D 0 "Off" 1 "On" ;
VAL_ 2566835102 ProtLamp_18FECB9E 0 "Off" 1 "On" ;
VAL_ 2633943642 ProtLamp_1CFECA5A 0 "Off" 1 "On" ;
VAL_ 2633943680 ProtLamp_1CFECA80 0 "Off" 1 "On" ;
VAL_ 2566856773 DoorId 0 "Not used" 1 "Door_1" 2 "Door_2" 3 "Door_3" 4 "Door_4" 5 "Door_5" 6 "Door_6" 7 "Door_7" ;
VAL_ 2566749184 DpfLampCmd 0 "Off" 1 "On, solid" 2 "Reserved" 3 "Reserved" 4 "On, fast blink (1 HZ)" 5 "On, very fast blink" 6 "Reserved" 7 "Not Available" ;
VAL_ 2566749184 AtDpfPregenSts 0 "Not active" 1 "Active" 2 "Reserved" 3 "Not Available" ;
VAL_ 2566749184 AtDpfAregenSts 0 "Not active" 1 "Active" 2 "Needed, automatically imminent" 3 "Not Available" ;
VAL_ 2566749184 AtDpfSts 0 "Not needed" 1 "Needed, lowest level" 2 "Needed, moderate level" 3 "Needed,highest level" 4 "Reserved" 5 "Reserved" 6 "Reserved" 7 "Not Available" ;
VAL_ 2566749184 DpfAregenInhSts 0 "Not inhibited" 1 "Inhibited" 2 "Reserved" 3 "Not Available" ;
VAL_ 2561126730 ValidAcc 0 "False" 1 "True" 2 "Reserved" 3 "Not available" ;
VAL_ 2561126730 BenefitAcc 0 "False" 1 "True" 2 "Reserved" 3 "Not available" ;
VAL_ 2561126986 EventAcc 0 "NoEvent" 1 "AccCEnabled" 2 "AccDisabled" 3 "AccTriggered" ;
VAL_ 2561127242 ValidAcceleration 0 "False" 1 "True" 2 "Reserved" 3 "Not available" ;
VAL_ 2561127242 BenefitAcceleration 0 "False" 1 "True" 2 "Reserved" 3 "Not available" ;
VAL_ 2561127498 EventAccelerator 0 "NoEvent" 1 "GoodAcc" 2 "BadAcc" ;
VAL_ 2561127754 ValidAebs 0 "False" 1 "True" 2 "Reserved" 3 "Not available" ;
VAL_ 2561127754 BenefitAebs 0 "False" 1 "True" 2 "Reserved" 3 "Not available" ;
VAL_ 2561128010 EventAebs 0 "NoEvent" 1 "AebsEnabled" 2 "AebsDisabled" 3 "AebsTriggered" ;
VAL_ 2561128266 ValidAirC 0 "False" 1 "True" 2 "Reserved" 3 "Not available" ;
VAL_ 2561128266 BenefitAirC 0 "False" 1 "True" 2 "Reserved" 3 "Not available" ;
VAL_ 2561144138 ValidAttention 0 "False" 1 "True" 2 "Reserved" 3 "Not available" ;
VAL_ 2561144138 BenefitAttention 0 "False" 1 "True" 2 "Reserved" 3 "Not available" ;
VAL_ 2561128778 ValidAuxBrake 0 "False" 1 "True" 2 "Reserved" 3 "Not available" ;
VAL_ 2561128778 BenefitAuxBrake 0 "False" 1 "True" 2 "Reserved" 3 "Not available" ;
VAL_ 2561129034 EventAuxBrake 0 "NoEvent" 1 "GoodAuxBrake" 2 "BadAuxBrake" ;
VAL_ 2561145930 ValidBsis 0 "False" 1 "True" 2 "Reserved" 3 "Not available" ;
VAL_ 2561145930 BenefitBsis 0 "False" 1 "True" 2 "Reserved" 3 "Not available" ;
VAL_ 2561129290 ValidCare 0 "False" 1 "True" 2 "Reserved" 3 "Not available" ;
VAL_ 2561129290 BenefitCare 0 "False" 1 "True" 2 "Reserved" 3 "Not available" ;
VAL_ 2561129546 ResetEcoA 0 "False" 1 "True" 2 "Reserved" 3 "Not available" ;
VAL_ 2561129546 ResetEcoB 0 "False" 1 "True" 2 "Reserved" 3 "Not available" ;
VAL_ 2561130058 ValidComfort 0 "False" 1 "True" 2 "Reserved" 3 "Not available" ;
VAL_ 2561130058 BenefitComfort 0 "False" 1 "True" 2 "Reserved" 3 "Not available" ;
VAL_ 2561130314 ValidDas 0 "False" 1 "True" 2 "Reserved" 3 "Not available" ;
VAL_ 2561130314 BenefitDas 0 "False" 1 "True" 2 "Reserved" 3 "Not available" ;
VAL_ 2561140554 EventDas 0 "NoEvent" 1 "DasWarning" 2 "DasStop" ;
VAL_ 2561130570 ValidDeceleration 0 "False" 1 "True" 2 "Reserved" 3 "Not available" ;
VAL_ 2561130570 BenefitDeceleration 0 "False" 1 "True" 2 "Reserved" 3 "Not available" ;
VAL_ 2561143882 ValidDriverAwareness 0 "False" 1 "True" 2 "Reserved" 3 "Not available" ;
VAL_ 2561143882 BenefitDriverAwareness 0 "False" 1 "True" 2 "Reserved" 3 "Not available" ;
VAL_ 2561130826 ValidEcoMode 0 "False" 1 "True" 2 "Reserved" 3 "Not available" ;
VAL_ 2561130826 BenefitEcoMode 0 "False" 1 "True" 2 "Reserved" 3 "Not available" ;
VAL_ 2561131338 ValidEngineUse 0 "False" 1 "True" 2 "Reserved" 3 "Not available" ;
VAL_ 2561131338 BenefitEngineUse 0 "False" 1 "True" 2 "Reserved" 3 "Not available" ;
VAL_ 2561131594 ValFuel 0 "False" 1 "True" 2 "Reserved" 3 "Not available" ;
VAL_ 2561131594 BenfFuel 0 "False" 1 "True" 2 "Reserved" 3 "Not available" ;
